VERSION ""

NS_ :

BS_:

BU_: FUSION ZONE_FR ZONE_DR DKC BodyZone_DR BodyZone_PS DataCenter ZONE_ML ZONE_MR

BO_ 778 zGW_CANFr1: 32 ZONE_FR
 SG_ EAC_Temp : 39|8@0+ (1,-40) [0|210] "Deg^C" FUSION
 SG_ EAC_DrvVoltFalt : 63|1@0+ (1,0) [0|1] "" FUSION
 SG_ EAC_MotorLackFalt : 62|1@0+ (1,0) [0|1] "" FUSION
 SG_ EAC_OvLoadFalt : 61|1@0+ (1,0) [0|1] "" FUSION
 SG_ EAC_TempSnsrFalt : 60|1@0+ (1,0) [0|1] "" FUSION
 SG_ COMP_ComLost : 58|1@0+ (1,0) [0|1] "" FUSION
 SG_ COMP_IPM_HWFLt : 57|1@0+ (1,0) [0|1] "" FUSION
 SG_ COMP_IPM_TempOverFlt : 56|1@0+ (1,0) [0|1] "" FUSION
 SG_ COMP_CurOverProtect : 71|1@0+ (1,0) [0|1] "" FUSION
 SG_ COMP_VoltOverErr : 70|1@0+ (1,0) [0|1] "" FUSION
 SG_ COMP_VoltLessErr : 69|1@0+ (1,0) [0|1] "" FUSION
 SG_ COMP_CtrlCircFlt : 68|1@0+ (1,0) [0|1] "" FUSION
 SG_ COMP_Sta : 67|2@0+ (1,0) [0|3] "" FUSION
 SG_ COMP_Init : 65|1@0+ (1,0) [0|1] "" FUSION
 SG_ COMP_SpdVaild : 64|1@0+ (1,0) [0|1] "" FUSION
 SG_ EAC_MotCrt : 79|8@0+ (0.2,0) [0|51] "A" FUSION
 SG_ COMP_CurVaild : 87|1@0+ (1,0) [0|1] "" FUSION
 SG_ COMP_VoltVaild : 86|1@0+ (1,0) [0|1] "" FUSION
 SG_ COMP_StatorSpd : 85|14@0+ (1,0) [0|8500] "RPM" FUSION
 SG_ COMP_ConCur : 103|16@0+ (0.02,0) [0|1310.7] "A" FUSION
 SG_ COMP_ConVolt : 119|16@0+ (0.02,0) [0|1310.7] "V" FUSION
 SG_ COMP_ActualPwr : 228|13@0+ (1,0) [0|6000] "W" FUSION
 SG_ PTC1_PowerConsumption : 31|8@0+ (0.1,0) [0|25.3] "KW" FUSION
 SG_ PTC1_IGBTTem : 7|8@0+ (1,-40) [-40|213] "Deg^C" FUSION
 SG_ PTC1_ClntTempOtlt : 15|8@0+ (1,-40) [-40|100] "Deg^C" FUSION
 SG_ PTC1_ClntTempInlt : 23|8@0+ (1,-40) [-40|100] "Deg^C" FUSION
 SG_ PTC1_ActuHiCrnt : 47|8@0+ (0.25,0) [0|63.25] "A" FUSION
 SG_ PTC1_WrkngSts : 55|2@0+ (1,0) [0|3] "" FUSION
 SG_ PTC1_ClntInltOverTemProtn : 53|1@0+ (1,0) [0|1] "" FUSION
 SG_ PTC1_ClntInltTemSnsrFlt : 52|1@0+ (1,0) [0|1] "" FUSION
 SG_ PTC1_ClntOtltOverTemProtn : 51|1@0+ (1,0) [0|1] "" FUSION
 SG_ PTC1_ClntOtltTemSnsrFlt : 50|1@0+ (1,0) [0|1] "" FUSION
 SG_ PTC1_CommError : 49|1@0+ (1,0) [0|1] "" FUSION
 SG_ PTC1_CoreOrIGBTOpenErr : 48|1@0+ (1,0) [0|1] "" FUSION
 SG_ PTC1_HiCrntSnsrFlt : 59|1@0+ (1,0) [0|1] "" FUSION
 SG_ PTC1_HVDisconnectProtn : 135|1@0+ (1,0) [0|1] "" FUSION
 SG_ PTC1_HVOverCrntProtn : 134|1@0+ (1,0) [0|1] "" FUSION
 SG_ PTC1_IGBTOverTemProtn : 133|1@0+ (1,0) [0|1] "" FUSION
 SG_ PTC1_IGBTShrtErr : 132|1@0+ (1,0) [0|1] "" FUSION
 SG_ PTC1_IGBTTemSnsrFlt : 131|1@0+ (1,0) [0|1] "" FUSION
 SG_ PTC1_MmryFlt : 130|1@0+ (1,0) [0|1] "" FUSION
 SG_ PTC1_PCBOverTempProtn : 129|1@0+ (1,0) [0|1] "" FUSION
 SG_ PTC1_PCBTempSnsrFlt : 128|1@0+ (1,0) [0|1] "" FUSION
 SG_ PTC1_VbatVtgProtn : 143|1@0+ (1,0) [0|1] "" FUSION
 SG_ PTC1_VbatVtgSnsrFlt : 142|1@0+ (1,0) [0|1] "" FUSION
 SG_ PTC1_VbatVtgUnstable : 141|1@0+ (1,0) [0|1] "" FUSION

BO_ 804 zGW_LINDr2: 48 ZONE_DR
 SG_ ACT5_Stop_mode_status : 71|2@0+ (1,0) [0|3] "" FUSION
 SG_ ACT5_Rotation_direction_status : 69|2@0+ (1,0) [0|3] "" FUSION
 SG_ ACT5_Emergency_run_position_status : 67|2@0+ (1,0) [0|3] "" FUSION
 SG_ ACT5_Emergency_run_release_status : 65|2@0+ (1,0) [0|3] "" FUSION
 SG_ ACT5_Actuator_address_status : 79|8@0+ (1,0) [0|255] "" FUSION
 SG_ ACT5_Special_functions : 85|2@0+ (1,0) [0|3] "" FUSION
 SG_ ACT5_Self_holding_torque : 83|2@0+ (1,0) [0|3] "" FUSION
 SG_ ACT5_Movement_direction : 81|2@0+ (1,0) [0|3] "" FUSION
 SG_ ACT5_Actual_position_of_actuator : 95|16@0+ (1,0) [0|65535] "" FUSION
 SG_ ACT5_Speed_status : 111|4@0+ (1,0) [0|15] "" FUSION
 SG_ ACT5_Position_specification_status : 107|2@0+ (1,0) [0|3] "" FUSION
 SG_ ACT5_Applied_holding_current_status : 105|2@0+ (1,0) [0|3] "" FUSION
 SG_ ACT5_Reset : 119|2@0+ (1,0) [0|3] "" FUSION
 SG_ ACT5_Stall_occurred : 117|2@0+ (1,0) [0|3] "" FUSION
 SG_ ACT5_Stall_detection_release_status : 115|2@0+ (1,0) [0|3] "" FUSION
 SG_ ACT5_Emergency_run_occurred : 113|2@0+ (1,0) [0|3] "" FUSION
 SG_ ACT5_Supply_voltage : 127|2@0+ (1,0) [0|3] "" FUSION
 SG_ ACT5_Electrical_defect : 125|2@0+ (1,0) [0|3] "" FUSION
 SG_ ACT5_Over_temperature : 123|2@0+ (1,0) [0|3] "" FUSION
 SG_ ACT5_Response_Error : 120|1@0+ (1,0) [0|1] "" FUSION
 SG_ ACT4_Stop_mode_status : 135|2@0+ (1,0) [0|3] "" FUSION
 SG_ ACT4_Rotation_direction_status : 133|2@0+ (1,0) [0|3] "" FUSION
 SG_ ACT4_Emergency_run_position_status : 131|2@0+ (1,0) [0|3] "" FUSION
 SG_ ACT4_Emergency_run_release_status : 129|2@0+ (1,0) [0|3] "" FUSION
 SG_ ACT4_Actuator_address_status : 143|8@0+ (1,0) [0|255] "" FUSION
 SG_ ACT4_Special_functions : 149|2@0+ (1,0) [0|3] "" FUSION
 SG_ ACT4_Self_holding_torque : 147|2@0+ (1,0) [0|3] "" FUSION
 SG_ ACT4_Movement_direction : 145|2@0+ (1,0) [0|3] "" FUSION
 SG_ ACT4_Actual_position_of_actuator : 159|16@0+ (1,0) [0|65535] "" FUSION
 SG_ ACT4_Speed_status : 175|4@0+ (1,0) [0|15] "" FUSION
 SG_ ACT4_Position_specification_status : 171|2@0+ (1,0) [0|3] "" FUSION
 SG_ ACT4_Applied_holding_current_status : 169|2@0+ (1,0) [0|3] "" FUSION
 SG_ ACT4_Reset : 183|2@0+ (1,0) [0|3] "" FUSION
 SG_ ACT4_Stall_occurred : 181|2@0+ (1,0) [0|3] "" FUSION
 SG_ ACT4_Stall_detection_release_status : 179|2@0+ (1,0) [0|3] "" FUSION
 SG_ ACT4_Emergency_run_occurred : 177|2@0+ (1,0) [0|3] "" FUSION
 SG_ ACT4_Supply_voltage : 191|2@0+ (1,0) [0|3] "" FUSION
 SG_ ACT4_Electrical_defect : 189|2@0+ (1,0) [0|3] "" FUSION
 SG_ ACT4_Over_temperature : 187|2@0+ (1,0) [0|3] "" FUSION
 SG_ ACT4_Response_Error : 184|1@0+ (1,0) [0|1] "" FUSION
 SG_ ACT3_Stop_mode_status : 199|2@0+ (1,0) [0|3] "" FUSION
 SG_ ACT3_Rotation_direction_status : 197|2@0+ (1,0) [0|3] "" FUSION
 SG_ ACT3_Emergency_run_position_status : 195|2@0+ (1,0) [0|3] "" FUSION
 SG_ ACT3_Emergency_run_release_status : 193|2@0+ (1,0) [0|3] "" FUSION
 SG_ ACT3_Actuator_address_status : 207|8@0+ (1,0) [0|255] "" FUSION
 SG_ ACT3_Special_functions : 213|2@0+ (1,0) [0|3] "" FUSION
 SG_ ACT3_Self_holding_torque : 211|2@0+ (1,0) [0|3] "" FUSION
 SG_ ACT3_Movement_direction : 209|2@0+ (1,0) [0|3] "" FUSION
 SG_ ACT3_Actual_position_of_actuator : 223|16@0+ (1,0) [0|65535] "" FUSION
 SG_ ACT3_Speed_status : 239|4@0+ (1,0) [0|15] "" FUSION
 SG_ ACT3_Position_specification_status : 235|2@0+ (1,0) [0|3] "" FUSION
 SG_ ACT3_Applied_holding_current_status : 233|2@0+ (1,0) [0|3] "" FUSION
 SG_ ACT3_Reset : 247|2@0+ (1,0) [0|3] "" FUSION
 SG_ ACT3_Stall_occurred : 245|2@0+ (1,0) [0|3] "" FUSION
 SG_ ACT3_Stall_detection_release_status : 243|2@0+ (1,0) [0|3] "" FUSION
 SG_ ACT3_Emergency_run_occurred : 241|2@0+ (1,0) [0|3] "" FUSION
 SG_ ACT3_Supply_voltage : 255|2@0+ (1,0) [0|3] "" FUSION
 SG_ ACT3_Electrical_defect : 253|2@0+ (1,0) [0|3] "" FUSION
 SG_ ACT3_Over_temperature : 251|2@0+ (1,0) [0|3] "" FUSION
 SG_ ACT3_Response_Error : 248|1@0+ (1,0) [0|1] "" FUSION
 SG_ ACT2_Stop_mode_status : 263|2@0+ (1,0) [0|3] "" FUSION
 SG_ ACT2_Rotation_direction_status : 261|2@0+ (1,0) [0|3] "" FUSION
 SG_ ACT2_Emergency_run_position_status : 259|2@0+ (1,0) [0|3] "" FUSION
 SG_ ACT2_Emergency_run_release_status : 257|2@0+ (1,0) [0|3] "" FUSION
 SG_ ACT2_Actuator_address_status : 271|8@0+ (1,0) [0|255] "" FUSION
 SG_ ACT2_Special_functions : 277|2@0+ (1,0) [0|3] "" FUSION
 SG_ ACT2_Self_holding_torque : 275|2@0+ (1,0) [0|3] "" FUSION
 SG_ ACT2_Movement_direction : 273|2@0+ (1,0) [0|3] "" FUSION
 SG_ ACT2_Actual_position_of_actuator : 287|16@0+ (1,0) [0|65535] "" FUSION
 SG_ ACT2_Speed_status : 303|4@0+ (1,0) [0|15] "" FUSION
 SG_ ACT2_Position_specification_status : 299|2@0+ (1,0) [0|3] "" FUSION
 SG_ ACT2_Applied_holding_current_status : 297|2@0+ (1,0) [0|3] "" FUSION
 SG_ ACT2_Reset : 311|2@0+ (1,0) [0|3] "" FUSION
 SG_ ACT2_Stall_occurred : 309|2@0+ (1,0) [0|3] "" FUSION
 SG_ ACT2_Stall_detection_release_status : 307|2@0+ (1,0) [0|3] "" FUSION
 SG_ ACT2_Emergency_run_occurred : 305|2@0+ (1,0) [0|3] "" FUSION
 SG_ ACT2_Supply_voltage : 319|2@0+ (1,0) [0|3] "" FUSION
 SG_ ACT2_Electrical_defect : 317|2@0+ (1,0) [0|3] "" FUSION
 SG_ ACT2_Over_temperature : 315|2@0+ (1,0) [0|3] "" FUSION
 SG_ ACT2_Response_Error : 312|1@0+ (1,0) [0|1] "" FUSION
 SG_ ACT1_Stop_mode_status : 327|2@0+ (1,0) [0|3] "" FUSION
 SG_ ACT1_Rotation_direction_status : 325|2@0+ (1,0) [0|3] "" FUSION
 SG_ ACT1_Emergency_run_position_status : 323|2@0+ (1,0) [0|3] "" FUSION
 SG_ ACT1_Emergency_run_release_status : 321|2@0+ (1,0) [0|3] "" FUSION
 SG_ ACT1_Actuator_address_status : 335|8@0+ (1,0) [0|255] "" FUSION
 SG_ ACT1_Special_functions : 341|2@0+ (1,0) [0|3] "" FUSION
 SG_ ACT1_Self_holding_torque : 339|2@0+ (1,0) [0|3] "" FUSION
 SG_ ACT1_Movement_direction : 337|2@0+ (1,0) [0|3] "" FUSION
 SG_ ACT1_Actual_position_of_actuator : 351|16@0+ (1,0) [0|65535] "" FUSION
 SG_ ACT1_Speed_status : 367|4@0+ (1,0) [0|15] "" FUSION
 SG_ ACT1_Position_specification_status : 363|2@0+ (1,0) [0|3] "" FUSION
 SG_ ACT1_Applied_holding_current_status : 361|2@0+ (1,0) [0|3] "" FUSION
 SG_ ACT1_Reset : 375|2@0+ (1,0) [0|3] "" FUSION
 SG_ ACT1_Stall_occurred : 373|2@0+ (1,0) [0|3] "" FUSION
 SG_ ACT1_Stall_detection_release_status : 371|2@0+ (1,0) [0|3] "" FUSION
 SG_ ACT1_Emergency_run_occurred : 369|2@0+ (1,0) [0|3] "" FUSION
 SG_ ACT1_Supply_voltage : 383|2@0+ (1,0) [0|3] "" FUSION
 SG_ ACT1_Electrical_defect : 381|2@0+ (1,0) [0|3] "" FUSION
 SG_ ACT1_Over_temperature : 379|2@0+ (1,0) [0|3] "" FUSION
 SG_ ACT1_Response_Error : 376|1@0+ (1,0) [0|1] "" FUSION

BO_ 965 ZONE_DR_Version: 48 ZONE_DR
 SG_ ZONE_DR_SW_Var1 : 135|8@0+ (1,0) [0|255] "" FUSION
 SG_ ZONE_DR_SW_Country2 : 127|8@0+ (1,0) [0|255] "" FUSION
 SG_ ZONE_DR_SW_Country1 : 119|8@0+ (1,0) [0|255] "" FUSION
 SG_ ZONE_DR_SW_Patch2 : 111|8@0+ (1,0) [0|255] "" FUSION
 SG_ ZONE_DR_SW_Patch1 : 103|8@0+ (1,0) [0|255] "" FUSION
 SG_ ZONE_DR_SW_Minor2 : 95|8@0+ (1,0) [0|255] "" FUSION
 SG_ ZONE_DR_SW_Minor1 : 87|8@0+ (1,0) [0|255] "" FUSION
 SG_ ZONE_DR_SW_Major2 : 79|8@0+ (1,0) [0|255] "" FUSION
 SG_ ZONE_DR_SW_Major1 : 71|8@0+ (1,0) [0|255] "" FUSION
 SG_ ZONE_DR_SW_Controller2 : 63|8@0+ (1,0) [0|255] "" FUSION
 SG_ ZONE_DR_SW_Controller1 : 55|8@0+ (1,0) [0|255] "" FUSION
 SG_ ZONE_DR_SW_CarModel3 : 47|8@0+ (1,0) [0|255] "" FUSION
 SG_ ZONE_DR_SW_CarModel2 : 39|8@0+ (1,0) [0|255] "" FUSION
 SG_ ZONE_DR_SW_CarModel1 : 31|8@0+ (1,0) [0|255] "" FUSION
 SG_ ZONE_DR_HW_Ver3 : 23|8@0+ (1,0) [0|255] "" FUSION
 SG_ ZONE_DR_HW_Ver2 : 15|8@0+ (1,0) [0|255] "" FUSION
 SG_ ZONE_DR_HW_Ver1 : 7|8@0+ (1,0) [0|255] "" FUSION
 SG_ ZONE_DR_SW_dash1 : 191|8@0+ (1,0) [0|255] "" FUSION
 SG_ ZONE_DR_SW_change1 : 199|8@0+ (1,0) [0|255] "" FUSION
 SG_ ZONE_DR_SW_change2 : 207|8@0+ (1,0) [0|255] "" FUSION
 SG_ ZONE_DR_SW_dash2 : 215|8@0+ (1,0) [0|255] "" FUSION
 SG_ ZONE_DR_SW_SHA1 : 223|8@0+ (1,0) [0|255] "" FUSION
 SG_ ZONE_DR_SW_SHA2 : 231|8@0+ (1,0) [0|255] "" FUSION
 SG_ ZONE_DR_SW_SHA3 : 239|8@0+ (1,0) [0|255] "" FUSION
 SG_ ZONE_DR_SW_SHA4 : 247|8@0+ (1,0) [0|255] "" FUSION
 SG_ ZONE_DR_SW_SHA5 : 255|8@0+ (1,0) [0|255] "" FUSION
 SG_ ZONE_DR_SW_SHA6 : 263|8@0+ (1,0) [0|255] "" FUSION
 SG_ ZONE_DR_SW_SHA7 : 271|8@0+ (1,0) [0|255] "" FUSION
 SG_ ZONE_DR_SW_SHA8 : 279|8@0+ (1,0) [0|255] "" FUSION
 SG_ ZONE_DR_SW_Var5 : 183|8@0+ (1,0) [0|255] "" FUSION
 SG_ ZONE_DR_SW_Var4 : 175|8@0+ (1,0) [0|255] "" FUSION
 SG_ ZONE_DR_SW_Var3 : 167|8@0+ (1,0) [0|255] "" FUSION
 SG_ ZONE_DR_SW_Var2 : 159|8@0+ (1,0) [0|255] "" FUSION
 SG_ ZONE_DR_SW_ECUGen2 : 151|8@0+ (1,0) [0|255] "" FUSION
 SG_ ZONE_DR_SW_ECUGen1 : 143|8@0+ (1,0) [0|255] "" FUSION

BO_ 969 ZONE_FR_Version: 48 ZONE_FR
 SG_ ZONE_FR_SW_Var1 : 135|8@0+ (1,0) [0|255] "" FUSION
 SG_ ZONE_FR_SW_Country2 : 127|8@0+ (1,0) [0|255] "" FUSION
 SG_ ZONE_FR_SW_Country1 : 119|8@0+ (1,0) [0|255] "" FUSION
 SG_ ZONE_FR_SW_Patch2 : 111|8@0+ (1,0) [0|255] "" FUSION
 SG_ ZONE_FR_SW_Patch1 : 103|8@0+ (1,0) [0|255] "" FUSION
 SG_ ZONE_FR_SW_Minor2 : 95|8@0+ (1,0) [0|255] "" FUSION
 SG_ ZONE_FR_SW_Minor1 : 87|8@0+ (1,0) [0|255] "" FUSION
 SG_ ZONE_FR_SW_Major2 : 79|8@0+ (1,0) [0|255] "" FUSION
 SG_ ZONE_FR_SW_Major1 : 71|8@0+ (1,0) [0|255] "" FUSION
 SG_ ZONE_FR_SW_Controller2 : 63|8@0+ (1,0) [0|255] "" FUSION
 SG_ ZONE_FR_SW_Controller1 : 55|8@0+ (1,0) [0|255] "" FUSION
 SG_ ZONE_FR_SW_CarModel3 : 47|8@0+ (1,0) [0|255] "" FUSION
 SG_ ZONE_FR_SW_CarModel2 : 39|8@0+ (1,0) [0|255] "" FUSION
 SG_ ZONE_FR_SW_CarModel1 : 31|8@0+ (1,0) [0|255] "" FUSION
 SG_ ZONE_FR_HW_Ver3 : 23|8@0+ (1,0) [0|255] "" FUSION
 SG_ ZONE_FR_HW_Ver2 : 15|8@0+ (1,0) [0|255] "" FUSION
 SG_ ZONE_FR_HW_Ver1 : 7|8@0+ (1,0) [0|255] "" FUSION
 SG_ ZONE_FR_SW_dash1 : 191|8@0+ (1,0) [0|255] "" FUSION
 SG_ ZONE_FR_SW_change1 : 199|8@0+ (1,0) [0|255] "" FUSION
 SG_ ZONE_FR_SW_change2 : 207|8@0+ (1,0) [0|255] "" FUSION
 SG_ ZONE_FR_SW_dash2 : 215|8@0+ (1,0) [0|255] "" FUSION
 SG_ ZONE_FR_SW_SHA1 : 223|8@0+ (1,0) [0|255] "" FUSION
 SG_ ZONE_FR_SW_SHA2 : 231|8@0+ (1,0) [0|255] "" FUSION
 SG_ ZONE_FR_SW_SHA3 : 239|8@0+ (1,0) [0|255] "" FUSION
 SG_ ZONE_FR_SW_SHA4 : 247|8@0+ (1,0) [0|255] "" FUSION
 SG_ ZONE_FR_SW_SHA5 : 255|8@0+ (1,0) [0|255] "" FUSION
 SG_ ZONE_FR_SW_SHA6 : 263|8@0+ (1,0) [0|255] "" FUSION
 SG_ ZONE_FR_SW_SHA7 : 271|8@0+ (1,0) [0|255] "" FUSION
 SG_ ZONE_FR_SW_SHA8 : 279|8@0+ (1,0) [0|255] "" FUSION
 SG_ ZONE_FR_SW_ECUGen2 : 151|8@0+ (1,0) [0|255] "" FUSION
 SG_ ZONE_FR_SW_ECUGen1 : 143|8@0+ (1,0) [0|255] "" FUSION
 SG_ ZONE_FR_SW_Var5 : 183|8@0+ (1,0) [0|255] "" FUSION
 SG_ ZONE_FR_SW_Var4 : 175|8@0+ (1,0) [0|255] "" FUSION
 SG_ ZONE_FR_SW_Var3 : 167|8@0+ (1,0) [0|255] "" FUSION
 SG_ ZONE_FR_SW_Var2 : 159|8@0+ (1,0) [0|255] "" FUSION

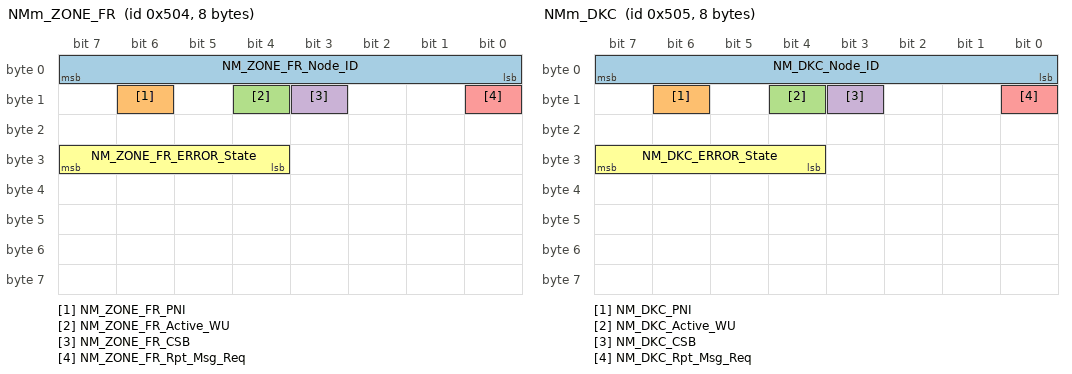
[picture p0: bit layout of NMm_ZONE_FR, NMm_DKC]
BO_ 1284 NMm_ZONE_FR: 8 ZONE_FR
 SG_ NM_ZONE_FR_Node_ID : 7|8@0+ (1,0) [0|127] "" FUSION
 SG_ NM_ZONE_FR_PNI : 14|1@0+ (1,0) [0|1] "" FUSION
 SG_ NM_ZONE_FR_Active_WU : 12|1@0+ (1,0) [0|1] "" FUSION
 SG_ NM_ZONE_FR_CSB : 11|1@0+ (1,0) [0|1] "" FUSION
 SG_ NM_ZONE_FR_Rpt_Msg_Req : 8|1@0+ (1,0) [0|1] "" FUSION
 SG_ NM_ZONE_FR_ERROR_State : 31|4@0+ (1,0) [0|8] "" FUSION

BO_ 1285 NMm_DKC: 8 DKC
 SG_ NM_DKC_Node_ID : 7|8@0+ (1,0) [0|127] "" FUSION
 SG_ NM_DKC_PNI : 14|1@0+ (1,0) [0|1] "" FUSION
 SG_ NM_DKC_Active_WU : 12|1@0+ (1,0) [0|1] "" FUSION
 SG_ NM_DKC_CSB : 11|1@0+ (1,0) [0|1] "" FUSION
 SG_ NM_DKC_Rpt_Msg_Req : 8|1@0+ (1,0) [0|1] "" FUSION
 SG_ NM_DKC_ERROR_State : 31|4@0+ (1,0) [0|8] "" FUSION

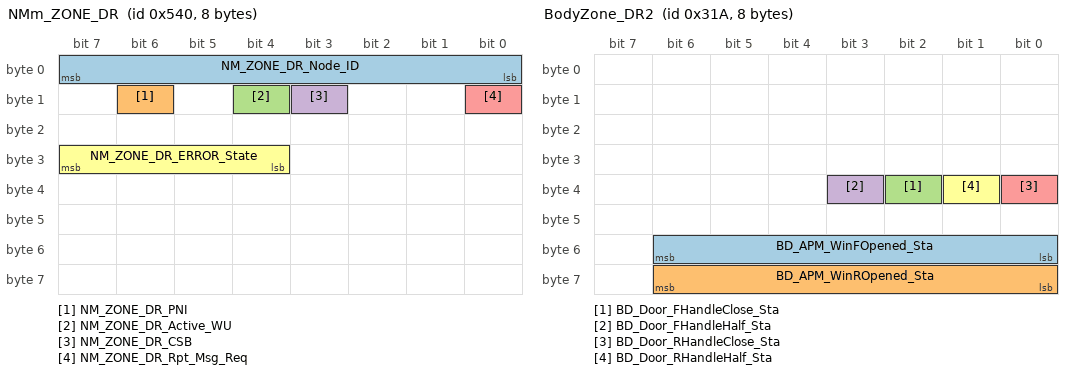
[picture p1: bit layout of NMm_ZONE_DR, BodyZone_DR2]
BO_ 1344 NMm_ZONE_DR: 8 ZONE_DR
 SG_ NM_ZONE_DR_Node_ID : 7|8@0+ (1,0) [0|127] "" FUSION
 SG_ NM_ZONE_DR_PNI : 14|1@0+ (1,0) [0|1] "" FUSION
 SG_ NM_ZONE_DR_Active_WU : 12|1@0+ (1,0) [0|1] "" FUSION
 SG_ NM_ZONE_DR_CSB : 11|1@0+ (1,0) [0|1] "" FUSION
 SG_ NM_ZONE_DR_Rpt_Msg_Req : 8|1@0+ (1,0) [0|1] "" FUSION
 SG_ NM_ZONE_DR_ERROR_State : 31|4@0+ (1,0) [0|8] "" FUSION

BO_ 1540 DiagRespFromZONE_FR: 64 ZONE_FR
 SG_ DiagRespFromZONE_FR : 455|64@0+ (1,0) [0|0] "" FUSION

BO_ 1541 DiagRespFromDKC: 32 DKC
 SG_ DiagRespFromDKC : 7|64@0+ (1,0) [0|0] "" FUSION

BO_ 1573 DiagRespFromAirPTC: 8 ZONE_DR
 SG_ DiagRespFromAirPTC : 7|64@0+ (1,0) [0|0] "" FUSION

BO_ 1589 DiagRespFromWPTC: 8 ZONE_FR
 SG_ DiagRespFromWPTC : 7|64@0+ (1,0) [0|0] "" FUSION

BO_ 1600 DiagRespFromZONE_DR: 64 ZONE_DR
 SG_ DiagRespFromZONE_DR : 455|64@0+ (1,0) [0|0] "" FUSION

BO_ 1605 DiagRespFromCompressor: 8 ZONE_FR
 SG_ DiagRespFromCompress : 7|64@0+ (1,0) [0|0] "" FUSION

BO_ 794 BodyZone_DR2: 8 BodyZone_DR
 SG_ BD_APM_WinFOpened_Sta : 54|7@0+ (1,0) [0|127] "%" FUSION
 SG_ BD_APM_WinROpened_Sta : 62|7@0+ (1,0) [0|127] "%" FUSION
 SG_ BD_Door_FHandleClose_Sta : 34|1@0+ (1,0) [0|1] "" FUSION
 SG_ BD_Door_FHandleHalf_Sta : 35|1@0+ (1,0) [0|1] "" FUSION
 SG_ BD_Door_RHandleClose_Sta : 32|1@0+ (1,0) [0|1] "" FUSION
 SG_ BD_Door_RHandleHalf_Sta : 33|1@0+ (1,0) [0|1] "" FUSION

BO_ 858 BodyZone_DR1: 12 BodyZone_DR
 SG_ BD_DSEAT_SlidPos_Sta : 74|10@0+ (1,0) [0|1023] "Pulse" FUSION
 SG_ BD_DSEAT_RecPos_Sta : 62|11@0+ (1,0) [0|2047] "Pluse" FUSION
 SG_ BD_DSEAT_FLPos_Sta : 55|9@0+ (1,0) [0|511] "Pulse" FUSION
 SG_ BD_DSEAT_RLPos_Sta : 67|9@0+ (1,0) [0|511] "Pulse" FUSION
 SG_ BD_DSEAT_Mode_Sta : 38|3@0+ (1,0) [0|7] "" FUSION
 SG_ BD_DSEAT_AntiAct_Sta : 45|1@0+ (1,0) [0|1] "" FUSION
 SG_ BD_DSEAT_Anti_Sta : 43|1@0+ (1,0) [0|1] "" FUSION
 SG_ BD_DSEAT_EntryAct_Sta : 39|1@0+ (1,0) [0|1] "" FUSION
 SG_ BD_DSEAT_EntryFun_Sta : 44|1@0+ (1,0) [0|1] "" FUSION
 SG_ BD_DSEAT_Error_Sta : 35|1@0+ (1,0) [0|1] "" FUSION
 SG_ BD_DSEAT_Vent_Sta : 34|3@0+ (1,0) [0|4] "" FUSION
 SG_ BD_DSEAT_heater_Sta : 42|3@0+ (1,0) [0|4] "" FUSION
 SG_ BD_DSEAT_MemSet_Sta : 47|2@0+ (1,0) [0|3] "" FUSION
 SG_ BD_DSEAT_StopKeepMove_Sta : 31|2@0+ (1,0) [0|3] "" FUSION

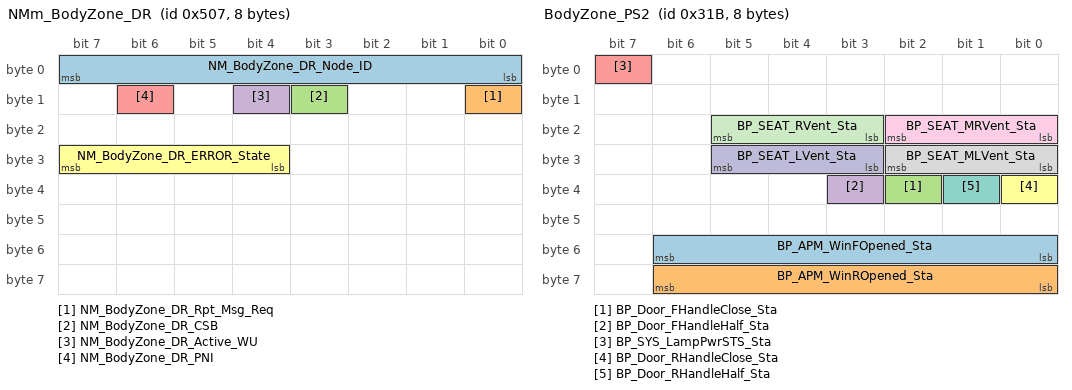
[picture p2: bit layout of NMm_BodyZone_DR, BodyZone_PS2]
BO_ 1287 NMm_BodyZone_DR: 8 BodyZone_DR
 SG_ NM_BodyZone_DR_Node_ID : 7|8@0+ (1,0) [0|127] "" FUSION
 SG_ NM_BodyZone_DR_Rpt_Msg_Req : 8|1@0+ (1,0) [0|1] "" FUSION
 SG_ NM_BodyZone_DR_CSB : 11|1@0+ (1,0) [0|1] "" FUSION
 SG_ NM_BodyZone_DR_Active_WU : 12|1@0+ (1,0) [0|1] "" FUSION
 SG_ NM_BodyZone_DR_PNI : 14|1@0+ (1,0) [0|1] "" FUSION
 SG_ NM_BodyZone_DR_ERROR_State : 31|4@0+ (1,0) [0|8] "" FUSION

BO_ 1543 DiagRespFromBodyZone_DR: 64 BodyZone_DR
 SG_ DiagRespFromBodyZone_DR : 455|64@0+ (1,0) [0|0] "" FUSION

BO_ 859 BodyZone_PS1: 32 BodyZone_PS
 SG_ BP_PTG_PowerLatch_Sta : 23|3@0+ (1,0) [0|7] "" FUSION
 SG_ BP_PTG_DebugMode_Sta : 31|1@0+ (1,0) [0|1] "" FUSION
 SG_ BP_PTG_LatchSeg_Sta : 33|2@0+ (1,0) [0|3] "" FUSION
 SG_ BP_PTG_InsideSW2_Sta : 35|2@0+ (1,0) [0|3] "" FUSION
 SG_ BP_PTG_InsideSW1_Sta : 37|2@0+ (1,0) [0|3] "" FUSION
 SG_ BP_PTG_HalfSW_Sta : 47|1@0+ (1,0) [0|1] "" FUSION
 SG_ BP_PTG_LeftDuty_Sta : 54|7@0+ (1,0) [0|127] "%" FUSION
 SG_ BP_PTG_FullSW_Sta : 55|1@0+ (1,0) [0|1] "" FUSION
 SG_ BP_PTG_RightDuty_Sta : 62|7@0+ (1,0) [0|127] "%" FUSION
 SG_ BP_PTG_NtlSW_Sta : 63|1@0+ (1,0) [0|1] "" FUSION
 SG_ BP_PTG_CinchDuty_Sta : 70|7@0+ (1,0) [0|127] "%" FUSION
 SG_ BP_PTG_StrutThermal_Sta : 71|1@0+ (1,0) [0|1] "" FUSION
 SG_ BP_PTG_LeftCur_Sta : 78|15@0+ (1,0) [0|32767] "mA" FUSION
 SG_ BP_PTG_StrutAntiPinch_Sta : 79|1@0+ (1,0) [0|1] "" FUSION
 SG_ BP_PTG_RightCur_Sta : 94|15@0+ (1,0) [0|32767] "mA" FUSION
 SG_ BP_PTG_StrutStall_Sta : 95|1@0+ (1,0) [0|1] "" FUSION
 SG_ BP_PTG_CinchCur_Sta : 110|15@0+ (1,0) [0|32767] "mA" FUSION
 SG_ BP_PTG_AbuseProtection_Sta : 111|1@0+ (1,0) [0|1] "" FUSION
 SG_ BP_PTG_ReleaseCur_Sta : 126|15@0+ (1,0) [0|32767] "mA" FUSION
 SG_ BP_PTG_LatchThermal_Sta : 127|1@0+ (1,0) [0|1] "" FUSION
 SG_ BP_PTG_LeftHallPosn_Sta : 137|10@0+ (1,0) [0|1023] "" FUSION
 SG_ BP_PTG_ErrLeftStrut_Sta : 139|2@0+ (1,0) [0|3] "" FUSION
 SG_ BP_PTG_ErrVoltage_Sta : 141|2@0+ (1,0) [0|3] "" FUSION
 SG_ BP_PTG_ErrRightStrut_Sta : 143|2@0+ (1,0) [0|3] "" FUSION
 SG_ BP_PTG_RightHallPosn_Sta : 153|10@0+ (1,0) [0|1023] "" FUSION
 SG_ BP_PTG_ErrHall_Sta : 157|2@0+ (1,0) [0|3] "" FUSION
 SG_ BP_PTG_ErrLatch_Sta : 159|2@0+ (1,0) [0|3] "" FUSION
 SG_ BP_PTG_OpenRatio_Sta : 46|7@0+ (1,0) [0|127] "%" FUSION
 SG_ BP_PTG_Active_Sta : 28|3@0+ (1,0) [0|7] "" FUSION
 SG_ BP_PTG_Sys_Sta : 30|2@0+ (1,0) [0|3] "" FUSION
 SG_ BP_PTG_RDIL_Cmd : 39|2@0+ (1,0) [0|3] "" FUSION
 SG_ BP_PTG_IsSetHeight_Sta : 24|1@0+ (1,0) [0|1] "" FUSION
 SG_ BP_PTG_Exist_Sta : 25|1@0+ (1,0) [0|1] "" FUSION
 SG_ BP_PSEAT_Vent_Sta : 182|3@0+ (1,0) [0|4] "" FUSION
 SG_ BP_PSEAT_Mode_Sta : 178|3@0+ (1,0) [0|7] "" FUSION
 SG_ BP_PSEAT_Error_Sta : 179|1@0+ (1,0) [0|1] "" FUSION
 SG_ BP_PSEAT_heater_Sta : 186|3@0+ (1,0) [0|4] "" FUSION

BO_ 1007 BodyZone_PS3: 32 BodyZone_PS
 SG_ BP_APM_WinFCurrent_Sta : 71|8@0+ (0.064,0) [0|16.32] "A" FUSION
 SG_ BP_APM_WinRCurrent_Sta : 79|8@0+ (0.064,0) [0|16.32] "A" FUSION
 SG_ BP_SYS_PowerTemp2_Sta : 7|16@0+ (0.01,-40) [-40|125] "Deg^C" FUSION
 SG_ BP_SYS_PowerTemp1_Sta : 23|16@0+ (0.01,-40) [-40|125] "Deg^C" FUSION
 SG_ BP_SYS_CtrlTemp_Sta : 39|16@0+ (0.01,-40) [-40|125] "Deg^C" FUSION
 SG_ BP_SYS_CtrlBDVolt_Sta : 51|12@0+ (0.01,0) [0|36] "V" FUSION
 SG_ BP_SEAT_HeatCurrent_Sta : 87|8@0+ (0.125,0) [0|31.875] "A" FUSION
 SG_ BP_SEAT_VentCurrent_Sta : 95|8@0+ (0.125,0) [0|31.875] "A" FUSION
 SG_ BP_Door_RCurrent_Sta : 103|8@0+ (0.125,0) [0|31.875] "A" FUSION
 SG_ BP_Door_FCurrent_Sta : 111|8@0+ (0.125,0) [0|31.875] "A" FUSION
 SG_ BP_SEAT_ReclineCurrent_Sta : 119|8@0+ (0.125,0) [0|31.875] "A" FUSION
 SG_ BP_SEAT_SlideCurrent_Sta : 127|8@0+ (0.125,0) [0|31.875] "A" FUSION
 SG_ BP_PSEAT_HeaterTemp_Sta : 135|8@0+ (0.5,-30) [-30|97.5] "Deg^C" FUSION
 SG_ BP_PTG_ACTRLatchCur_Sta : 143|8@0+ (0.125,0) [0|31.875] "A" FUSION

BO_ 971 BodyZone_PS_Version: 48 BodyZone_PS
 SG_ BP_SW_ECUGen2 : 151|8@0+ (1,0) [0|255] "" FUSION
 SG_ BP_SW_ECUGen1 : 143|8@0+ (1,0) [0|255] "" FUSION
 SG_ BP_SW_Var5 : 183|8@0+ (1,0) [0|255] "" FUSION
 SG_ BP_SW_Var4 : 175|8@0+ (1,0) [0|255] "" FUSION
 SG_ BP_SW_Var3 : 167|8@0+ (1,0) [0|255] "" FUSION
 SG_ BP_SW_Var2 : 159|8@0+ (1,0) [0|255] "" FUSION

BO_ 795 BodyZone_PS2: 8 BodyZone_PS
 SG_ BP_APM_WinFOpened_Sta : 54|7@0+ (1,0) [0|127] "%" FUSION
 SG_ BP_APM_WinROpened_Sta : 62|7@0+ (1,0) [0|127] "%" FUSION
 SG_ BP_Door_FHandleClose_Sta : 34|1@0+ (1,0) [0|1] "" FUSION
 SG_ BP_Door_FHandleHalf_Sta : 35|1@0+ (1,0) [0|1] "" FUSION
 SG_ BP_SYS_LampPwrSTS_Sta : 7|1@0+ (1,0) [0|1] "" FUSION
 SG_ BP_Door_RHandleClose_Sta : 32|1@0+ (1,0) [0|1] "" FUSION
 SG_ BP_Door_RHandleHalf_Sta : 33|1@0+ (1,0) [0|1] "" FUSION
 SG_ BP_SEAT_MLVent_Sta : 26|3@0+ (1,0) [0|7] "" FUSION
 SG_ BP_SEAT_MRVent_Sta : 18|3@0+ (1,0) [0|7] "" FUSION
 SG_ BP_SEAT_LVent_Sta : 29|3@0+ (1,0) [0|7] "" FUSION
 SG_ BP_SEAT_RVent_Sta : 21|3@0+ (1,0) [0|7] "" FUSION

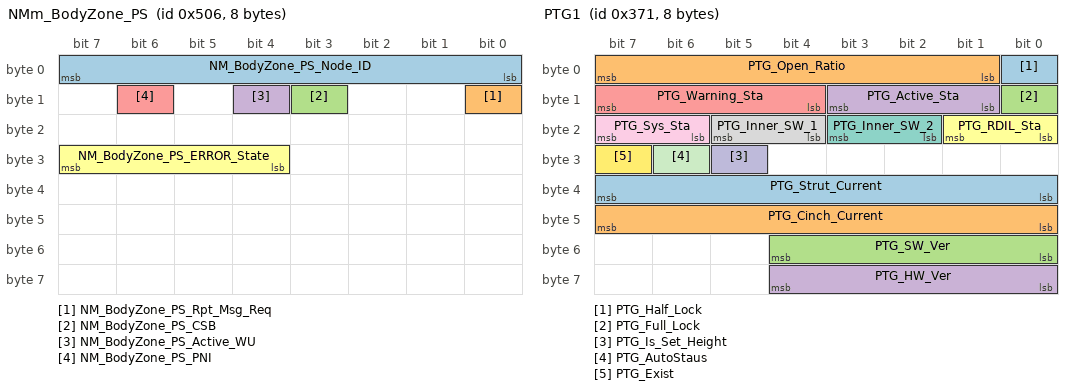
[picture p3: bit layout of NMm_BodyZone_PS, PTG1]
BO_ 1286 NMm_BodyZone_PS: 8 BodyZone_PS
 SG_ NM_BodyZone_PS_Node_ID : 7|8@0+ (1,0) [0|127] "" FUSION
 SG_ NM_BodyZone_PS_Rpt_Msg_Req : 8|1@0+ (1,0) [0|1] "" FUSION
 SG_ NM_BodyZone_PS_CSB : 11|1@0+ (1,0) [0|1] "" FUSION
 SG_ NM_BodyZone_PS_Active_WU : 12|1@0+ (1,0) [0|1] "" FUSION
 SG_ NM_BodyZone_PS_PNI : 14|1@0+ (1,0) [0|1] "" FUSION
 SG_ NM_BodyZone_PS_ERROR_State : 31|4@0+ (1,0) [0|8] "" FUSION

BO_ 1542 DiagRespFromBodyZone_PS: 64 BodyZone_PS
 SG_ DiagRespFromBodyZone_PS : 455|64@0+ (1,0) [0|0] "" FUSION

BO_ 1671 DiagPhysReqToBodyZone_DR: 64 FUSION
 SG_ DiagPhysReqToBodyZone_DR : 7|64@0+ (1,0) [0|0] "" BodyZone_DR

BO_ 1670 DiagPhysReqToBodyZone_PS: 64 FUSION
 SG_ DiagPhysReqToBodyZone_PS : 7|64@0+ (1,0) [0|0] "" BodyZone_PS

BO_ 376 FCM2: 32 FUSION
 SG_ FCM2_Checksum : 7|8@0+ (1,0) [0|255] "" ZONE_FR
 SG_ FCM2_LifeCount : 11|4@0+ (1,0) [0|14] "" ZONE_FR
 SG_ ADB_ILLAmbtSta : 17|2@0+ (1,0) [0|3] "" ZONE_FR
 SG_ ADB_VehNumVal : 21|4@0+ (1,0) [0|15] "" ZONE_FR
 SG_ ADB_FR_CMR_Sta : 23|2@0+ (1,0) [0|3] "" ZONE_FR
 SG_ ADB_VehLtAngl1Val : 31|9@0+ (0.1,-25) [-25|25] "Deg" ZONE_FR
 SG_ ADB_VehRtAngl1Val : 38|9@0+ (0.1,-25) [-25|25] "Deg" ZONE_FR
 SG_ ADB_VehLtAngl2Val : 45|9@0+ (0.1,-25) [-25|25] "Deg" ZONE_FR
 SG_ ADB_VehRtAngl2Val : 52|9@0+ (0.1,-25) [-25|25] "Deg" ZONE_FR
 SG_ ADB_VehLtAngl3Val : 59|9@0+ (0.1,-25) [-25|25] "Deg" ZONE_FR
 SG_ ADB_VehRtAngl3Val : 66|9@0+ (0.1,-25) [-25|25] "Deg" ZONE_FR
 SG_ ADB_VehLtAngl4Val : 73|9@0+ (0.1,-25) [-25|25] "Deg" ZONE_FR
 SG_ ADB_VehRtAngl4Val : 80|9@0+ (0.1,-25) [-25|25] "Deg" ZONE_FR
 SG_ ADB_VehLtAngl5Val : 103|9@0+ (0.1,-25) [-25|25] "Deg" ZONE_FR
 SG_ ADB_VehRtAngl5Val : 110|9@0+ (0.1,-25) [-25|25] "Deg" ZONE_FR
 SG_ ADB_VehLtAngl6Val : 117|9@0+ (0.1,-25) [-25|25] "Deg" ZONE_FR
 SG_ ADB_VehRtAngl6Val : 124|9@0+ (0.1,-25) [-25|25] "Deg" ZONE_FR
 SG_ ADB_VehLtAngl7Val : 131|9@0+ (0.1,-25) [-25|25] "Deg" ZONE_FR
 SG_ ADB_VehRtAngl7Val : 138|9@0+ (0.1,-25) [-25|25] "Deg" ZONE_FR
 SG_ ADB_VehLtAngl8Val : 145|9@0+ (0.1,-25) [-25|25] "Deg" ZONE_FR
 SG_ ADB_VehRtAngl8Val : 152|9@0+ (0.1,-25) [-25|25] "Deg" ZONE_FR
 SG_ ADB_VehLtAngl9Val : 175|9@0+ (0.1,-25) [-25|25] "Deg" ZONE_FR
 SG_ ADB_VehRtAngl9Val : 182|9@0+ (0.1,-25) [-25|25] "Deg" ZONE_FR
 SG_ ADB_VehLtAngl10Val : 189|9@0+ (0.1,-25) [-25|25] "Deg" ZONE_FR
 SG_ ADB_VehRtAngl10Val : 196|9@0+ (0.1,-25) [-25|25] "Deg" ZONE_FR
 SG_ ADB_VehDst1Val : 203|4@0+ (1,0) [0|15] "" ZONE_FR
 SG_ ADB_VehDst3Val : 211|4@0+ (1,0) [0|15] "" ZONE_FR
 SG_ ADB_VehDst2Val : 215|4@0+ (1,0) [0|15] "" ZONE_FR
 SG_ ADB_VehDst5Val : 219|4@0+ (1,0) [0|15] "" ZONE_FR
 SG_ ADB_VehDst4Val : 223|4@0+ (1,0) [0|15] "" ZONE_FR
 SG_ ADB_VehDst7Val : 227|4@0+ (1,0) [0|15] "" ZONE_FR
 SG_ ADB_VehDst6Val : 231|4@0+ (1,0) [0|15] "" ZONE_FR
 SG_ ADB_VehDst9Val : 235|4@0+ (1,0) [0|15] "" ZONE_FR
 SG_ ADB_VehDst8Val : 239|4@0+ (1,0) [0|15] "" ZONE_FR
 SG_ ADB_VehDst10Val : 247|4@0+ (1,0) [0|15] "" ZONE_FR

BO_ 970 BodyZone_DR_Version: 48 BodyZone_DR
 SG_ BD_SW_ECUGen2 : 151|8@0+ (1,0) [0|255] "" FUSION
 SG_ BD_SW_ECUGen1 : 143|8@0+ (1,0) [0|255] "" FUSION
 SG_ BD_SW_Var4 : 175|8@0+ (1,0) [0|255] "" FUSION
 SG_ BD_SW_Var3 : 167|8@0+ (1,0) [0|255] "" FUSION
 SG_ BD_SW_Var2 : 159|8@0+ (1,0) [0|255] "" FUSION
 SG_ BD_SW_Var5 : 183|8@0+ (1,0) [0|255] "" FUSION

BO_ 1734 DiagPhysReqToLDM_RL: 64 FUSION
 SG_ DiagPhysReqToLDM_RL : 7|64@0+ (1,0) [0|0] "" ZONE_DR

BO_ 1718 DiagPhysReqToLDM_RR: 64 FUSION
 SG_ DiagPhysReqToLDM_RR : 7|64@0+ (1,0) [0|0] "" ZONE_DR

BO_ 1702 DiagPhysReqToLDM_FL: 64 FUSION
 SG_ DiagPhysReqToLDM_FL : 7|64@0+ (1,0) [0|0] "" ZONE_FR

BO_ 1686 DiagPhysReqToLDM_FR: 64 FUSION
 SG_ DiagPhysReqToLDM_FR : 7|64@0+ (1,0) [0|0] "" ZONE_FR

BO_ 1574 DiagRespFromLDM_FL: 64 ZONE_FR
 SG_ DiagRespFromLDM_FL : 7|64@0+ (1,0) [0|0] "" FUSION

BO_ 1558 DiagRespFromLDM_FR: 64 ZONE_FR
 SG_ DiagRespFromLDM_FR : 7|64@0+ (1,0) [0|0] "" FUSION

BO_ 1606 DiagRespFromLDM_RL: 64 ZONE_DR
 SG_ DiagRespFromLDM_RL : 7|64@0+ (1,0) [0|0] "" FUSION

BO_ 1590 DiagRespFromLDM_RR: 64 ZONE_DR
 SG_ DiagRespFromLDM_RR : 7|64@0+ (1,0) [0|0] "" FUSION

BO_ 881 PTG1: 8 ZONE_DR
 SG_ PTG_Half_Lock : 0|1@0+ (1,0) [0|1] "" FUSION
 SG_ PTG_Open_Ratio : 7|7@0+ (1,0) [0|127] "%" FUSION
 SG_ PTG_Full_Lock : 8|1@0+ (1,0) [0|1] "" FUSION
 SG_ PTG_Active_Sta : 11|3@0+ (1,0) [0|7] "" FUSION
 SG_ PTG_Warning_Sta : 15|4@0+ (1,0) [0|15] "" FUSION
 SG_ PTG_RDIL_Sta : 17|2@0+ (1,0) [0|3] "" FUSION
 SG_ PTG_Inner_SW_2 : 19|2@0+ (1,0) [0|3] "" FUSION
 SG_ PTG_Inner_SW_1 : 21|2@0+ (1,0) [0|3] "" FUSION
 SG_ PTG_Sys_Sta : 23|2@0+ (1,0) [0|3] "" FUSION
 SG_ PTG_Is_Set_Height : 29|1@0+ (1,0) [0|1] "" FUSION
 SG_ PTG_AutoStaus : 30|1@0+ (1,0) [0|1] "" FUSION
 SG_ PTG_Exist : 31|1@0+ (1,0) [0|1] "" FUSION
 SG_ PTG_Strut_Current : 39|8@0+ (0.1,0) [0|25.5] "A" FUSION
 SG_ PTG_Cinch_Current : 47|8@0+ (0.1,0) [0|25.5] "A" FUSION
 SG_ PTG_SW_Ver : 52|5@0+ (1,0) [0|31] "" FUSION
 SG_ PTG_HW_Ver : 60|5@0+ (1,0) [0|31] "" FUSION

BO_ 1684 DiagPhysReqToDSEAT: 8 FUSION
 SG_ DiagPhysReqToDSEAT : 7|64@0+ (1,0) [0|0] "" ZONE_DR

BO_ 1700 DiagPhysReqToPSEAT: 8 FUSION
 SG_ DiagPhysReqToPSEAT : 7|64@0+ (1,0) [0|0] "" ZONE_DR

BO_ 1716 DiagPhysReqToPTG: 8 FUSION
 SG_ DiagPhysReqToPTG : 7|64@0+ (1,0) [0|0] "" ZONE_DR

BO_ 1556 DiagRespFromDSEAT: 8 ZONE_DR
 SG_ DiagRespFromDSEAT : 7|64@0+ (1,0) [0|0] "" FUSION

BO_ 1572 DiagRespFromPSEAT: 8 ZONE_DR
 SG_ DiagRespFromPSEAT : 7|64@0+ (1,0) [0|0] "" FUSION

BO_ 1588 DiagRespFromPTG: 8 ZONE_DR
 SG_ DiagRespFromPTG : 7|64@0+ (1,0) [0|0] "" FUSION

BO_ 854 zGW_SEAT1: 16 ZONE_DR
 SG_ PSEAT_SW_Ver : 119|16@0+ (1,0) [0|65535] "" FUSION
 SG_ PSEAT_HW_Ver : 103|16@0+ (1,0) [0|65535] "" FUSION
 SG_ DSEAT_SW_Ver : 87|16@0+ (1,0) [0|65535] "" FUSION
 SG_ DSEAT_HW_Ver : 71|16@0+ (1,0) [0|65535] "" FUSION
 SG_ DSEAT_Slid_Pos : 15|8@0+ (1,0) [0|240] "mm" FUSION
 SG_ DSEAT_RL_Pos : 23|8@0+ (1,0) [0|60] "mm" FUSION
 SG_ DSEAT_Rec_Pos : 31|8@0+ (1,0) [0|80] "Deg" FUSION
 SG_ DSEAT_FL_Pos : 7|8@0+ (1,0) [0|25] "mm" FUSION
 SG_ DSEAT_heater_sta : 44|3@0+ (1,0) [0|4] "" FUSION
 SG_ DSEAT_Mode : 39|3@0+ (1,0) [0|7] "" FUSION
 SG_ DSEAT_Vent_Sta : 36|3@0+ (1,0) [0|4] "" FUSION
 SG_ PSEAT_heater_sta : 47|3@0+ (1,0) [0|4] "" FUSION
 SG_ PSEAT_Mode : 55|3@0+ (1,0) [0|7] "" FUSION
 SG_ PSEAT_Vent_Sta : 52|3@0+ (1,0) [0|4] "" FUSION
 SG_ DSEAT_AntiAct_Sta : 33|1@0+ (1,0) [0|1] "" FUSION
 SG_ DSEAT_Anti_Sta : 32|1@0+ (1,0) [0|1] "" FUSION
 SG_ DSEAT_EntryAct_Sta : 41|1@0+ (1,0) [0|1] "" FUSION
 SG_ DSEAT_EntryFun_Sta : 40|1@0+ (1,0) [0|1] "" FUSION
 SG_ DSEAT_Error_Sta : 48|1@0+ (1,0) [0|1] "" FUSION
 SG_ PSEAT_Error_Sta : 49|1@0+ (1,0) [0|1] "" FUSION

BO_ 630 BMS5: 12 FUSION
 SG_ DCPortNeg_Temp : 7|8@0+ (1,-50) [-50|150] "Deg^C" Vector__XXX
 SG_ DCPortPos_Temp : 15|8@0+ (1,-50) [-50|150] "Deg^C" Vector__XXX
 SG_ OBCACCSLimit : 23|8@0+ (1,0) [0|80] "A" Vector__XXX
 SG_ HVInVolt : 28|13@0+ (0.1,0) [0|819] "V" ZONE_DR
 SG_ OBCDCVoltLm : 44|13@0+ (0.1,0) [0|819] "V" ZONE_DR
 SG_ OBCDCCurLm : 57|10@0+ (0.1,-25.5) [-25.5|76.7] "A" ZONE_DR
 SG_ ReChargerStaFromEvcc : 59|2@0+ (1,0) [0|3] "" ZONE_DR
 SG_ OBCEna : 60|1@0+ (1,0) [0|1] "" Vector__XXX
 SG_ LVBattDet12V : 79|8@0+ (0.1,0) [0|25.4] "V" ZONE_DR,DKC

BO_ 1006 BodyZone_DR3: 32 BodyZone_DR
 SG_ BD_APM_WinRCurrent_Sta : 79|8@0+ (0.064,0) [0|16.32] "A" FUSION
 SG_ BD_APM_WinFCurrent_Sta : 71|8@0+ (0.064,0) [0|16.32] "A" FUSION
 SG_ BD_SYS_PowerTemp2_Sta : 7|16@0+ (0.01,-40) [-40|125] "Deg^C" FUSION
 SG_ BD_SYS_PowerTemp1_Sta : 23|16@0+ (0.01,-40) [-40|125] "Deg^C" FUSION
 SG_ BD_SYS_CtrlTemp_Sta : 39|16@0+ (0.01,-40) [-40|125] "Deg^C" FUSION
 SG_ BD_SYS_CtrlBDVolt_Sta : 51|12@0+ (0.01,0) [0|36] "V" FUSION
 SG_ BD_SEAT_VentCurrent_Sta : 87|8@0+ (0.125,0) [0|31.875] "A" FUSION
 SG_ BD_SEAT_HeatCurrent_Sta : 95|8@0+ (0.125,0) [0|31.875] "A" FUSION
 SG_ BD_SEAT_FrontLiftCurrent_Sta : 103|8@0+ (0.125,0) [0|31.875] "A" FUSION
 SG_ BD_SEAT_RearLiftCurrent_Sta : 119|8@0+ (0.125,0) [0|31.875] "A" FUSION
 SG_ BD_SEAT_ReclineCurrent_Sta : 127|8@0+ (0.125,0) [0|31.875] "A" FUSION
 SG_ BD_SEAT_SlideCurrent_Sta : 135|8@0+ (0.125,0) [0|31.875] "A" FUSION
 SG_ BD_Door_RCurrent_Sta : 143|8@0+ (0.125,0) [0|31.875] "A" FUSION
 SG_ BD_Door_FCurrent_Sta : 151|8@0+ (0.125,0) [0|31.875] "A" FUSION
 SG_ BD_DSEAT_HeaterTemp_Sta : 159|8@0+ (0.5,-30) [-30|97.5] "Deg^C" FUSION

BO_ 928 FD4_CE100_2: 32 FUSION
 SG_ FDC_VCU_ReqHWReset_Cmd : 20|5@0+ (1,0) [0|31] "" ZONE_FR,ZONE_DR
 SG_ FD4_CE100_2_CS : 7|8@0+ (1,0) [0|255] "" ZONE_FR,ZONE_DR
 SG_ FD4_CE100_2_RC : 11|4@0+ (1,0) [0|14] "" ZONE_FR,ZONE_DR

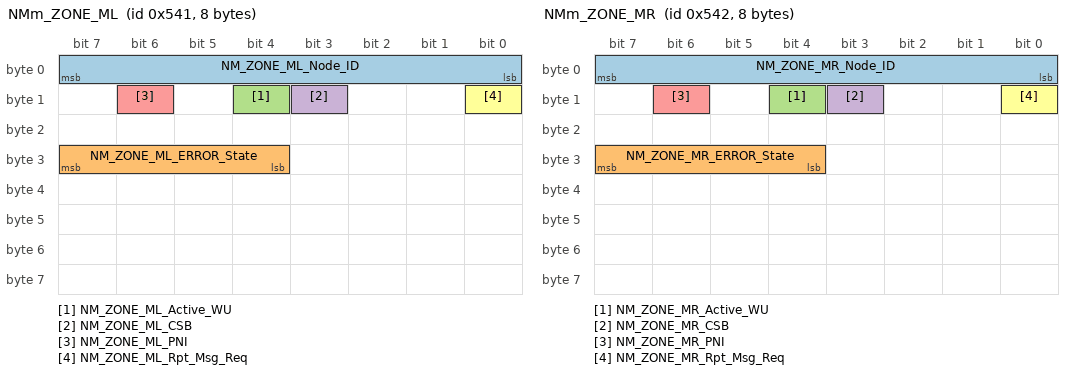
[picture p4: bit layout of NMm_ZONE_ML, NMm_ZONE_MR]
BO_ 1345 NMm_ZONE_ML: 8 ZONE_ML
 SG_ NM_ZONE_ML_Node_ID : 7|8@0+ (1,0) [0|127] "" FUSION
 SG_ NM_ZONE_ML_ERROR_State : 31|4@0+ (1,0) [0|8] "" FUSION
 SG_ NM_ZONE_ML_Active_WU : 12|1@0+ (1,0) [0|1] "" FUSION
 SG_ NM_ZONE_ML_CSB : 11|1@0+ (1,0) [0|1] "" FUSION
 SG_ NM_ZONE_ML_PNI : 14|1@0+ (1,0) [0|1] "" FUSION
 SG_ NM_ZONE_ML_Rpt_Msg_Req : 8|1@0+ (1,0) [0|1] "" FUSION

BO_ 1346 NMm_ZONE_MR: 8 ZONE_MR
 SG_ NM_ZONE_MR_Node_ID : 7|8@0+ (1,0) [0|127] "" FUSION
 SG_ NM_ZONE_MR_ERROR_State : 31|4@0+ (1,0) [0|8] "" FUSION
 SG_ NM_ZONE_MR_Active_WU : 12|1@0+ (1,0) [0|1] "" FUSION
 SG_ NM_ZONE_MR_CSB : 11|1@0+ (1,0) [0|1] "" FUSION
 SG_ NM_ZONE_MR_PNI : 14|1@0+ (1,0) [0|1] "" FUSION
 SG_ NM_ZONE_MR_Rpt_Msg_Req : 8|1@0+ (1,0) [0|1] "" FUSION

BO_ 1729 DiagPhysReqToZONE_ML: 64 FUSION
 SG_ DiagPhysReqToZONE_ML : 7|64@0+ (1,0) [0|0] "" ZONE_ML

BO_ 1730 DiagPhysReqToZONE_MR: 64 FUSION
 SG_ DiagPhysReqToZONE_MR : 7|64@0+ (1,0) [0|0] "" ZONE_MR

BO_ 1601 DiagRespFromZONE_ML: 64 ZONE_ML
 SG_ DiagRespFromZONE_ML : 7|64@0+ (1,0) [0|0] "" FUSION

BO_ 1602 DiagRespFromZONE_MR: 64 ZONE_MR
 SG_ DiagRespFromZONE_MR : 7|64@0+ (1,0) [0|0] "" FUSION

BO_ 597 GW4_CE200_0: 32 FUSION
 SG_ IVI_MLSEATvent_Cmd : 10|3@0+ (1,0) [0|7] "" BodyZone_PS
 SG_ IVI_MRSEATvent_Cmd : 26|3@0+ (1,0) [0|7] "" BodyZone_PS
 SG_ IVI_MLFootLift_Cmd : 1|2@0+ (1,0) [0|3] "" ZONE_ML
 SG_ IVI_MLRecliner_Cmd : 7|2@0+ (1,0) [0|3] "" ZONE_ML
 SG_ IVI_MLSeatLift_Cmd : 5|2@0+ (1,0) [0|3] "" ZONE_ML
 SG_ IVI_MLSlider_Cmd : 3|2@0+ (1,0) [0|3] "" ZONE_ML
 SG_ IVI_MRFootLift_Cmd : 17|2@0+ (1,0) [0|3] "" ZONE_MR
 SG_ IVI_MRRecliner_Cmd : 23|2@0+ (1,0) [0|3] "" ZONE_MR
 SG_ IVI_MRSeatLift_Cmd : 21|2@0+ (1,0) [0|3] "" ZONE_MR
 SG_ IVI_MRSlider_Cmd : 19|2@0+ (1,0) [0|3] "" ZONE_MR
 SG_ IVI_MLFMost_Cmd : 13|1@0+ (1,0) [0|1] "" ZONE_ML
 SG_ IVI_MLNapMode_Cmd : 11|1@0+ (1,0) [0|1] "" ZONE_ML
 SG_ IVI_MLRestore_Cmd : 12|1@0+ (1,0) [0|1] "" ZONE_ML
 SG_ IVI_MLSldRestore_Cmd : 14|1@0+ (1,0) [0|1] "" ZONE_ML
 SG_ IVI_MLZeroGravity_Cmd : 15|1@0+ (1,0) [0|1] "" ZONE_ML
 SG_ IVI_MRFMost_Cmd : 29|1@0+ (1,0) [0|1] "" ZONE_MR
 SG_ IVI_MRNapMode_Cmd : 27|1@0+ (1,0) [0|1] "" ZONE_MR
 SG_ IVI_MRRestore_Cmd : 28|1@0+ (1,0) [0|1] "" ZONE_MR
 SG_ IVI_MRSldRestore_Cmd : 30|1@0+ (1,0) [0|1] "" ZONE_MR
 SG_ IVI_MRZeroGravity_Cmd : 31|1@0+ (1,0) [0|1] "" ZONE_MR
 SG_ IVI_LSEATvent_Cmd : 37|3@0+ (1,0) [0|7] "" BodyZone_PS
 SG_ IVI_RSEATvent_Cmd : 34|3@0+ (1,0) [0|7] "" BodyZone_PS

BO_ 953 ZONE_FR2: 64 ZONE_FR
 SG_ ZFR_SYS_V2LRelayCurr_Sta : 7|8@0+ (10,0) [0|2550] "mA" FUSION
 SG_ ZFR_SYS_TrailerBPlusCurr_Sta : 15|8@0+ (10,0) [0|2550] "mA" FUSION
 SG_ ZFR_SYS_Trailer4Curr_Sta : 23|8@0+ (0.125,0) [0|31.875] "A" FUSION
 SG_ ZFR_SYS_Trailer3Curr_Sta : 31|8@0+ (0.125,0) [0|31.875] "A" FUSION
 SG_ ZFR_SYS_Trailer2Curr_Sta : 39|8@0+ (0.125,0) [0|31.875] "A" FUSION
 SG_ ZFR_SYS_Trailer1Curr_Sta : 47|8@0+ (0.125,0) [0|31.875] "A" FUSION
 SG_ ZFR_SYS_SOTXVCurr_Sta : 55|8@0+ (0.125,0) [0|31.875] "A" FUSION
 SG_ ZFR_SYS_SideMarkerCurr_Sta : 63|8@0+ (0.125,0) [0|31.875] "A" FUSION
 SG_ ZFR_SYS_Ref5VCurr_Sta : 71|8@0+ (10,0) [0|2550] "mA" FUSION
 SG_ ZFR_SYS_RearWasherCurr_Sta : 79|8@0+ (0.125,0) [0|31.875] "A" FUSION
 SG_ ZFR_SYS_RearDefogCurr_Sta : 87|8@0+ (10,0) [0|2550] "mA" FUSION
 SG_ ZFR_SYS_RadFanCurr_Sta : 95|8@0+ (10,0) [0|2550] "mA" FUSION
 SG_ ZFR_SYS_LowBeamCurr_Sta : 103|8@0+ (0.125,0) [0|31.875] "A" FUSION
 SG_ ZFR_SYS_HornCurr_Sta : 111|8@0+ (0.125,0) [0|31.875] "A" FUSION
 SG_ ZFR_SYS_HighBeamCurr_Sta : 119|8@0+ (0.125,0) [0|31.875] "A" FUSION
 SG_ ZFR_SYS_FWiperLCurr_Sta : 127|8@0+ (10,0) [0|2550] "mA" FUSION
 SG_ ZFR_SYS_FWiperHCurr_Sta : 135|8@0+ (10,0) [0|2550] "mA" FUSION
 SG_ ZFR_SYS_FrontWasherCurr_Sta : 143|8@0+ (0.125,0) [0|31.875] "A" FUSION
 SG_ ZFR_SYS_FrontPosLampCurr_Sta : 151|8@0+ (0.125,0) [0|31.875] "A" FUSION
 SG_ ZFR_SYS_FrontFogLampCurr_Sta : 159|8@0+ (0.125,0) [0|31.875] "A" FUSION
 SG_ ZFR_SYS_EPBRelayCurr_Sta : 167|8@0+ (10,0) [0|2550] "mA" FUSION
 SG_ ZFR_SYS_DRLRCurr_Sta : 175|8@0+ (0.125,0) [0|31.875] "A" FUSION
 SG_ ZFR_SYS_DRLLCurr_Sta : 183|8@0+ (0.125,0) [0|31.875] "A" FUSION
 SG_ ZFR_SYS_EDUInverterVolt_Sta : 263|8@0+ (0.2,0) [0|40] "V" FUSION
 SG_ ZFR_SYS_BMSCCUVolt_Sta : 271|8@0+ (0.2,0) [0|40] "V" FUSION
 SG_ FrPowerTemp2 : 503|16@0+ (0.01,-40) [-40|125] "Deg^C" FUSION
 SG_ FrPowerTemp1 : 487|16@0+ (0.01,-40) [-40|125] "Deg^C" FUSION
 SG_ FrCtrlTemp : 471|16@0+ (0.01,-40) [-40|125] "Deg^C" FUSION
 SG_ ZFR_SYS_ChgInletLockCurr_Sta : 255|8@0+ (0.125,0) [0|31.875] "A" FUSION
 SG_ ZFR_SYS_ChgDoorLockCurr_Sta : 247|8@0+ (0.125,0) [0|31.875] "A" FUSION
 SG_ FrPwrStdbyA2PlusCurr : 199|8@0+ (0.125,0) [0|31.875] "A" FUSION
 SG_ FrPwrStdbyA2Curr : 207|8@0+ (0.125,0) [0|31.875] "A" FUSION
 SG_ FrPwrStdbyA1PlusCurr : 191|8@0+ (0.125,0) [0|31.875] "A" FUSION
 SG_ FrPwrONA3Curr : 223|8@0+ (0.125,0) [0|31.875] "A" FUSION
 SG_ FrPwrONA2Curr : 215|8@0+ (0.125,0) [0|31.875] "A" FUSION
 SG_ FrEDU_INVERTERCurr : 239|8@0+ (0.125,0) [0|31.875] "A" FUSION
 SG_ FrBMS_CCU_CIRCurr : 231|8@0+ (0.125,0) [0|31.875] "A" FUSION
 SG_ FrCtrlBDVolt : 447|12@0+ (0.01,0) [0|36] "V" FUSION
 SG_ ZFR_SYS_BoardBatVolt_Sta : 451|12@0+ (0.01,0) [0|40.95] "V" FUSION
 SG_ FrIRC_1Curr : 279|10@0+ (1,0) [0|1023] "mA" FUSION
 SG_ FrIRC_2Curr : 285|10@0+ (1,0) [0|1023] "mA" FUSION
 SG_ ZFR_SYS_U155Temp_Sta : 311|12@0+ (0.1,-40) [-40|369.5] "Deg^C" FUSION
 SG_ ZFR_SYS_U156Temp_Sta : 315|12@0+ (0.1,-40) [-40|369.5] "Deg^C" FUSION
 SG_ ZFR_SYS_U5Temp_Sta : 291|12@0+ (0.1,-40) [-40|369.5] "Deg^C" FUSION

BO_ 949 ZONE_DR2: 64 ZONE_DR
 SG_ ZDR_SYS_VentPwrCurr_Sta : 15|8@0+ (0.125,0) [0|31.875] "A" FUSION
 SG_ ZDR_SYS_TrunkReleaseCurr_Sta : 23|8@0+ (0.125,0) [0|31.875] "A" FUSION
 SG_ ZDR_SYS_RoomLampPwrCurr_Sta : 31|8@0+ (0.125,0) [0|31.875] "A" FUSION
 SG_ ZDR_SYS_ReverseLampCurr_Sta : 39|8@0+ (0.125,0) [0|31.875] "A" FUSION
 SG_ ZDR_SYS_Ref5VCurr_Sta : 47|8@0+ (10,0) [0|2550] "mA" FUSION
 SG_ ZDR_SYS_RearWiperCurr_Sta : 55|8@0+ (0.125,0) [0|31.875] "A" FUSION
 SG_ ZDR_SYS_RearPosLampCurr_Sta : 63|8@0+ (0.125,0) [0|31.875] "A" FUSION
 SG_ ZDR_SYS_RearFogLampCurr_Sta : 71|8@0+ (0.125,0) [0|31.875] "A" FUSION
 SG_ ZDR_SYS_OTDoorUnlockCurr_Sta : 79|8@0+ (0.125,0) [0|31.875] "A" FUSION
 SG_ ZDR_SYS_OMirrorDefogCurr_Sta : 87|8@0+ (0.125,0) [0|31.875] "A" FUSION
 SG_ ZDR_SYS_ModeDriveCurr_Sta : 95|8@0+ (0.125,0) [0|31.875] "A" FUSION
 SG_ ZDR_SYS_MirrorFoldCurr_Sta : 103|8@0+ (0.125,0) [0|31.875] "A" FUSION
 SG_ ZDR_SYS_LINStepPwrCurr_Sta : 111|8@0+ (0.125,0) [0|31.875] "A" FUSION
 SG_ ZDR_SYS_IntakeDriveCurr_Sta : 119|8@0+ (0.125,0) [0|31.875] "A" FUSION
 SG_ ZDR_SYS_HSWTempPwrCurr_Sta : 127|8@0+ (10,0) [0|2550] "mA" FUSION
 SG_ ZDR_SYS_HSWHeaterPwrCurr_Sta : 135|8@0+ (0.125,0) [0|31.875] "A" FUSION
 SG_ ZDR_SYS_HSWHeaterIndCurr_Sta : 143|8@0+ (10,0) [0|2550] "mA" FUSION
 SG_ ZDR_SYS_HazardLEDCurr_Sta : 151|8@0+ (0.125,0) [0|31.875] "A" FUSION
 SG_ ZDR_SYS_FragrancePwrCurr_Sta : 159|8@0+ (0.125,0) [0|31.875] "A" FUSION
 SG_ ZDR_SYS_DRDoorUnlockCurr_Sta : 167|8@0+ (0.125,0) [0|31.875] "A" FUSION
 SG_ ZDR_SYS_DMSPwrCurr_Sta : 175|8@0+ (0.125,0) [0|31.875] "A" FUSION
 SG_ ZDR_SYS_ColumnSWCurr_Sta : 183|8@0+ (0.125,0) [0|31.875] "A" FUSION
 SG_ ZDR_SYS_CHMSLCurr_Sta : 191|8@0+ (0.125,0) [0|31.875] "A" FUSION
 SG_ ZDR_SYS_BrakeLampLRCurr_Sta : 199|8@0+ (0.125,0) [0|31.875] "A" FUSION
 SG_ ZDR_SYS_AtmosLampCurr_Sta : 207|8@0+ (0.125,0) [0|31.875] "A" FUSION
 SG_ ZDR_SYS_AntiGlareCurr_Sta : 215|8@0+ (0.125,0) [0|31.875] "A" FUSION
 SG_ ZDR_SYS_AllDoorLockCurr_Sta : 223|8@0+ (0.125,0) [0|31.875] "A" FUSION
 SG_ ZDR_SYS_CTDINDCurr_Sta : 327|10@0+ (1,0) [0|1023] "mA" FUSION
 SG_ ZDR_SYS_BSDLCurr_Sta : 7|4@0+ (10,0) [0|150] "mA" FUSION
 SG_ ZDR_SYS_BSDRCurr_Sta : 3|4@0+ (10,0) [0|150] "mA" FUSION
 SG_ DrPowerTemp2 : 503|16@0+ (0.01,-40) [-40|125] "Deg^C" FUSION
 SG_ DrPowerTemp1 : 487|16@0+ (0.01,-40) [-40|125] "Deg^C" FUSION
 SG_ DrCtrlTemp : 471|16@0+ (0.01,-40) [-40|125] "Deg^C" FUSION
 SG_ ZDR_SYS_DrPwrStdbyA2Curr_Sta : 295|8@0+ (0.125,0) [0|31.875] "A" FUSION
 SG_ ZDR_SYS_AuBoxPwrN4Curr_Sta : 255|8@0+ (0.125,0) [0|31.875] "A" FUSION
 SG_ ZDR_SYS_AuBoxPwrN3Curr_Sta : 247|8@0+ (0.125,0) [0|31.875] "A" FUSION
 SG_ DrPwrStdbyACurr : 263|8@0+ (0.125,0) [0|31.875] "A" FUSION
 SG_ DrPwrONA2Curr : 287|8@0+ (0.125,0) [0|31.875] "A" FUSION
 SG_ DrPwrONA1Curr : 279|8@0+ (0.125,0) [0|31.875] "A" FUSION
 SG_ DrAuBoxPwrN2Curr : 239|8@0+ (0.125,0) [0|31.875] "A" FUSION
 SG_ DrAuBoxPwrN1Curr : 231|8@0+ (0.125,0) [0|31.875] "A" FUSION
 SG_ DrADASCurr : 271|8@0+ (0.125,0) [0|31.875] "A" FUSION
 SG_ DrCtrlBDVolt : 307|12@0+ (0.01,0) [0|36] "V" FUSION
 SG_ ZDR_SYS_BoardBatVolt_Sta : 303|12@0+ (0.01,0) [0|40.95] "V" FUSION
 SG_ ZDR_SYS_U155Temp_Sta : 447|12@0+ (0.1,-40) [-40|369.5] "Deg^C" FUSION
 SG_ ZDR_SYS_U156Temp_Sta : 451|12@0+ (0.1,-40) [-40|369.5] "Deg^C" FUSION
 SG_ ZDR_SYS_U5Temp_Sta : 427|12@0+ (0.1,-40) [-40|369.5] "Deg^C" FUSION

BO_ 2015 DiagFuncReqOBD: 8 FUSION
 SG_ DiagFuncReqOBD : 7|64@0+ (1,0) [0|0] "" ZONE_FR,ZONE_DR

BO_ 1703 DiagPhysReqToPSD_L: 64 FUSION
 SG_ DiagPhysReqToPSD_L : 7|64@0+ (1,0) [0|0] "" ZONE_DR

BO_ 1704 DiagPhysReqToPSD_R: 64 FUSION
 SG_ DiagPhysReqToPSD_R : 7|64@0+ (1,0) [0|0] "" ZONE_DR

BO_ 1575 DiagRespFromPSD_L: 64 ZONE_DR
 SG_ DiagRespFromPSD_L : 7|64@0+ (1,0) [0|0] "" FUSION

BO_ 1576 DiagRespFromPSD_R: 64 ZONE_DR
 SG_ DiagRespFromPSD_R : 7|64@0+ (1,0) [0|0] "" FUSION

CM_ BO_ 804 "Routing from LIN_DR4";
CM_ SG_ 778 EAC_Temp "Compressor Controller Temperature";
CM_ SG_ 778 EAC_DrvVoltFalt "15V Drive Voltage Failure";
CM_ SG_ 778 EAC_MotorLackFalt "Compressor Phase Loss Fault";
CM_ SG_ 778 EAC_OvLoadFalt "Compressor Overload Fault";
CM_ SG_ 778 EAC_TempSnsrFalt "Controller Temperature Sensor Failure";
CM_ SG_ 778 COMP_ComLost "Lost Communication on Compressor";
CM_ SG_ 778 COMP_IPM_HWFLt "Fault Detection on Compressor of IPM Hardware";
CM_ SG_ 778 COMP_IPM_TempOverFlt "Fault Detection on Compressor of IPM Temperature Too High";
CM_ SG_ 778 COMP_CurOverProtect "Fault Detection on Compressor OverCurrent Protection";
CM_ SG_ 778 COMP_VoltOverErr "OverVoltage Fault Detection on  High-Voltage DC bus";
CM_ SG_ 778 COMP_VoltLessErr "LessVoltage Fault Detection on  High-Voltage DC bus";
CM_ SG_ 778 COMP_CtrlCircFlt "Compressor Controller Fault Detection status";
CM_ SG_ 778 COMP_Sta "Current State of Compressor";
CM_ SG_ 778 COMP_Init "Compressor Initialization Status";
CM_ SG_ 778 COMP_SpdVaild "Validity of Reported Speed of Compressor";
CM_ SG_ 778 EAC_MotCrt "Phase Current Value";
CM_ SG_ 778 COMP_CurVaild "Validity of Compressor Reporting HVDC Bus Current";
CM_ SG_ 778 COMP_VoltVaild "Validity of Compressor Reporting HVDC Bus Voltage";
CM_ SG_ 778 COMP_StatorSpd "Compressor Report Speed";
CM_ SG_ 778 COMP_ConCur "Compressor Reports HVDC Bus Current";
CM_ SG_ 778 COMP_ConVolt "Compressor Reports HVDC Bus Voltage";
CM_ SG_ 778 COMP_ActualPwr "COMP actual power";
CM_ SG_ 778 PTC1_PowerConsumption "WPTC_PowerConsumption";
CM_ SG_ 778 PTC1_IGBTTem "WPTC_IGBT temperature";
CM_ SG_ 778 PTC1_ClntTempOtlt "WPTC_coolant out temperature";
CM_ SG_ 778 PTC1_ClntTempInlt "WPTC_coolant in temperature";
CM_ SG_ 778 PTC1_ActuHiCrnt "WPTC_actual HV current";
CM_ SG_ 778 PTC1_WrkngSts "WPTC_working status";
CM_ SG_ 778 PTC1_ClntInltOverTemProtn "WPTC_coolant in over temperature protect";
CM_ SG_ 778 PTC1_ClntInltTemSnsrFlt "WPTC_coolant in temperature sensor fault";
CM_ SG_ 778 PTC1_ClntOtltOverTemProtn "WPTC_coolant out over temperature protect";
CM_ SG_ 778 PTC1_ClntOtltTemSnsrFlt "WPTC_coolant out temperature sensor fault";
CM_ SG_ 778 PTC1_CommError "WPTC_communication error";
CM_ SG_ 778 PTC1_CoreOrIGBTOpenErr "WPTC_core or IGBTopen error";
CM_ SG_ 778 PTC1_HiCrntSnsrFlt "WPTC_current sensor fault";
CM_ SG_ 778 PTC1_HVDisconnectProtn "WPTC_HV voltage disconnect protect";
CM_ SG_ 778 PTC1_HVOverCrntProtn "WPTC_HV over current protect";
CM_ SG_ 778 PTC1_IGBTOverTemProtn "WPTC_IGBTover temperature protect";
CM_ SG_ 778 PTC1_IGBTShrtErr "WPTC_IGBT short error";
CM_ SG_ 778 PTC1_IGBTTemSnsrFlt "WPTC_IGBT temperature sensor fault";
CM_ SG_ 778 PTC1_MmryFlt "WPTC_memory fault";
CM_ SG_ 778 PTC1_PCBOverTempProtn "WPTC_PCB over temperature protect";
CM_ SG_ 778 PTC1_PCBTempSnsrFlt "WPTC_PCB temperature sensor fault";
CM_ SG_ 778 PTC1_VbatVtgProtn "WPTC_HV voltage incorrect protect";
CM_ SG_ 778 PTC1_VbatVtgSnsrFlt "WPTC_HV voltage sensor fault";
CM_ SG_ 778 PTC1_VbatVtgUnstable "WPTC_HV voltage unstable";
CM_ SG_ 965 ZONE_DR_SW_Var1 "software version car model variation 1";
CM_ SG_ 965 ZONE_DR_SW_Country2 "software version country of target market character 2";
CM_ SG_ 965 ZONE_DR_SW_Country1 "software version country of target market character 1";
CM_ SG_ 965 ZONE_DR_SW_Patch2 "software version patch character 2";
CM_ SG_ 965 ZONE_DR_SW_Patch1 "software version patch character 1";
CM_ SG_ 965 ZONE_DR_SW_Minor2 "software version minor character 2";
CM_ SG_ 965 ZONE_DR_SW_Minor1 "software version minor character 1";
CM_ SG_ 965 ZONE_DR_SW_Major2 "software version major character 2";
CM_ SG_ 965 ZONE_DR_SW_Major1 "software version major character 1";
CM_ SG_ 965 ZONE_DR_SW_Controller2 "software version controller character 2";
CM_ SG_ 965 ZONE_DR_SW_Controller1 "software version controller character 1";
CM_ SG_ 965 ZONE_DR_SW_CarModel3 "software version car model character 3";
CM_ SG_ 965 ZONE_DR_SW_CarModel2 "software version car model character 2";
CM_ SG_ 965 ZONE_DR_SW_CarModel1 "software version car model character 1";
CM_ SG_ 965 ZONE_DR_HW_Ver3 "ZONE_DR hardware version character 3";
CM_ SG_ 965 ZONE_DR_HW_Ver2 "ZONE_DR hardware version character 2";
CM_ SG_ 965 ZONE_DR_HW_Ver1 "ZONE_DR hardware version character 1";
CM_ SG_ 965 ZONE_DR_SW_dash1 "software version dash character 1";
CM_ SG_ 965 ZONE_DR_SW_change1 "software version number of change 1";
CM_ SG_ 965 ZONE_DR_SW_change2 "software version number of change 2";
CM_ SG_ 965 ZONE_DR_SW_dash2 "software version dash character 2";
CM_ SG_ 965 ZONE_DR_SW_SHA1 "software version SHA character 1";
CM_ SG_ 965 ZONE_DR_SW_SHA2 "software version SHA character 2";
CM_ SG_ 965 ZONE_DR_SW_SHA3 "software version SHA character 3";
CM_ SG_ 965 ZONE_DR_SW_SHA4 "software version SHA character 4";
CM_ SG_ 965 ZONE_DR_SW_SHA5 "software version SHA character 5";
CM_ SG_ 965 ZONE_DR_SW_SHA6 "software version SHA character 6";
CM_ SG_ 965 ZONE_DR_SW_SHA7 "software version SHA character 7";
CM_ SG_ 965 ZONE_DR_SW_SHA8 "software version SHA character 8";
CM_ SG_ 965 ZONE_DR_SW_Var5 "software version car model variation 5";
CM_ SG_ 965 ZONE_DR_SW_Var4 "software version car model variation 4";
CM_ SG_ 965 ZONE_DR_SW_Var3 "software version car model variation 3";
CM_ SG_ 965 ZONE_DR_SW_Var2 "software version car model variation 2";
CM_ SG_ 965 ZONE_DR_SW_ECUGen2 "ECU generation 2";
CM_ SG_ 965 ZONE_DR_SW_ECUGen1 "ECU generation 1";
CM_ SG_ 969 ZONE_FR_SW_Var1 "software version car model variation 1";
CM_ SG_ 969 ZONE_FR_SW_Country2 "software version country of target market character 2";
CM_ SG_ 969 ZONE_FR_SW_Country1 "software version country of target market character 1";
CM_ SG_ 969 ZONE_FR_SW_Patch2 "software version patch character 2";
CM_ SG_ 969 ZONE_FR_SW_Patch1 "software version patch character 1";
CM_ SG_ 969 ZONE_FR_SW_Minor2 "software version minor character 2";
CM_ SG_ 969 ZONE_FR_SW_Minor1 "software version minor character 1";
CM_ SG_ 969 ZONE_FR_SW_Major2 "software version major character 2";
CM_ SG_ 969 ZONE_FR_SW_Major1 "software version major character 1";
CM_ SG_ 969 ZONE_FR_SW_Controller2 "software version controller character 2";
CM_ SG_ 969 ZONE_FR_SW_Controller1 "software version controller character 1";
CM_ SG_ 969 ZONE_FR_SW_CarModel3 "software version car model character 3";
CM_ SG_ 969 ZONE_FR_SW_CarModel2 "software version car model character 2";
CM_ SG_ 969 ZONE_FR_SW_CarModel1 "software version car model character 1";
CM_ SG_ 969 ZONE_FR_HW_Ver3 "ZONE_FR hardware version character 3";
CM_ SG_ 969 ZONE_FR_HW_Ver2 "ZONE_FR hardware version character 2";
CM_ SG_ 969 ZONE_FR_HW_Ver1 "ZONE_FR hardware version character 1";
CM_ SG_ 969 ZONE_FR_SW_dash1 "software version dash character 1";
CM_ SG_ 969 ZONE_FR_SW_change1 "software version number of change 1";
CM_ SG_ 969 ZONE_FR_SW_change2 "software version number of change 2";
CM_ SG_ 969 ZONE_FR_SW_dash2 "software version dash character 2";
CM_ SG_ 969 ZONE_FR_SW_SHA1 "software version SHA character 1";
CM_ SG_ 969 ZONE_FR_SW_SHA2 "software version SHA character 2";
CM_ SG_ 969 ZONE_FR_SW_SHA3 "software version SHA character 3";
CM_ SG_ 969 ZONE_FR_SW_SHA4 "software version SHA character 4";
CM_ SG_ 969 ZONE_FR_SW_SHA5 "software version SHA character 5";
CM_ SG_ 969 ZONE_FR_SW_SHA6 "software version SHA character 6";
CM_ SG_ 969 ZONE_FR_SW_SHA7 "software version SHA character 7";
CM_ SG_ 969 ZONE_FR_SW_SHA8 "software version SHA character 8";
CM_ SG_ 969 ZONE_FR_SW_ECUGen2 "ECU generation 2";
CM_ SG_ 969 ZONE_FR_SW_ECUGen1 "ECU generation 1";
CM_ SG_ 969 ZONE_FR_SW_Var5 "software version car model variation 5";
CM_ SG_ 969 ZONE_FR_SW_Var4 "software version car model variation 4";
CM_ SG_ 969 ZONE_FR_SW_Var3 "software version car model variation 3";
CM_ SG_ 969 ZONE_FR_SW_Var2 "software version car model variation 2";
CM_ SG_ 1284 NM_ZONE_FR_Node_ID "Source Node Identifier";
CM_ SG_ 1284 NM_ZONE_FR_PNI "Partial Network Information Bit (PNI)";
CM_ SG_ 1284 NM_ZONE_FR_Active_WU "Active Wakeup Bit";
CM_ SG_ 1284 NM_ZONE_FR_CSB "NM Coordinator Sleep Bit";
CM_ SG_ 1284 NM_ZONE_FR_Rpt_Msg_Req "Repeat Message Request";
CM_ SG_ 1284 NM_ZONE_FR_ERROR_State "Defined Error states of the CAN Controller";
CM_ SG_ 1285 NM_DKC_Node_ID "Source Node Identifier";
CM_ SG_ 1285 NM_DKC_PNI "Partial Network Information Bit (PNI)";
CM_ SG_ 1285 NM_DKC_Active_WU "Active Wakeup Bit";
CM_ SG_ 1285 NM_DKC_CSB "NM Coordinator Sleep Bit";
CM_ SG_ 1285 NM_DKC_Rpt_Msg_Req "Repeat Message Request";
CM_ SG_ 1285 NM_DKC_ERROR_State "Defined Error states of the CAN Controller";
CM_ SG_ 1344 NM_ZONE_DR_Node_ID "Source Node Identifier";
CM_ SG_ 1344 NM_ZONE_DR_PNI "Partial Network Information Bit (PNI)";
CM_ SG_ 1344 NM_ZONE_DR_Active_WU "Active Wakeup Bit";
CM_ SG_ 1344 NM_ZONE_DR_CSB "NM Coordinator Sleep Bit";
CM_ SG_ 1344 NM_ZONE_DR_Rpt_Msg_Req "Repeat Message Request";
CM_ SG_ 1344 NM_ZONE_DR_ERROR_State "Defined Error states of the CAN Controller";
CM_ SG_ 1540 DiagRespFromZONE_FR "Diagnostic Response from ZONE_FR";
CM_ SG_ 1541 DiagRespFromDKC "Diagnostic Response from DKC";
CM_ SG_ 1573 DiagRespFromAirPTC "Diagnostic Response from AirPTC";
CM_ SG_ 1589 DiagRespFromWPTC "Diagnostic Response from WPTC
";
CM_ SG_ 1600 DiagRespFromZONE_DR "Diagnostic Response from ZONE_DR";
CM_ SG_ 1605 DiagRespFromCompress "Diagnostic Response from Compress";
CM_ SG_ 794 BD_APM_WinFOpened_Sta "BodyZone_DR APM Driver window opening";
CM_ SG_ 794 BD_APM_WinROpened_Sta "BodyZone_DR APM rear window opening";
CM_ SG_ 794 BD_Door_FHandleClose_Sta "Bodyzone_DR Driver side Front Door Handle Close Status";
CM_ SG_ 794 BD_Door_FHandleHalf_Sta "Bodyzone_DR Driver side Front Door Handle Half Open Status";
CM_ SG_ 794 BD_Door_RHandleClose_Sta "Bodyzone_DR Driver side Rear Door Handle Close Status";
CM_ SG_ 794 BD_Door_RHandleHalf_Sta "Bodyzone_DR Driver side Rear Door Handle Half Open Status";
CM_ SG_ 858 BD_DSEAT_SlidPos_Sta "BodyZone_DR SEAT Driver Seat Slider Position
Min=0, Max=523, Unit=pulse, Offset=0, Resolution=1 pulse per bit, Invaild=1023, Undefined=524-1022";
CM_ SG_ 858 BD_DSEAT_RecPos_Sta "BodyZone_DR SEAT Driver Seat Recliner Position
Min=0, Max=1118, Unit=pulse, Offset=0, Resolution=1 pulse per bit, Invaild=2047, Undefined=1119 -2046";
CM_ SG_ 858 BD_DSEAT_FLPos_Sta "BodyZone_DR SEAT Driver Seat Front Lifter Position
Min=0, Max=295, Unit=pulse, Offset=0, Resolution=1 pulse per bit, Invaild=511, Undefined=296-510";
CM_ SG_ 858 BD_DSEAT_RLPos_Sta "BodyZone_DR SEAT Driver Seat Rear Lifter Position
Min=0,Max=391, Unit=pulse, Offset=0, Resolution=1 pulse per bit, Invaild=511, Undefined=392-510
";
CM_ SG_ 858 BD_DSEAT_Mode_Sta "BodyZone_DR SEAT Driver Seat Mode";
CM_ SG_ 858 BD_DSEAT_AntiAct_Sta "BodyZone_DR SEAT Driver Seat Antitheft Activate Status";
CM_ SG_ 858 BD_DSEAT_Anti_Sta "BodyZone_DR SEAT Driver Seat Antitheft Status";
CM_ SG_ 858 BD_DSEAT_EntryAct_Sta "BodyZone_DR SEAT Driver Seat Entry Function Activate Status";
CM_ SG_ 858 BD_DSEAT_EntryFun_Sta "BodyZone_DR SEAT Driver Seat Entry Function Status";
CM_ SG_ 858 BD_DSEAT_Error_Sta "BodyZone_DR SEAT Driver Seat Error Status";
CM_ SG_ 858 BD_DSEAT_Vent_Sta "BodyZone_DR SEAT Driver Seat Ventilate Staus";
CM_ SG_ 858 BD_DSEAT_heater_Sta "BodyZone_DR SEAT Driver seat heater status";
CM_ SG_ 858 BD_DSEAT_MemSet_Sta "BodyZone_DR Driver Seat Memory seat Status";
CM_ SG_ 858 BD_DSEAT_StopKeepMove_Sta "BD_DSEAT_StopKeepMove_Sta";
CM_ SG_ 1287 NM_BodyZone_DR_Node_ID "Source Node Identifier";
CM_ SG_ 1287 NM_BodyZone_DR_Rpt_Msg_Req "Repeat Message Request";
CM_ SG_ 1287 NM_BodyZone_DR_CSB "NM Coordinator Sleep Bit";
CM_ SG_ 1287 NM_BodyZone_DR_Active_WU "Active Wakeup Bit";
CM_ SG_ 1287 NM_BodyZone_DR_PNI "Partial Network Information Bit (PNI)";
CM_ SG_ 1287 NM_BodyZone_DR_ERROR_State "Defined Error states of the CAN Controller";
CM_ SG_ 1543 DiagRespFromBodyZone_DR "Diagnostic Response from BodyZone_DR";
CM_ SG_ 859 BP_PTG_PowerLatch_Sta "BodyZone_PS PTG Power Latch Status";
CM_ SG_ 859 BP_PTG_DebugMode_Sta "BodyZone_PS PTG Activating debug mode by shortening signal cycle time";
CM_ SG_ 859 BP_PTG_LatchSeg_Sta "BodyZone_PS PTG Latch Segment";
CM_ SG_ 859 BP_PTG_InsideSW2_Sta "BodyZone_PS PTG Inside SW#2 State";
CM_ SG_ 859 BP_PTG_InsideSW1_Sta "BodyZone_PS PTG Inside SW#1 State";
CM_ SG_ 859 BP_PTG_HalfSW_Sta "BodyZone_PS PTG Half Latch Switch Status";
CM_ SG_ 859 BP_PTG_LeftDuty_Sta "BodyZone_PS PTG Left Strut Motor Duty";
CM_ SG_ 859 BP_PTG_FullSW_Sta "BodyZone_PS PTG Full Latch Switch Status";
CM_ SG_ 859 BP_PTG_RightDuty_Sta "BodyZone_PS PTG Right Strut Motor Duty";
CM_ SG_ 859 BP_PTG_NtlSW_Sta "BodyZone_PS PTG Neutral Switch Status";
CM_ SG_ 859 BP_PTG_CinchDuty_Sta "BodyZone_PS PTG Latch Motor Cinch Duty";
CM_ SG_ 859 BP_PTG_StrutThermal_Sta "BodyZone_PS PTG Strut Motor Thermal Protection";
CM_ SG_ 859 BP_PTG_LeftCur_Sta "BodyZone_PS PTG Left Strut Current";
CM_ SG_ 859 BP_PTG_StrutAntiPinch_Sta "BodyZone_PS PTG Strut Motor Anti-Pinch";
CM_ SG_ 859 BP_PTG_RightCur_Sta "BodyZone_PS PTG Right Strut Current";
CM_ SG_ 859 BP_PTG_StrutStall_Sta "BodyZone_PS PTG Strut Motor Stall";
CM_ SG_ 859 BP_PTG_CinchCur_Sta "BodyZone_PS PTG Latch Cinch Current";
CM_ SG_ 859 BP_PTG_AbuseProtection_Sta "BodyZone_PS PTG System Abuse Protection";
CM_ SG_ 859 BP_PTG_ReleaseCur_Sta "BodyZone_PS PTG Latch Release Current";
CM_ SG_ 859 BP_PTG_LatchThermal_Sta "BodyZone_PS PTG Power Latch Motor Thermal Protection";
CM_ SG_ 859 BP_PTG_LeftHallPosn_Sta "BodyZone_PS PTG Left Strut Hall Position";
CM_ SG_ 859 BP_PTG_ErrLeftStrut_Sta "BodyZone_PS PTG Left Strut Motor Error";
CM_ SG_ 859 BP_PTG_ErrVoltage_Sta "BodyZone_PS PTG B+ Voltage Error";
CM_ SG_ 859 BP_PTG_ErrRightStrut_Sta "BodyZone_PS PTG Right Strut Motor Error";
CM_ SG_ 859 BP_PTG_RightHallPosn_Sta "BodyZone_PS PTG Right Strut Hall Position";
CM_ SG_ 859 BP_PTG_ErrHall_Sta "BodyZone_PS PTG Strut Hall Sensor Error";
CM_ SG_ 859 BP_PTG_ErrLatch_Sta "BodyZone_PS PTG Power Latch Motor Error";
CM_ SG_ 859 BP_PTG_OpenRatio_Sta "BodyZone_PS PTG Open Ratio";
CM_ SG_ 859 BP_PTG_Active_Sta "BodyZone_PS PTG Function Activation State";
CM_ SG_ 859 BP_PTG_Sys_Sta "BodyZone_PS PTG System Status";
CM_ SG_ 859 BP_PTG_RDIL_Cmd "BodyZone_PS PTG Rear Direction Indicator Lamp State";
CM_ SG_ 859 BP_PTG_IsSetHeight_Sta "BodyZone_PS PTG 'Set Open Height' Action Listener";
CM_ SG_ 859 BP_PTG_Exist_Sta "BodyZone_PS PTG Existence";
CM_ SG_ 859 BP_PSEAT_Vent_Sta "BodyZone_PS SEAT Passenger Seat Ventilate Staus";
CM_ SG_ 859 BP_PSEAT_Mode_Sta "BodyZone_PS SEAT Passenger Seat Mode";
CM_ SG_ 859 BP_PSEAT_Error_Sta "BodyZone_PS SEAT Passenger Seat Error Status";
CM_ SG_ 859 BP_PSEAT_heater_Sta "BodyZone_PS SEAT Passenger seat heater status";
CM_ SG_ 1007 BP_APM_WinFCurrent_Sta "BodyZone_PS APM front window operating current";
CM_ SG_ 1007 BP_APM_WinRCurrent_Sta "BodyZone_PS APM rear window operating current";
CM_ SG_ 1007 BP_SYS_PowerTemp2_Sta "BodyZone_PS Detect temperature on power board";
CM_ SG_ 1007 BP_SYS_PowerTemp1_Sta "BodyZone_PS Detect temperature on power board";
CM_ SG_ 1007 BP_SYS_CtrlTemp_Sta "BodyZone_PS Detect temperature on Ctrl board";
CM_ SG_ 1007 BP_SYS_CtrlBDVolt_Sta "BodyZone_PS Detect voltage on Ctrl board";
CM_ SG_ 1007 BP_SEAT_HeatCurrent_Sta "BodyZone_PS Right Seat Heat operating current";
CM_ SG_ 1007 BP_SEAT_VentCurrent_Sta "BodyZone_PS Right Seat Vent operating current";
CM_ SG_ 1007 BP_Door_RCurrent_Sta "Bodyzone_PS Passenger side Rear Door Handle operating current";
CM_ SG_ 1007 BP_Door_FCurrent_Sta "Bodyzone_PS Passenger side Front Door Handle operating current";
CM_ SG_ 1007 BP_SEAT_ReclineCurrent_Sta "BodyZone_PS Right Seat Recline operating current";
CM_ SG_ 1007 BP_SEAT_SlideCurrent_Sta "BodyZone_PS Right Seat Slide operating current";
CM_ SG_ 1007 BP_PSEAT_HeaterTemp_Sta "The signal is set to feedback on the heater¡¦s temperature on the D31H passenger seat to Bodyzone_Ps. Therefore, once the temperature exceeds the designed value, then it can be detected.";
CM_ SG_ 1007 BP_PTG_ACTRLatchCur_Sta "BodyZone_PS PTG ACTR Latch Operating Current";
CM_ SG_ 971 BP_SW_ECUGen2 "BodyZone_PS ECU generation 2";
CM_ SG_ 971 BP_SW_ECUGen1 "BodyZone_PS ECU generation 1";
CM_ SG_ 971 BP_SW_Var5 "BodyZone_PS software version car model variation 5";
CM_ SG_ 971 BP_SW_Var4 "BodyZone_PS software version car model variation 4";
CM_ SG_ 971 BP_SW_Var3 "BodyZone_PS software version car model variation 3";
CM_ SG_ 971 BP_SW_Var2 "BodyZone_PS software version car model variation 2";
CM_ SG_ 795 BP_APM_WinFOpened_Sta "BodyZone_PS APM front window opening";
CM_ SG_ 795 BP_APM_WinROpened_Sta "BodyZone_PS APM rear window opening";
CM_ SG_ 795 BP_Door_FHandleClose_Sta "Bodyzone_PS Passenger side Front Door Handle Close Status";
CM_ SG_ 795 BP_Door_FHandleHalf_Sta "Bodyzone_PS Passenger side Front Door Handle Half Open Status";
CM_ SG_ 795 BP_SYS_LampPwrSTS_Sta "BodyZone_PS Lamp Power";
CM_ SG_ 795 BP_Door_RHandleClose_Sta "Bodyzone_PS Passenger side Rear Door Handle Close Status";
CM_ SG_ 795 BP_Door_RHandleHalf_Sta "Bodyzone_PS Passenger side Rear Door Handle Half Open Status";
CM_ SG_ 795 BP_SEAT_MLVent_Sta "BodyZone_PS SEAT ML Fan Status to IVI";
CM_ SG_ 795 BP_SEAT_MRVent_Sta "BodyZone_PS SEAT MR Fan Status to IVI";
CM_ SG_ 795 BP_SEAT_LVent_Sta "BodyZone_PS SEAT L Fan Status to IVI";
CM_ SG_ 795 BP_SEAT_RVent_Sta "BodyZone_PS SEAT R Fan Status to IVI";
CM_ SG_ 1286 NM_BodyZone_PS_Node_ID "Source Node Identifier";
CM_ SG_ 1286 NM_BodyZone_PS_Rpt_Msg_Req "Repeat Message Request";
CM_ SG_ 1286 NM_BodyZone_PS_CSB "NM Coordinator Sleep Bit";
CM_ SG_ 1286 NM_BodyZone_PS_Active_WU "Active Wakeup Bit";
CM_ SG_ 1286 NM_BodyZone_PS_PNI "Partial Network Information Bit (PNI)";
CM_ SG_ 1286 NM_BodyZone_PS_ERROR_State "Defined Error states of the CAN Controller";
CM_ SG_ 1542 DiagRespFromBodyZone_PS "Diagnostic Response from BodyZone_PS";
CM_ SG_ 1671 DiagPhysReqToBodyZone_DR "Diagnostic Physical Request to BodyZone_DR";
CM_ SG_ 1670 DiagPhysReqToBodyZone_PS "Diagnostic Physical Request to BodyZone_PS";
CM_ SG_ 376 FCM2_Checksum "Checksum of FCM2(AUTOSAR E2E profile 1)

Polynomial 0x1D (x^8+x^4+x^3+x^2+1) Both start value and XOR value are 0x00.";
CM_ SG_ 376 FCM2_LifeCount "FCM2 4-bit rolling counter
It starts counting from 0, ends at 14 and returns to zero (0~14).";
CM_ SG_ 376 ADB_ILLAmbtSta "ADB_IlluminationAmbientStatus";
CM_ SG_ 376 ADB_VehNumVal "ADB_VehicleNumberValue";
CM_ SG_ 376 ADB_FR_CMR_Sta "ADB_FR_CMR_Status";
CM_ SG_ 376 ADB_VehLtAngl1Val "ADB_VehicleLeftAngle1Value
0x0~0x1F4¡G-25.0~+25.0";
CM_ SG_ 376 ADB_VehRtAngl1Val "ADB_VehicleRightAngle1Value
0x0~0x1F4¡G-25.0~+25.0";
CM_ SG_ 376 ADB_VehLtAngl2Val "ADB_VehicleLeftAngle2Value
0x0~0x1F4¡G-25.0~+25.0";
CM_ SG_ 376 ADB_VehRtAngl2Val "ADB_VehicleRightAngle2Value
0x0~0x1F4¡G-25.0~+25.0";
CM_ SG_ 376 ADB_VehLtAngl3Val "ADB_VehicleLeftAngle3Value
0x0~0x1F4¡G-25.0~+25.0";
CM_ SG_ 376 ADB_VehRtAngl3Val "ADB_VehicleRightAngle3Value
0x0~0x1F4¡G-25.0~+25.0";
CM_ SG_ 376 ADB_VehLtAngl4Val "ADB_VehicleLeftAngle4Value
0x0~0x1F4¡G-25.0~+25.0";
CM_ SG_ 376 ADB_VehRtAngl4Val "ADB_VehicleRightAngle4Value
0x0~0x1F4¡G-25.0~+25.0";
CM_ SG_ 376 ADB_VehLtAngl5Val "ADB_VehicleLeftAngle5Value
0x0~0x1F4¡G-25.0~+25.0";
CM_ SG_ 376 ADB_VehRtAngl5Val "ADB_VehicleRightAngle5Value
0x0~0x1F4¡G-25.0~+25.0";
CM_ SG_ 376 ADB_VehLtAngl6Val "ADB_VehicleLeftAngle6Value
0x0~0x1F4¡G-25.0~+25.0";
CM_ SG_ 376 ADB_VehRtAngl6Val "ADB_VehicleRightAngle6Value
0x0~0x1F4¡G-25.0~+25.0";
CM_ SG_ 376 ADB_VehLtAngl7Val "ADB_VehicleLeftAngle7Value
0x0~0x1F4¡G-25.0~+25.0";
CM_ SG_ 376 ADB_VehRtAngl7Val "ADB_VehicleRightAngle7Value
0x0~0x1F4¡G-25.0~+25.0";
CM_ SG_ 376 ADB_VehLtAngl8Val "ADB_VehicleLeftAngle8Value
0x0~0x1F4¡G-25.0~+25.0";
CM_ SG_ 376 ADB_VehRtAngl8Val "ADB_VehicleRightAngle8Value
0x0~0x1F4¡G-25.0~+25.0";
CM_ SG_ 376 ADB_VehLtAngl9Val "ADB_VehicleLeftAngle9Value
0x0~0x1F4¡G-25.0~+25.0";
CM_ SG_ 376 ADB_VehRtAngl9Val "ADB_VehicleRightAngle9Value
0x0~0x1F4¡G-25.0~+25.0";
CM_ SG_ 376 ADB_VehLtAngl10Val "ADB_VehicleLeftAngle10Value
0x0~0x1F4¡G-25.0~+25.0";
CM_ SG_ 376 ADB_VehRtAngl10Val "ADB_VehicleRightAngle10Value
0x0~0x1F4¡G-25.0~+25.0";
CM_ SG_ 376 ADB_VehDst1Val "ADB_VehicleDistance1Value";
CM_ SG_ 376 ADB_VehDst3Val "ADB_VehicleDistance3Value";
CM_ SG_ 376 ADB_VehDst2Val "ADB_VehicleDistance2Value";
CM_ SG_ 376 ADB_VehDst5Val "ADB_VehicleDistance5Value";
CM_ SG_ 376 ADB_VehDst4Val "ADB_VehicleDistance4Value";
CM_ SG_ 376 ADB_VehDst7Val "ADB_VehicleDistance7Value";
CM_ SG_ 376 ADB_VehDst6Val "ADB_VehicleDistance6Value";
CM_ SG_ 376 ADB_VehDst9Val "ADB_VehicleDistance9Value";
CM_ SG_ 376 ADB_VehDst8Val "ADB_VehicleDistance8Value";
CM_ SG_ 376 ADB_VehDst10Val "ADB_VehicleDistance10Value";
CM_ SG_ 970 BD_SW_ECUGen2 "BodyZone_DR ECU generation 2";
CM_ SG_ 970 BD_SW_ECUGen1 "BodyZone_DR ECU generation 1";
CM_ SG_ 970 BD_SW_Var4 "BodyZone_DR software version car model variation 4";
CM_ SG_ 970 BD_SW_Var3 "BodyZone_DR software version car model variation 3";
CM_ SG_ 970 BD_SW_Var2 "BodyZone_DR software version car model variation 2";
CM_ SG_ 970 BD_SW_Var5 "BodyZone_DR software version car model variation 5";
CM_ SG_ 1734 DiagPhysReqToLDM_RL "Diagnostic Physical Request to LDM_RL";
CM_ SG_ 1718 DiagPhysReqToLDM_RR "Diagnostic Physical Request to LDM_RR";
CM_ SG_ 1702 DiagPhysReqToLDM_FL "Diagnostic Physical Request to LDM_FL";
CM_ SG_ 1686 DiagPhysReqToLDM_FR "Diagnostic Physical Request to LDM_FR";
CM_ SG_ 1574 DiagRespFromLDM_FL "Diagnostic Response from LDM_FL";
CM_ SG_ 1558 DiagRespFromLDM_FR "Diagnostic Response from LDM_FR";
CM_ SG_ 1606 DiagRespFromLDM_RL "Diagnostic Response from LDM_RL";
CM_ SG_ 1590 DiagRespFromLDM_RR "Diagnostic Response from LDM_RR";
CM_ SG_ 881 PTG_Half_Lock "Power Tail Gate Latch Half Lock";
CM_ SG_ 881 PTG_Open_Ratio "Power Tail Gate Open Ratio";
CM_ SG_ 881 PTG_Full_Lock "Power Tail Gate Latch Full Lock";
CM_ SG_ 881 PTG_Active_Sta "PTG Function Activation State";
CM_ SG_ 881 PTG_Warning_Sta "Power Tail Gate Warning";
CM_ SG_ 881 PTG_RDIL_Sta "Power Tail Gate Rear Direction Indicator Lamp State";
CM_ SG_ 881 PTG_Inner_SW_2 "Power Tail Gate Inner SW#2 State";
CM_ SG_ 881 PTG_Inner_SW_1 "Power Tail Gate Inner SW#1 State";
CM_ SG_ 881 PTG_Sys_Sta "PTG System Status";
CM_ SG_ 881 PTG_Is_Set_Height "PTG 'Set Open Height' Action Listener";
CM_ SG_ 881 PTG_AutoStaus "Power Tail Gate Auto Status";
CM_ SG_ 881 PTG_Exist "PTG Existence";
CM_ SG_ 881 PTG_Strut_Current "Power Tail Gate Lift Strut Motor Current";
CM_ SG_ 881 PTG_Cinch_Current "Power Tail Gate Cinch Motor Current";
CM_ SG_ 881 PTG_SW_Ver "Power Tail Gate ECU Software Version";
CM_ SG_ 881 PTG_HW_Ver "Power Tail Gate ECU Hardware Version";
CM_ SG_ 1684 DiagPhysReqToDSEAT "Diagnostic Physical Request to DSEAT";
CM_ SG_ 1700 DiagPhysReqToPSEAT "Diagnostic Physical Request to PSEAT";
CM_ SG_ 1716 DiagPhysReqToPTG "Diagnostic Physical Request to PTG";
CM_ SG_ 1556 DiagRespFromDSEAT "Diagnostic Response from DSEAT";
CM_ SG_ 1572 DiagRespFromPSEAT "Diagnostic Response from PSEAT";
CM_ SG_ 1588 DiagRespFromPTG "Diagnostic Response from PTG";
CM_ SG_ 854 PSEAT_SW_Ver "Passenger Seat Software Version Number";
CM_ SG_ 854 PSEAT_HW_Ver "Passenger Seat Hardware Version Number";
CM_ SG_ 854 DSEAT_SW_Ver "Driver Seat Software Version Number";
CM_ SG_ 854 DSEAT_HW_Ver "Driver Seat Hardware Version Number";
CM_ SG_ 854 DSEAT_Slid_Pos "Driver Seat Slider Position
Min=0, Max=240, Engineering Unit=mm, Offset=0 mm, Resolution=1 mm per bit, Invaild=255, Undefined=241 - 254";
CM_ SG_ 854 DSEAT_RL_Pos "Driver Seat Rear Lifter Position
Min=0, 
Max=60, Engineering Unit=mm, Offset=0 mm, Resolution=1 mm per bit, Invaild=255, Undefined=61 - 254";
CM_ SG_ 854 DSEAT_Rec_Pos "Driver Seat Recliner Position
Min=0, 
Max=80, Engineering Unit=deg, Offset=0 deg, Resolution=1 deg per bit, Invaild=255, Undefined=81 - 254";
CM_ SG_ 854 DSEAT_FL_Pos "Driver Seat Front Lifter Position
Min=0, Max=25, Engineering Unit=mm,  Offset=0 mm, Resolution=1 mm per bit, Invaild=255, Undefined=26 - 254";
CM_ SG_ 854 DSEAT_heater_sta "Driver seat heater status";
CM_ SG_ 854 DSEAT_Mode "Driver Seat Mode
0=manual, 1=power, 2=power & heater, 
3=power & ventilate, 
4=power & heater & ventilate, 
5=manual & heater, 
6=manual & ventilate, 
7=manual & heater & ventilate";
CM_ SG_ 854 DSEAT_Vent_Sta "Driver Seat Ventilate Staus";
CM_ SG_ 854 PSEAT_heater_sta "Passenger seat heater status";
CM_ SG_ 854 PSEAT_Mode "Passenger Seat Mode";
CM_ SG_ 854 PSEAT_Vent_Sta "Passenger Seat Ventilate Staus";
CM_ SG_ 854 DSEAT_AntiAct_Sta "Driver Seat Antitheft Activate Status";
CM_ SG_ 854 DSEAT_Anti_Sta "Driver Seat Antitheft Status";
CM_ SG_ 854 DSEAT_EntryAct_Sta "Driver Seat Entry Function Activate Status";
CM_ SG_ 854 DSEAT_EntryFun_Sta "Driver Seat Entry Function Status";
CM_ SG_ 854 DSEAT_Error_Sta "Driver Seat Error Status";
CM_ SG_ 854 PSEAT_Error_Sta "Passenger Seat Error Status";
CM_ SG_ 630 DCPortNeg_Temp "DC Port Negtive Pin Temperature";
CM_ SG_ 630 DCPortPos_Temp "DC Port Positive Pin Temperature";
CM_ SG_ 630 OBCACCSLimit "OBC AC Charger station Limit";
CM_ SG_ 630 HVInVolt "HV Input voltage";
CM_ SG_ 630 OBCDCVoltLm "OBC DC Voltage Limit";
CM_ SG_ 630 OBCDCCurLm "OBC DC Current Limit";
CM_ SG_ 630 ReChargerStaFromEvcc "ResarvationChargerStatusFromEVCC";
CM_ SG_ 630 OBCEna "OBC Enable Charging";
CM_ SG_ 630 LVBattDet12V "12V Battery Detect";
CM_ SG_ 1006 BD_APM_WinRCurrent_Sta "BodyZone_DR APM rear window operating current";
CM_ SG_ 1006 BD_APM_WinFCurrent_Sta "BodyZone_DR APM Driving window operating current";
CM_ SG_ 1006 BD_SYS_PowerTemp2_Sta "BodyZone_DR Detect temperature on power board";
CM_ SG_ 1006 BD_SYS_PowerTemp1_Sta "BodyZone_DR Detect temperature on power board";
CM_ SG_ 1006 BD_SYS_CtrlTemp_Sta "BodyZone_DR Detect temperature on Ctrl board";
CM_ SG_ 1006 BD_SYS_CtrlBDVolt_Sta "BodyZone_DR Detect voltage on Ctrl board";
CM_ SG_ 1006 BD_SEAT_VentCurrent_Sta "BodyZone_DR Left Seat Vent operating current";
CM_ SG_ 1006 BD_SEAT_HeatCurrent_Sta "BodyZone_DR Left Seat Heat operating current";
CM_ SG_ 1006 BD_SEAT_FrontLiftCurrent_Sta "BodyZone_DR Front Lift operating current";
CM_ SG_ 1006 BD_SEAT_RearLiftCurrent_Sta "BodyZone_DR Rear Lift Seat Recline operating current";
CM_ SG_ 1006 BD_SEAT_ReclineCurrent_Sta "BodyZone_DR Left Seat Recline operating current";
CM_ SG_ 1006 BD_SEAT_SlideCurrent_Sta "BodyZone_DR Left Seat Slide operating current";
CM_ SG_ 1006 BD_Door_RCurrent_Sta "Bodyzone_DR Driver side Front Door Handle operating current";
CM_ SG_ 1006 BD_Door_FCurrent_Sta "Bodyzone_DR Driver side Front Door Handle operating current";
CM_ SG_ 1006 BD_DSEAT_HeaterTemp_Sta "The signal is set to feedback on the heater¡¦s temperature on the D31H driver seat to Bodyzone_Dr. Therefore, once the temperature exceeds the designed value, then it can be detected.
";
CM_ SG_ 928 FDC_VCU_ReqHWReset_Cmd "OTA request hardware reset";
CM_ SG_ 928 FD4_CE100_2_CS "Checksum of FD4_CE100_2 (AUTOSAR E2E profile 1)

Polynomial 0x1D (x^8+x^4+x^3+x^2+1) Both start value and XOR value are 0x00.";
CM_ SG_ 928 FD4_CE100_2_RC "4-bit rolling counter for FD4_CE100_2
It starts counting from 0, ends at 14 and returns to zero (0~14).";
CM_ SG_ 1345 NM_ZONE_ML_Node_ID "Source Node Identifier";
CM_ SG_ 1345 NM_ZONE_ML_ERROR_State "Defined Error states of the CAN Controller";
CM_ SG_ 1345 NM_ZONE_ML_Active_WU "Active Wakeup Bit";
CM_ SG_ 1345 NM_ZONE_ML_CSB "NM Coordinator Sleep Bit";
CM_ SG_ 1345 NM_ZONE_ML_PNI "Partial Network Information Bit (PNI)";
CM_ SG_ 1345 NM_ZONE_ML_Rpt_Msg_Req "Repeat Message Request";
CM_ SG_ 1346 NM_ZONE_MR_Node_ID "Source Node Identifier";
CM_ SG_ 1346 NM_ZONE_MR_ERROR_State "Defined Error states of the CAN Controller";
CM_ SG_ 1346 NM_ZONE_MR_Active_WU "Active Wakeup Bit";
CM_ SG_ 1346 NM_ZONE_MR_CSB "NM Coordinator Sleep Bit";
CM_ SG_ 1346 NM_ZONE_MR_PNI "Partial Network Information Bit (PNI)";
CM_ SG_ 1346 NM_ZONE_MR_Rpt_Msg_Req "Repeat Message Request";
CM_ SG_ 1729 DiagPhysReqToZONE_ML "Diagnostic Physical Request to ZONE_ML";
CM_ SG_ 1730 DiagPhysReqToZONE_MR "Diagnostic Physical Request to ZONE_MR";
CM_ SG_ 1601 DiagRespFromZONE_ML "Diagnostic Response from ZONE_ML";
CM_ SG_ 1602 DiagRespFromZONE_MR "Diagnostic Response from ZONE_MR";
CM_ SG_ 597 IVI_MLSEATvent_Cmd "IVI ML SEAT Vent command";
CM_ SG_ 597 IVI_MRSEATvent_Cmd "IVI MR SEAT Vent command";
CM_ SG_ 597 IVI_MLFootLift_Cmd "IVI ML Foot Lift command";
CM_ SG_ 597 IVI_MLRecliner_Cmd "IVI ML SEAT Recliner command";
CM_ SG_ 597 IVI_MLSeatLift_Cmd "IVI ML SEAT Lift command";
CM_ SG_ 597 IVI_MLSlider_Cmd "IVI ML SEAT Slider command";
CM_ SG_ 597 IVI_MRFootLift_Cmd "IVI MR Foot Lift command";
CM_ SG_ 597 IVI_MRRecliner_Cmd "IVI MR SEAT Recliner command";
CM_ SG_ 597 IVI_MRSeatLift_Cmd "IVI MR SEAT Lift command";
CM_ SG_ 597 IVI_MRSlider_Cmd "IVI MR SEAT Slider command";
CM_ SG_ 597 IVI_MLFMost_Cmd "IVI ML SEAT Forward to Most command";
CM_ SG_ 597 IVI_MLNapMode_Cmd "IVI ML SEAT Nap Mode command";
CM_ SG_ 597 IVI_MLRestore_Cmd "IVI ML SEAT Restore command";
CM_ SG_ 597 IVI_MLSldRestore_Cmd "IVI ML SEAT Slider Restore command";
CM_ SG_ 597 IVI_MLZeroGravity_Cmd "IVI ML Zero Gravity command";
CM_ SG_ 597 IVI_MRFMost_Cmd "IVI MR SEAT Forward to Most command";
CM_ SG_ 597 IVI_MRNapMode_Cmd "IVI MR SEAT Nap Mode command";
CM_ SG_ 597 IVI_MRRestore_Cmd "IVI MR SEAT Restore command";
CM_ SG_ 597 IVI_MRSldRestore_Cmd "IVI MR SEAT Slider Restore command";
CM_ SG_ 597 IVI_MRZeroGravity_Cmd "IVI MR Zero Gravity command";
CM_ SG_ 597 IVI_LSEATvent_Cmd "IVI FL SEAT Vent command";
CM_ SG_ 597 IVI_RSEATvent_Cmd "IVI FR SEAT Vent command";
CM_ SG_ 953 ZFR_SYS_V2LRelayCurr_Sta "Zone output current of V2LRelay.";
CM_ SG_ 953 ZFR_SYS_TrailerBPlusCurr_Sta "Zone output current of TrailerBPlus.";
CM_ SG_ 953 ZFR_SYS_Trailer4Curr_Sta "Zone output current of Trailer4.";
CM_ SG_ 953 ZFR_SYS_Trailer3Curr_Sta "Zone output current of Trailer3.";
CM_ SG_ 953 ZFR_SYS_Trailer2Curr_Sta "Zone output current of Trailer2.";
CM_ SG_ 953 ZFR_SYS_Trailer1Curr_Sta "Zone output current of Trailer1.";
CM_ SG_ 953 ZFR_SYS_SOTXVCurr_Sta "Zone output current of SOTXV.";
CM_ SG_ 953 ZFR_SYS_SideMarkerCurr_Sta "Zone output current of SideMarker.";
CM_ SG_ 953 ZFR_SYS_Ref5VCurr_Sta "Zone output current of reference 5V pin.";
CM_ SG_ 953 ZFR_SYS_RearWasherCurr_Sta "Zone output current of RearWasher.";
CM_ SG_ 953 ZFR_SYS_RearDefogCurr_Sta "Zone output current of RearDefog.";
CM_ SG_ 953 ZFR_SYS_RadFanCurr_Sta "Zone output current of radiation fan control pin (low side PWM).";
CM_ SG_ 953 ZFR_SYS_LowBeamCurr_Sta "Zone output current of LowBeam.";
CM_ SG_ 953 ZFR_SYS_HornCurr_Sta "Zone output current of Horn.";
CM_ SG_ 953 ZFR_SYS_HighBeamCurr_Sta "Zone output current of HighBeam.";
CM_ SG_ 953 ZFR_SYS_FWiperLCurr_Sta "Zone output current of FWiperL.";
CM_ SG_ 953 ZFR_SYS_FWiperHCurr_Sta "Zone output current of FWiperH.";
CM_ SG_ 953 ZFR_SYS_FrontWasherCurr_Sta "Zone output current of FrontWasher";
CM_ SG_ 953 ZFR_SYS_FrontPosLampCurr_Sta "Zone output current of FrontPosLamp.";
CM_ SG_ 953 ZFR_SYS_FrontFogLampCurr_Sta "Zone output current of front fog lamp.";
CM_ SG_ 953 ZFR_SYS_EPBRelayCurr_Sta "Zone output current of EPBRelay.";
CM_ SG_ 953 ZFR_SYS_DRLRCurr_Sta "Zone output current of DRLR.";
CM_ SG_ 953 ZFR_SYS_DRLLCurr_Sta "Zone output current of DRLL.";
CM_ SG_ 953 ZFR_SYS_EDUInverterVolt_Sta "Monitor zone gen3 board EDU_Inverter (A-A1) voltage. Check the voltage to determine A-A1 power ON/OFF.";
CM_ SG_ 953 ZFR_SYS_BMSCCUVolt_Sta "Monitor zone gen3 board BMSCCU (A-B1) voltage. Check the voltage to determine A-B1 power ON/OFF.";
CM_ SG_ 953 FrPowerTemp2 "Detect temperature on ZONE power board";
CM_ SG_ 953 FrPowerTemp1 "Detect temperature on ZONE power board";
CM_ SG_ 953 FrCtrlTemp "Detect temperature on ZONE Ctrl board";
CM_ SG_ 953 ZFR_SYS_ChgInletLockCurr_Sta "Zone output current of ChgInletLock.";
CM_ SG_ 953 ZFR_SYS_ChgDoorLockCurr_Sta "Zone output current of ChgDoorLock.";
CM_ SG_ 953 FrPwrStdbyA2PlusCurr "Zone Fr 'Power_Standby_A2+' pin electric current";
CM_ SG_ 953 FrPwrStdbyA2Curr "Zone Fr 'Power_Standby_A2' pin electric current";
CM_ SG_ 953 FrPwrStdbyA1PlusCurr "Zone Fr 'Power_Standby_A1+' pin electric current";
CM_ SG_ 953 FrPwrONA3Curr "Zone Fr 'Power_ON_A3' pin electric current";
CM_ SG_ 953 FrPwrONA2Curr "Zone Fr 'Power_ON_A2' pin electric current";
CM_ SG_ 953 FrEDU_INVERTERCurr "Zone Fr 'INVERTER' pin electric current";
CM_ SG_ 953 FrBMS_CCU_CIRCurr "Zone Fr 'BMS_CCU_CIR' pin electric current";
CM_ SG_ 953 FrCtrlBDVolt "Detect voltage on ZONE Ctrl board";
CM_ SG_ 953 ZFR_SYS_BoardBatVolt_Sta "board battery voltage";
CM_ SG_ 953 FrIRC_1Curr "Zone Fr 'IRC_1' pin electric current";
CM_ SG_ 953 FrIRC_2Curr "Zone Fr 'IRC_2' pin electric current";
CM_ SG_ 953 ZFR_SYS_U155Temp_Sta "U155 board temperature";
CM_ SG_ 953 ZFR_SYS_U156Temp_Sta "U156 board temperature";
CM_ SG_ 953 ZFR_SYS_U5Temp_Sta "U5 board temperature";
CM_ SG_ 949 ZDR_SYS_VentPwrCurr_Sta "Zone output current of vent power pin.";
CM_ SG_ 949 ZDR_SYS_TrunkReleaseCurr_Sta "Zone output current of trunk release pin.";
CM_ SG_ 949 ZDR_SYS_RoomLampPwrCurr_Sta "Zone output current of room lamp power pin.";
CM_ SG_ 949 ZDR_SYS_ReverseLampCurr_Sta "Zone output current of reverse lamp pin.";
CM_ SG_ 949 ZDR_SYS_Ref5VCurr_Sta "Zone output current of reference 5V pin.";
CM_ SG_ 949 ZDR_SYS_RearWiperCurr_Sta "Zone output current of rear wiper pin.";
CM_ SG_ 949 ZDR_SYS_RearPosLampCurr_Sta "Zone output current of rear position lamp pin.";
CM_ SG_ 949 ZDR_SYS_RearFogLampCurr_Sta "Zone output current of rear fog lamp pin.";
CM_ SG_ 949 ZDR_SYS_OTDoorUnlockCurr_Sta "Zone output current of OT door unlock pin.";
CM_ SG_ 949 ZDR_SYS_OMirrorDefogCurr_Sta "Zone output current of outside mirror defog pin.";
CM_ SG_ 949 ZDR_SYS_ModeDriveCurr_Sta "Zone output current when mode drive motor is moving.";
CM_ SG_ 949 ZDR_SYS_MirrorFoldCurr_Sta "Zone output current when mirror fold/retract.";
CM_ SG_ 949 ZDR_SYS_LINStepPwrCurr_Sta "Zone output current of LINStepPwr.";
CM_ SG_ 949 ZDR_SYS_IntakeDriveCurr_Sta "Zone output current when intake drive motor is moving.";
CM_ SG_ 949 ZDR_SYS_HSWTempPwrCurr_Sta "Zone output current of HSWTempPwr.";
CM_ SG_ 949 ZDR_SYS_HSWHeaterPwrCurr_Sta "Zone output current of HSW heater power pin.";
CM_ SG_ 949 ZDR_SYS_HSWHeaterIndCurr_Sta "Zone output current of HSWHeaterInd.";
CM_ SG_ 949 ZDR_SYS_HazardLEDCurr_Sta "Zone output current of hazard LED light.";
CM_ SG_ 949 ZDR_SYS_FragrancePwrCurr_Sta "Zone output current of fragrance system power pin.";
CM_ SG_ 949 ZDR_SYS_DRDoorUnlockCurr_Sta "Zone output current of DR door unlock pin.";
CM_ SG_ 949 ZDR_SYS_DMSPwrCurr_Sta "Zone output current of DMSPwr.";
CM_ SG_ 949 ZDR_SYS_ColumnSWCurr_Sta "Zone output current of ColumnSW.";
CM_ SG_ 949 ZDR_SYS_CHMSLCurr_Sta "Zone output current of CHMSL power pin.";
CM_ SG_ 949 ZDR_SYS_BrakeLampLRCurr_Sta "Zone output current of brake lamp pin.";
CM_ SG_ 949 ZDR_SYS_AtmosLampCurr_Sta "Zone output current of atmosphere lamp pin.";
CM_ SG_ 949 ZDR_SYS_AntiGlareCurr_Sta "Zone output current of AntiGlare.";
CM_ SG_ 949 ZDR_SYS_AllDoorLockCurr_Sta "Zone output current of all door lock pin.";
CM_ SG_ 949 ZDR_SYS_CTDINDCurr_Sta "Zone output current of CTDIND.";
CM_ SG_ 949 ZDR_SYS_BSDLCurr_Sta "Zone output current of BSDL.";
CM_ SG_ 949 ZDR_SYS_BSDRCurr_Sta "Zone output current of BSDR.";
CM_ SG_ 949 DrPowerTemp2 "Detect temperature on ZONE power board";
CM_ SG_ 949 DrPowerTemp1 "Detect temperature on ZONE power board";
CM_ SG_ 949 DrCtrlTemp "Detect temperature on ZONE Ctrl board";
CM_ SG_ 949 ZDR_SYS_DrPwrStdbyA2Curr_Sta "Zone output current of DrPwrStdbyA2.";
CM_ SG_ 949 ZDR_SYS_AuBoxPwrN4Curr_Sta "Zone output current of audio box node 4 power pin.";
CM_ SG_ 949 ZDR_SYS_AuBoxPwrN3Curr_Sta "Zone output current of audio box node 3 power pin.";
CM_ SG_ 949 DrPwrStdbyACurr "Zone Dr 'Power_Standby_A' pin electric current";
CM_ SG_ 949 DrPwrONA2Curr "Zone Dr 'Power_ON_A2' pin electric current";
CM_ SG_ 949 DrPwrONA1Curr "Zone Dr 'Power_ON_A1' pin electric current";
CM_ SG_ 949 DrAuBoxPwrN2Curr "Zone Dr 'AUDIO BOX POWER NODE2' pin electric current";
CM_ SG_ 949 DrAuBoxPwrN1Curr "Zone Dr 'AUDIO BOX POWER NODE1' pin electric current";
CM_ SG_ 949 DrADASCurr "Zone Dr 'ADAS' pin electric current";
CM_ SG_ 949 DrCtrlBDVolt "Detect voltage on ZONE Ctrl board";
CM_ SG_ 949 ZDR_SYS_BoardBatVolt_Sta "board battery voltage";
CM_ SG_ 949 ZDR_SYS_U155Temp_Sta "U155 board temperature";
CM_ SG_ 949 ZDR_SYS_U156Temp_Sta "U156 board temperature";
CM_ SG_ 949 ZDR_SYS_U5Temp_Sta "U5 board temperature";
CM_ SG_ 2015 DiagFuncReqOBD "Diagnostic Functional Request from OBD Tester";
CM_ SG_ 1703 DiagPhysReqToPSD_L "Diagnostic Physical Request to PSD_L";
CM_ SG_ 1704 DiagPhysReqToPSD_R "Diagnostic Physical Request to PSD_R";
CM_ SG_ 1575 DiagRespFromPSD_L "Diagnostic Response from PSD_L";
CM_ SG_ 1576 DiagRespFromPSD_R "Diagnostic Response from PSD_R";
BA_DEF_ BO_ "GenMsgSendType" ENUM "Cycle","NoMsgSendType","IfActive","Event","CA","CE";
BA_DEF_ BO_ "GenMsgNrOfRepetition" INT 0 0;
BA_DEF_ BO_ "GenMsgILSupport" ENUM "No","Yes";
BA_DEF_ BO_ "GenMsgCycleTime" INT 0 0;
BA_DEF_ BO_ "DiagResponse" ENUM "No","Yes";
BA_DEF_ BO_ "DiagRequest" ENUM "No","Yes";
BA_DEF_ BO_ "NmMessage" ENUM "No","Yes";
BA_DEF_ BO_ "VFrameFormat" ENUM "StandardCAN","ExtendedCAN","reserved","reserved","reserved","reserved","reserved","reserved","reserved","reserved","reserved","reserved","reserved","reserved","StandardCAN_FD","ExtendedCAN_FD";
BA_DEF_ BO_ "DataID" STRING ;
BA_DEF_ BO_ "DoIPLogicalAddress" STRING ;
BA_DEF_ BO_ "CANFD_BRS" ENUM "0","1";
BA_DEF_ BO_ "GenMsgRequestable" INT 0 1;
BA_DEF_ SG_ "GenSigInvalidValue" HEX 0 0;
BA_DEF_ SG_ "GenSigStartValue" HEX 0 0;
BA_DEF_ SG_ "GenSigInactiveValue" HEX 0 0;
BA_DEF_ SG_ "GenSigRoutingTimeoutValue_String" STRING ;
BA_DEF_ SG_ "DataCenterDataType" STRING ;
BA_DEF_ SG_ "GenSigRoutingTimeoutValue" HEX 0 0;
BA_DEF_ SG_ "GenSigSendType" ENUM "Cycle","OnWrite","OnWriteWithRepetition","OnChange","OnChangeWithRepetition","IfActive","IfActiveWithRepetition","NoSigSendType","vector_leerstring";
BA_DEF_ SG_ "SigType" ENUM "Default","Range","RangeSigned","ASCII","Discrete","Control","ReferencePGN","DTC","StringDelimiter","StringLength","StringLengthControl","MessageCounter","MessageChecksum";
BA_DEF_ SG_ "GenSigILSupport" ENUM "No","Yes";
BA_DEF_DEF_ "GenMsgSendType" "Cycle";
BA_DEF_DEF_ "GenMsgNrOfRepetition" 0;
BA_DEF_DEF_ "GenMsgILSupport" "Yes";
BA_DEF_DEF_ "GenMsgCycleTime" 100;
BA_DEF_DEF_ "DiagResponse" "No";
BA_DEF_DEF_ "DiagRequest" "No";
BA_DEF_DEF_ "NmMessage" "No";
BA_DEF_DEF_ "VFrameFormat" "StandardCAN";
BA_DEF_DEF_ "DataID" "";
BA_DEF_DEF_ "DoIPLogicalAddress" "";
BA_DEF_DEF_ "CANFD_BRS" "1";
BA_DEF_DEF_ "GenMsgRequestable" 1;
BA_DEF_DEF_ "GenSigInvalidValue" 0;
BA_DEF_DEF_ "GenSigStartValue" 0;
BA_DEF_DEF_ "GenSigInactiveValue" 0;
BA_DEF_DEF_ "GenSigRoutingTimeoutValue_String" "";
BA_DEF_DEF_ "DataCenterDataType" "";
BA_DEF_DEF_ "GenSigRoutingTimeoutValue" 0;
BA_DEF_DEF_ "GenSigSendType" "Cycle";
BA_DEF_DEF_ "SigType" "Default";
BA_DEF_DEF_ "GenSigILSupport" "Yes";
BA_ "VFrameFormat" BO_ 778 14;
BA_ "VFrameFormat" BO_ 804 14;
BA_ "GenMsgCycleTime" BO_ 965 5000;
BA_ "VFrameFormat" BO_ 965 14;
BA_ "GenMsgCycleTime" BO_ 969 5000;
BA_ "VFrameFormat" BO_ 969 14;
BA_ "GenMsgCycleTime" BO_ 1284 0;
BA_ "NmMessage" BO_ 1284 1;
BA_ "GenMsgSendType" BO_ 1284 3;
BA_ "GenMsgCycleTime" BO_ 1285 0;
BA_ "GenMsgSendType" BO_ 1285 3;
BA_ "GenMsgCycleTime" BO_ 1344 0;
BA_ "NmMessage" BO_ 1344 1;
BA_ "GenMsgSendType" BO_ 1344 3;
BA_ "GenMsgCycleTime" BO_ 1540 0;
BA_ "DiagResponse" BO_ 1540 1;
BA_ "GenMsgSendType" BO_ 1540 3;
BA_ "VFrameFormat" BO_ 1540 14;
BA_ "DoIPLogicalAddress" BO_ 1540 "0x0684";
BA_ "GenMsgCycleTime" BO_ 1541 0;
BA_ "DiagResponse" BO_ 1541 1;
BA_ "GenMsgSendType" BO_ 1541 3;
BA_ "VFrameFormat" BO_ 1541 14;
BA_ "DoIPLogicalAddress" BO_ 1541 "0x0685";
BA_ "GenMsgCycleTime" BO_ 1573 0;
BA_ "DiagResponse" BO_ 1573 1;
BA_ "GenMsgSendType" BO_ 1573 3;
BA_ "VFrameFormat" BO_ 1573 14;
BA_ "DoIPLogicalAddress" BO_ 1573 "0x06A5";
BA_ "GenMsgCycleTime" BO_ 1589 0;
BA_ "DiagResponse" BO_ 1589 1;
BA_ "GenMsgSendType" BO_ 1589 3;
BA_ "VFrameFormat" BO_ 1589 14;
BA_ "DoIPLogicalAddress" BO_ 1589 "0x06B5";
BA_ "GenMsgCycleTime" BO_ 1600 0;
BA_ "DiagResponse" BO_ 1600 1;
BA_ "GenMsgSendType" BO_ 1600 3;
BA_ "VFrameFormat" BO_ 1600 14;
BA_ "DoIPLogicalAddress" BO_ 1600 "0x06C0";
BA_ "GenMsgCycleTime" BO_ 1605 0;
BA_ "DiagResponse" BO_ 1605 1;
BA_ "GenMsgSendType" BO_ 1605 3;
BA_ "VFrameFormat" BO_ 1605 14;
BA_ "DoIPLogicalAddress" BO_ 1605 "0x06C5";
BA_ "GenMsgNrOfRepetition" BO_ 794 1;
BA_ "GenMsgSendType" BO_ 794 5;
BA_ "VFrameFormat" BO_ 794 14;
BA_ "GenMsgNrOfRepetition" BO_ 858 1;
BA_ "GenMsgCycleTime" BO_ 858 200;
BA_ "GenMsgSendType" BO_ 858 5;
BA_ "VFrameFormat" BO_ 858 14;
BA_ "GenMsgCycleTime" BO_ 1287 0;
BA_ "NmMessage" BO_ 1287 1;
BA_ "GenMsgSendType" BO_ 1287 3;
BA_ "GenMsgCycleTime" BO_ 1543 0;
BA_ "DiagResponse" BO_ 1543 1;
BA_ "GenMsgSendType" BO_ 1543 3;
BA_ "VFrameFormat" BO_ 1543 14;
BA_ "DoIPLogicalAddress" BO_ 1543 "0x0687";
BA_ "GenMsgNrOfRepetition" BO_ 859 1;
BA_ "GenMsgSendType" BO_ 859 5;
BA_ "VFrameFormat" BO_ 859 14;
BA_ "GenMsgCycleTime" BO_ 1007 20;
BA_ "VFrameFormat" BO_ 1007 14;
BA_ "GenMsgCycleTime" BO_ 971 5000;
BA_ "VFrameFormat" BO_ 971 14;
BA_ "GenMsgNrOfRepetition" BO_ 795 1;
BA_ "GenMsgSendType" BO_ 795 5;
BA_ "VFrameFormat" BO_ 795 14;
BA_ "GenMsgCycleTime" BO_ 1286 0;
BA_ "NmMessage" BO_ 1286 1;
BA_ "GenMsgSendType" BO_ 1286 3;
BA_ "GenMsgCycleTime" BO_ 1542 0;
BA_ "DiagResponse" BO_ 1542 1;
BA_ "GenMsgSendType" BO_ 1542 3;
BA_ "VFrameFormat" BO_ 1542 14;
BA_ "DoIPLogicalAddress" BO_ 1542 "0x0686";
BA_ "GenMsgCycleTime" BO_ 1671 0;
BA_ "DiagRequest" BO_ 1671 1;
BA_ "GenMsgSendType" BO_ 1671 3;
BA_ "VFrameFormat" BO_ 1671 14;
BA_ "DoIPLogicalAddress" BO_ 1671 "0x0687";
BA_ "GenMsgCycleTime" BO_ 1670 0;
BA_ "DiagRequest" BO_ 1670 1;
BA_ "GenMsgSendType" BO_ 1670 3;
BA_ "VFrameFormat" BO_ 1670 14;
BA_ "DoIPLogicalAddress" BO_ 1670 "0x0686";
BA_ "GenMsgCycleTime" BO_ 376 50;
BA_ "DataID" BO_ 376 "0xEB55";
BA_ "VFrameFormat" BO_ 376 14;
BA_ "GenMsgCycleTime" BO_ 970 5000;
BA_ "VFrameFormat" BO_ 970 14;
BA_ "GenMsgCycleTime" BO_ 1734 0;
BA_ "DiagRequest" BO_ 1734 1;
BA_ "GenMsgSendType" BO_ 1734 3;
BA_ "VFrameFormat" BO_ 1734 14;
BA_ "DoIPLogicalAddress" BO_ 1734 "0x06C6";
BA_ "GenMsgCycleTime" BO_ 1718 0;
BA_ "DiagRequest" BO_ 1718 1;
BA_ "GenMsgSendType" BO_ 1718 3;
BA_ "VFrameFormat" BO_ 1718 14;
BA_ "DoIPLogicalAddress" BO_ 1718 "0x06B6";
BA_ "GenMsgCycleTime" BO_ 1702 0;
BA_ "DiagRequest" BO_ 1702 1;
BA_ "GenMsgSendType" BO_ 1702 3;
BA_ "VFrameFormat" BO_ 1702 14;
BA_ "DoIPLogicalAddress" BO_ 1702 "0x06A6";
BA_ "GenMsgCycleTime" BO_ 1686 0;
BA_ "DiagRequest" BO_ 1686 1;
BA_ "GenMsgSendType" BO_ 1686 3;
BA_ "VFrameFormat" BO_ 1686 14;
BA_ "DoIPLogicalAddress" BO_ 1686 "0x0696";
BA_ "GenMsgCycleTime" BO_ 1574 0;
BA_ "DiagResponse" BO_ 1574 1;
BA_ "GenMsgSendType" BO_ 1574 3;
BA_ "VFrameFormat" BO_ 1574 14;
BA_ "DoIPLogicalAddress" BO_ 1574 "0x06A6";
BA_ "GenMsgCycleTime" BO_ 1558 0;
BA_ "DiagResponse" BO_ 1558 1;
BA_ "GenMsgSendType" BO_ 1558 3;
BA_ "VFrameFormat" BO_ 1558 14;
BA_ "DoIPLogicalAddress" BO_ 1558 "0x0696";
BA_ "GenMsgCycleTime" BO_ 1606 0;
BA_ "DiagResponse" BO_ 1606 1;
BA_ "GenMsgSendType" BO_ 1606 3;
BA_ "VFrameFormat" BO_ 1606 14;
BA_ "DoIPLogicalAddress" BO_ 1606 "0x06C6";
BA_ "GenMsgCycleTime" BO_ 1590 0;
BA_ "DiagResponse" BO_ 1590 1;
BA_ "GenMsgSendType" BO_ 1590 3;
BA_ "VFrameFormat" BO_ 1590 14;
BA_ "DoIPLogicalAddress" BO_ 1590 "0x06B6";
BA_ "GenMsgCycleTime" BO_ 1684 0;
BA_ "DiagRequest" BO_ 1684 1;
BA_ "GenMsgSendType" BO_ 1684 3;
BA_ "VFrameFormat" BO_ 1684 14;
BA_ "DoIPLogicalAddress" BO_ 1684 "0x0694";
BA_ "GenMsgCycleTime" BO_ 1700 0;
BA_ "DiagRequest" BO_ 1700 1;
BA_ "GenMsgSendType" BO_ 1700 3;
BA_ "VFrameFormat" BO_ 1700 14;
BA_ "DoIPLogicalAddress" BO_ 1700 "0x06A4";
BA_ "GenMsgCycleTime" BO_ 1716 0;
BA_ "DiagRequest" BO_ 1716 1;
BA_ "GenMsgSendType" BO_ 1716 3;
BA_ "VFrameFormat" BO_ 1716 14;
BA_ "DoIPLogicalAddress" BO_ 1716 "0x06B4";
BA_ "GenMsgCycleTime" BO_ 1556 0;
BA_ "DiagResponse" BO_ 1556 1;
BA_ "GenMsgSendType" BO_ 1556 3;
BA_ "VFrameFormat" BO_ 1556 14;
BA_ "DoIPLogicalAddress" BO_ 1556 "0x0694";
BA_ "GenMsgCycleTime" BO_ 1572 0;
BA_ "DiagResponse" BO_ 1572 1;
BA_ "GenMsgSendType" BO_ 1572 3;
BA_ "VFrameFormat" BO_ 1572 14;
BA_ "DoIPLogicalAddress" BO_ 1572 "0x06A4";
BA_ "GenMsgCycleTime" BO_ 1588 0;
BA_ "DiagResponse" BO_ 1588 1;
BA_ "GenMsgSendType" BO_ 1588 3;
BA_ "VFrameFormat" BO_ 1588 14;
BA_ "DoIPLogicalAddress" BO_ 1588 "0x06B4";
BA_ "GenMsgNrOfRepetition" BO_ 854 1;
BA_ "GenMsgCycleTime" BO_ 854 200;
BA_ "GenMsgSendType" BO_ 854 5;
BA_ "VFrameFormat" BO_ 854 14;
BA_ "GenMsgNrOfRepetition" BO_ 630 1;
BA_ "GenMsgSendType" BO_ 630 5;
BA_ "VFrameFormat" BO_ 630 14;
BA_ "GenMsgCycleTime" BO_ 1006 20;
BA_ "VFrameFormat" BO_ 1006 14;
BA_ "GenMsgNrOfRepetition" BO_ 928 1;
BA_ "DataID" BO_ 928 "0x3A01";
BA_ "GenMsgSendType" BO_ 928 5;
BA_ "VFrameFormat" BO_ 928 14;
BA_ "GenMsgCycleTime" BO_ 1345 0;
BA_ "NmMessage" BO_ 1345 1;
BA_ "GenMsgSendType" BO_ 1345 3;
BA_ "GenMsgCycleTime" BO_ 1346 0;
BA_ "NmMessage" BO_ 1346 1;
BA_ "GenMsgSendType" BO_ 1346 3;
BA_ "GenMsgCycleTime" BO_ 1729 0;
BA_ "DiagRequest" BO_ 1729 1;
BA_ "GenMsgSendType" BO_ 1729 3;
BA_ "VFrameFormat" BO_ 1729 14;
BA_ "DoIPLogicalAddress" BO_ 1729 "0x06C1";
BA_ "GenMsgCycleTime" BO_ 1730 0;
BA_ "DiagRequest" BO_ 1730 1;
BA_ "GenMsgSendType" BO_ 1730 3;
BA_ "VFrameFormat" BO_ 1730 14;
BA_ "DoIPLogicalAddress" BO_ 1730 "0x06C2";
BA_ "GenMsgCycleTime" BO_ 1601 0;
BA_ "DiagResponse" BO_ 1601 1;
BA_ "GenMsgSendType" BO_ 1601 3;
BA_ "VFrameFormat" BO_ 1601 14;
BA_ "DoIPLogicalAddress" BO_ 1601 "0x06C1";
BA_ "GenMsgCycleTime" BO_ 1602 0;
BA_ "DiagResponse" BO_ 1602 1;
BA_ "GenMsgSendType" BO_ 1602 3;
BA_ "VFrameFormat" BO_ 1602 14;
BA_ "DoIPLogicalAddress" BO_ 1602 "0x06C2";
BA_ "GenMsgNrOfRepetition" BO_ 597 1;
BA_ "GenMsgCycleTime" BO_ 597 200;
BA_ "GenMsgSendType" BO_ 597 5;
BA_ "VFrameFormat" BO_ 597 14;
BA_ "GenMsgCycleTime" BO_ 953 20;
BA_ "VFrameFormat" BO_ 953 14;
BA_ "GenMsgCycleTime" BO_ 949 20;
BA_ "VFrameFormat" BO_ 949 14;
BA_ "GenMsgCycleTime" BO_ 2015 0;
BA_ "DiagRequest" BO_ 2015 1;
BA_ "GenMsgSendType" BO_ 2015 3;
BA_ "VFrameFormat" BO_ 2015 14;
BA_ "DoIPLogicalAddress" BO_ 2015 "0xE000 ";
BA_ "GenMsgCycleTime" BO_ 1703 0;
BA_ "DiagRequest" BO_ 1703 1;
BA_ "GenMsgSendType" BO_ 1703 3;
BA_ "VFrameFormat" BO_ 1703 14;
BA_ "DoIPLogicalAddress" BO_ 1703 "0x06A7";
BA_ "GenMsgCycleTime" BO_ 1704 0;
BA_ "DiagRequest" BO_ 1704 1;
BA_ "GenMsgSendType" BO_ 1704 3;
BA_ "VFrameFormat" BO_ 1704 14;
BA_ "DoIPLogicalAddress" BO_ 1704 "0x06A8";
BA_ "GenMsgCycleTime" BO_ 1575 0;
BA_ "DiagResponse" BO_ 1575 1;
BA_ "GenMsgSendType" BO_ 1575 3;
BA_ "VFrameFormat" BO_ 1575 14;
BA_ "DoIPLogicalAddress" BO_ 1575 "0x06A7";
BA_ "GenMsgCycleTime" BO_ 1576 0;
BA_ "DiagResponse" BO_ 1576 1;
BA_ "GenMsgSendType" BO_ 1576 3;
BA_ "VFrameFormat" BO_ 1576 14;
BA_ "DoIPLogicalAddress" BO_ 1576 "0x06A8";
BA_ "GenSigInvalidValue" SG_ 778 EAC_Temp 255;
BA_ "GenSigStartValue" SG_ 778 EAC_Temp 101;
BA_ "GenSigRoutingTimeoutValue_String" SG_ 778 EAC_Temp "0xFF";
BA_ "GenSigInactiveValue" SG_ 778 EAC_Temp 255;
BA_ "GenSigRoutingTimeoutValue" SG_ 778 EAC_Temp 255;
BA_ "DataCenterDataType" SG_ 778 EAC_Temp "Decimal";
BA_ "DataCenterDataType" SG_ 778 EAC_DrvVoltFalt "Varchar(10)";
BA_ "DataCenterDataType" SG_ 778 EAC_MotorLackFalt "Varchar(10)";
BA_ "DataCenterDataType" SG_ 778 EAC_OvLoadFalt "Varchar(10)";
BA_ "DataCenterDataType" SG_ 778 EAC_TempSnsrFalt "Varchar(10)";
BA_ "DataCenterDataType" SG_ 778 COMP_ComLost "Varchar(10)";
BA_ "DataCenterDataType" SG_ 778 COMP_IPM_HWFLt "Varchar(10)";
BA_ "DataCenterDataType" SG_ 778 COMP_IPM_TempOverFlt "Varchar(10)";
BA_ "DataCenterDataType" SG_ 778 COMP_CurOverProtect "Varchar(10)";
BA_ "DataCenterDataType" SG_ 778 COMP_VoltOverErr "Varchar(10)";
BA_ "DataCenterDataType" SG_ 778 COMP_VoltLessErr "Varchar(10)";
BA_ "DataCenterDataType" SG_ 778 COMP_CtrlCircFlt "Varchar(10)";
BA_ "DataCenterDataType" SG_ 778 COMP_Sta "Varchar(15)";
BA_ "GenSigInvalidValue" SG_ 778 COMP_StatorSpd 16383;
BA_ "GenSigStartValue" SG_ 778 COMP_StatorSpd 16383;
BA_ "GenSigRoutingTimeoutValue_String" SG_ 778 COMP_StatorSpd "0x3FFF";
BA_ "GenSigInactiveValue" SG_ 778 COMP_StatorSpd 16383;
BA_ "GenSigRoutingTimeoutValue" SG_ 778 COMP_StatorSpd 16383;
BA_ "DataCenterDataType" SG_ 778 COMP_ConCur "Varchar(10)";
BA_ "DataCenterDataType" SG_ 778 COMP_ConVolt "Varchar(10)";
BA_ "GenSigInvalidValue" SG_ 778 COMP_ActualPwr 8191;
BA_ "GenSigStartValue" SG_ 778 COMP_ActualPwr 8191;
BA_ "GenSigRoutingTimeoutValue_String" SG_ 778 COMP_ActualPwr "0x1FFF";
BA_ "GenSigInactiveValue" SG_ 778 COMP_ActualPwr 8191;
BA_ "GenSigRoutingTimeoutValue" SG_ 778 COMP_ActualPwr 8191;
BA_ "DataCenterDataType" SG_ 778 COMP_ActualPwr "Varchar(10)";
BA_ "GenSigInvalidValue" SG_ 778 PTC1_PowerConsumption 255;
BA_ "GenSigRoutingTimeoutValue_String" SG_ 778 PTC1_PowerConsumption "0xFF";
BA_ "GenSigRoutingTimeoutValue" SG_ 778 PTC1_PowerConsumption 255;
BA_ "DataCenterDataType" SG_ 778 PTC1_PowerConsumption "Varchar(10)";
BA_ "GenSigInvalidValue" SG_ 778 PTC1_IGBTTem 255;
BA_ "GenSigRoutingTimeoutValue_String" SG_ 778 PTC1_IGBTTem "0xFF";
BA_ "GenSigRoutingTimeoutValue" SG_ 778 PTC1_IGBTTem 255;
BA_ "GenSigInvalidValue" SG_ 778 PTC1_ClntTempOtlt 255;
BA_ "GenSigRoutingTimeoutValue_String" SG_ 778 PTC1_ClntTempOtlt "0xFF";
BA_ "GenSigRoutingTimeoutValue" SG_ 778 PTC1_ClntTempOtlt 255;
BA_ "GenSigInvalidValue" SG_ 778 PTC1_ClntTempInlt 255;
BA_ "GenSigRoutingTimeoutValue_String" SG_ 778 PTC1_ClntTempInlt "0xFF";
BA_ "GenSigRoutingTimeoutValue" SG_ 778 PTC1_ClntTempInlt 255;
BA_ "GenSigInvalidValue" SG_ 778 PTC1_ActuHiCrnt 255;
BA_ "GenSigRoutingTimeoutValue_String" SG_ 778 PTC1_ActuHiCrnt "0xFF";
BA_ "GenSigRoutingTimeoutValue" SG_ 778 PTC1_ActuHiCrnt 255;
BA_ "GenSigRoutingTimeoutValue_String" SG_ 778 PTC1_WrkngSts "0x0";
BA_ "GenSigRoutingTimeoutValue_String" SG_ 778 PTC1_ClntInltOverTemProtn "0x0";
BA_ "GenSigRoutingTimeoutValue_String" SG_ 778 PTC1_ClntInltTemSnsrFlt "0x0";
BA_ "GenSigRoutingTimeoutValue_String" SG_ 778 PTC1_ClntOtltOverTemProtn "0x0";
BA_ "GenSigRoutingTimeoutValue_String" SG_ 778 PTC1_ClntOtltTemSnsrFlt "0x0";
BA_ "GenSigRoutingTimeoutValue_String" SG_ 778 PTC1_CommError "0x0";
BA_ "GenSigRoutingTimeoutValue_String" SG_ 778 PTC1_CoreOrIGBTOpenErr "0x0";
BA_ "GenSigRoutingTimeoutValue_String" SG_ 778 PTC1_HiCrntSnsrFlt "0x0";
BA_ "GenSigRoutingTimeoutValue_String" SG_ 778 PTC1_HVDisconnectProtn "0x0";
BA_ "GenSigRoutingTimeoutValue_String" SG_ 778 PTC1_HVOverCrntProtn "0x0";
BA_ "GenSigRoutingTimeoutValue_String" SG_ 778 PTC1_IGBTOverTemProtn "0x0";
BA_ "GenSigRoutingTimeoutValue_String" SG_ 778 PTC1_IGBTShrtErr "0x0";
BA_ "GenSigRoutingTimeoutValue_String" SG_ 778 PTC1_IGBTTemSnsrFlt "0x0";
BA_ "GenSigRoutingTimeoutValue_String" SG_ 778 PTC1_MmryFlt "0x0";
BA_ "GenSigRoutingTimeoutValue_String" SG_ 778 PTC1_PCBOverTempProtn "0x0";
BA_ "GenSigRoutingTimeoutValue_String" SG_ 778 PTC1_PCBTempSnsrFlt "0x0";
BA_ "GenSigRoutingTimeoutValue_String" SG_ 778 PTC1_VbatVtgProtn "0x0";
BA_ "GenSigRoutingTimeoutValue_String" SG_ 778 PTC1_VbatVtgSnsrFlt "0x0";
BA_ "GenSigRoutingTimeoutValue_String" SG_ 778 PTC1_VbatVtgUnstable "0x0";
BA_ "GenSigSendType" SG_ 1284 NM_ZONE_FR_Node_ID 7;
BA_ "GenSigSendType" SG_ 1284 NM_ZONE_FR_PNI 7;
BA_ "GenSigSendType" SG_ 1284 NM_ZONE_FR_Active_WU 7;
BA_ "GenSigSendType" SG_ 1284 NM_ZONE_FR_CSB 7;
BA_ "GenSigSendType" SG_ 1284 NM_ZONE_FR_Rpt_Msg_Req 7;
BA_ "GenSigSendType" SG_ 1284 NM_ZONE_FR_ERROR_State 7;
BA_ "GenSigSendType" SG_ 1285 NM_DKC_Node_ID 7;
BA_ "GenSigSendType" SG_ 1285 NM_DKC_PNI 7;
BA_ "GenSigSendType" SG_ 1285 NM_DKC_Active_WU 7;
BA_ "GenSigSendType" SG_ 1285 NM_DKC_CSB 7;
BA_ "GenSigSendType" SG_ 1285 NM_DKC_Rpt_Msg_Req 7;
BA_ "GenSigSendType" SG_ 1285 NM_DKC_ERROR_State 7;
BA_ "GenSigSendType" SG_ 1344 NM_ZONE_DR_Node_ID 7;
BA_ "GenSigSendType" SG_ 1344 NM_ZONE_DR_PNI 7;
BA_ "GenSigSendType" SG_ 1344 NM_ZONE_DR_Active_WU 7;
BA_ "GenSigSendType" SG_ 1344 NM_ZONE_DR_CSB 7;
BA_ "GenSigSendType" SG_ 1344 NM_ZONE_DR_Rpt_Msg_Req 7;
BA_ "GenSigSendType" SG_ 1344 NM_ZONE_DR_ERROR_State 7;
BA_ "GenSigSendType" SG_ 1540 DiagRespFromZONE_FR 3;
BA_ "GenSigSendType" SG_ 1541 DiagRespFromDKC 3;
BA_ "GenSigSendType" SG_ 1573 DiagRespFromAirPTC 3;
BA_ "GenSigSendType" SG_ 1589 DiagRespFromWPTC 3;
BA_ "GenSigSendType" SG_ 1600 DiagRespFromZONE_DR 3;
BA_ "GenSigSendType" SG_ 1605 DiagRespFromCompress 3;
BA_ "GenSigInvalidValue" SG_ 794 BD_APM_WinFOpened_Sta 127;
BA_ "GenSigStartValue" SG_ 794 BD_APM_WinFOpened_Sta 127;
BA_ "GenSigRoutingTimeoutValue_String" SG_ 794 BD_APM_WinFOpened_Sta "0x7F";
BA_ "GenSigInactiveValue" SG_ 794 BD_APM_WinFOpened_Sta 127;
BA_ "GenSigRoutingTimeoutValue" SG_ 794 BD_APM_WinFOpened_Sta 127;
BA_ "GenSigInvalidValue" SG_ 794 BD_APM_WinROpened_Sta 127;
BA_ "GenSigStartValue" SG_ 794 BD_APM_WinROpened_Sta 127;
BA_ "GenSigRoutingTimeoutValue_String" SG_ 794 BD_APM_WinROpened_Sta "0x7F";
BA_ "GenSigInactiveValue" SG_ 794 BD_APM_WinROpened_Sta 127;
BA_ "GenSigRoutingTimeoutValue" SG_ 794 BD_APM_WinROpened_Sta 127;
BA_ "GenSigRoutingTimeoutValue_String" SG_ 794 BD_Door_FHandleClose_Sta "0x0";
BA_ "GenSigSendType" SG_ 794 BD_Door_FHandleClose_Sta 3;
BA_ "GenSigSendType" SG_ 794 BD_Door_FHandleHalf_Sta 3;
BA_ "GenSigRoutingTimeoutValue_String" SG_ 794 BD_Door_RHandleClose_Sta "0x0";
BA_ "GenSigSendType" SG_ 794 BD_Door_RHandleClose_Sta 3;
BA_ "GenSigSendType" SG_ 794 BD_Door_RHandleHalf_Sta 3;
BA_ "GenSigInvalidValue" SG_ 858 BD_DSEAT_SlidPos_Sta 1023;
BA_ "GenSigStartValue" SG_ 858 BD_DSEAT_SlidPos_Sta 1023;
BA_ "GenSigRoutingTimeoutValue_String" SG_ 858 BD_DSEAT_SlidPos_Sta "0x3FF";
BA_ "GenSigInactiveValue" SG_ 858 BD_DSEAT_SlidPos_Sta 1023;
BA_ "GenSigRoutingTimeoutValue" SG_ 858 BD_DSEAT_SlidPos_Sta 1023;
BA_ "GenSigInvalidValue" SG_ 858 BD_DSEAT_RecPos_Sta 2047;
BA_ "GenSigStartValue" SG_ 858 BD_DSEAT_RecPos_Sta 2047;
BA_ "GenSigRoutingTimeoutValue_String" SG_ 858 BD_DSEAT_RecPos_Sta "0x7FF";
BA_ "GenSigInactiveValue" SG_ 858 BD_DSEAT_RecPos_Sta 2047;
BA_ "GenSigRoutingTimeoutValue" SG_ 858 BD_DSEAT_RecPos_Sta 2047;
BA_ "GenSigInvalidValue" SG_ 858 BD_DSEAT_FLPos_Sta 511;
BA_ "GenSigStartValue" SG_ 858 BD_DSEAT_FLPos_Sta 511;
BA_ "GenSigRoutingTimeoutValue_String" SG_ 858 BD_DSEAT_FLPos_Sta "0x1FF";
BA_ "GenSigInactiveValue" SG_ 858 BD_DSEAT_FLPos_Sta 511;
BA_ "GenSigRoutingTimeoutValue" SG_ 858 BD_DSEAT_FLPos_Sta 511;
BA_ "GenSigInvalidValue" SG_ 858 BD_DSEAT_RLPos_Sta 511;
BA_ "GenSigStartValue" SG_ 858 BD_DSEAT_RLPos_Sta 511;
BA_ "GenSigRoutingTimeoutValue_String" SG_ 858 BD_DSEAT_RLPos_Sta "0x1FF";
BA_ "GenSigInactiveValue" SG_ 858 BD_DSEAT_RLPos_Sta 511;
BA_ "GenSigRoutingTimeoutValue" SG_ 858 BD_DSEAT_RLPos_Sta 511;
BA_ "GenSigSendType" SG_ 858 BD_DSEAT_Mode_Sta 3;
BA_ "GenSigSendType" SG_ 858 BD_DSEAT_AntiAct_Sta 3;
BA_ "GenSigSendType" SG_ 858 BD_DSEAT_Anti_Sta 3;
BA_ "GenSigSendType" SG_ 858 BD_DSEAT_EntryAct_Sta 3;
BA_ "GenSigSendType" SG_ 858 BD_DSEAT_EntryFun_Sta 3;
BA_ "GenSigSendType" SG_ 858 BD_DSEAT_Error_Sta 3;
BA_ "GenSigSendType" SG_ 858 BD_DSEAT_Vent_Sta 3;
BA_ "GenSigSendType" SG_ 858 BD_DSEAT_heater_Sta 3;
BA_ "GenSigRoutingTimeoutValue_String" SG_ 858 BD_DSEAT_MemSet_Sta "0x0";
BA_ "GenSigSendType" SG_ 858 BD_DSEAT_MemSet_Sta 3;
BA_ "GenSigRoutingTimeoutValue_String" SG_ 858 BD_DSEAT_StopKeepMove_Sta "0x3";
BA_ "GenSigRoutingTimeoutValue" SG_ 858 BD_DSEAT_StopKeepMove_Sta 3;
BA_ "GenSigSendType" SG_ 858 BD_DSEAT_StopKeepMove_Sta 3;
BA_ "GenSigSendType" SG_ 1287 NM_BodyZone_DR_Node_ID 7;
BA_ "GenSigSendType" SG_ 1287 NM_BodyZone_DR_Rpt_Msg_Req 7;
BA_ "GenSigSendType" SG_ 1287 NM_BodyZone_DR_CSB 7;
BA_ "GenSigSendType" SG_ 1287 NM_BodyZone_DR_Active_WU 7;
BA_ "GenSigSendType" SG_ 1287 NM_BodyZone_DR_PNI 7;
BA_ "GenSigSendType" SG_ 1287 NM_BodyZone_DR_ERROR_State 7;
BA_ "GenSigSendType" SG_ 1543 DiagRespFromBodyZone_DR 3;
BA_ "GenSigInvalidValue" SG_ 859 BP_PTG_PowerLatch_Sta 7;
BA_ "GenSigStartValue" SG_ 859 BP_PTG_PowerLatch_Sta 7;
BA_ "GenSigRoutingTimeoutValue_String" SG_ 859 BP_PTG_PowerLatch_Sta "0x7";
BA_ "GenSigInactiveValue" SG_ 859 BP_PTG_PowerLatch_Sta 7;
BA_ "GenSigRoutingTimeoutValue" SG_ 859 BP_PTG_PowerLatch_Sta 7;
BA_ "GenSigSendType" SG_ 859 BP_PTG_PowerLatch_Sta 3;
BA_ "GenSigSendType" SG_ 859 BP_PTG_DebugMode_Sta 3;
BA_ "GenSigInvalidValue" SG_ 859 BP_PTG_LatchSeg_Sta 3;
BA_ "GenSigStartValue" SG_ 859 BP_PTG_LatchSeg_Sta 3;
BA_ "GenSigRoutingTimeoutValue_String" SG_ 859 BP_PTG_LatchSeg_Sta "0x3";
BA_ "GenSigInactiveValue" SG_ 859 BP_PTG_LatchSeg_Sta 3;
BA_ "GenSigRoutingTimeoutValue" SG_ 859 BP_PTG_LatchSeg_Sta 3;
BA_ "GenSigSendType" SG_ 859 BP_PTG_LatchSeg_Sta 3;
BA_ "GenSigSendType" SG_ 859 BP_PTG_InsideSW2_Sta 3;
BA_ "GenSigSendType" SG_ 859 BP_PTG_InsideSW1_Sta 3;
BA_ "GenSigSendType" SG_ 859 BP_PTG_HalfSW_Sta 3;
BA_ "GenSigInvalidValue" SG_ 859 BP_PTG_LeftDuty_Sta 127;
BA_ "GenSigStartValue" SG_ 859 BP_PTG_LeftDuty_Sta 127;
BA_ "GenSigRoutingTimeoutValue_String" SG_ 859 BP_PTG_LeftDuty_Sta "0x7F";
BA_ "GenSigInactiveValue" SG_ 859 BP_PTG_LeftDuty_Sta 127;
BA_ "GenSigRoutingTimeoutValue" SG_ 859 BP_PTG_LeftDuty_Sta 127;
BA_ "GenSigSendType" SG_ 859 BP_PTG_FullSW_Sta 3;
BA_ "GenSigInvalidValue" SG_ 859 BP_PTG_RightDuty_Sta 127;
BA_ "GenSigStartValue" SG_ 859 BP_PTG_RightDuty_Sta 127;
BA_ "GenSigRoutingTimeoutValue_String" SG_ 859 BP_PTG_RightDuty_Sta "0x7F";
BA_ "GenSigInactiveValue" SG_ 859 BP_PTG_RightDuty_Sta 127;
BA_ "GenSigRoutingTimeoutValue" SG_ 859 BP_PTG_RightDuty_Sta 127;
BA_ "GenSigSendType" SG_ 859 BP_PTG_NtlSW_Sta 3;
BA_ "GenSigInvalidValue" SG_ 859 BP_PTG_CinchDuty_Sta 127;
BA_ "GenSigStartValue" SG_ 859 BP_PTG_CinchDuty_Sta 127;
BA_ "GenSigRoutingTimeoutValue_String" SG_ 859 BP_PTG_CinchDuty_Sta "0x7F";
BA_ "GenSigInactiveValue" SG_ 859 BP_PTG_CinchDuty_Sta 127;
BA_ "GenSigRoutingTimeoutValue" SG_ 859 BP_PTG_CinchDuty_Sta 127;
BA_ "GenSigSendType" SG_ 859 BP_PTG_StrutThermal_Sta 3;
BA_ "GenSigInvalidValue" SG_ 859 BP_PTG_LeftCur_Sta 32767;
BA_ "GenSigStartValue" SG_ 859 BP_PTG_LeftCur_Sta 32767;
BA_ "GenSigRoutingTimeoutValue_String" SG_ 859 BP_PTG_LeftCur_Sta "0x7FFF";
BA_ "GenSigInactiveValue" SG_ 859 BP_PTG_LeftCur_Sta 32767;
BA_ "GenSigRoutingTimeoutValue" SG_ 859 BP_PTG_LeftCur_Sta 32767;
BA_ "GenSigSendType" SG_ 859 BP_PTG_StrutAntiPinch_Sta 3;
BA_ "GenSigInvalidValue" SG_ 859 BP_PTG_RightCur_Sta 32767;
BA_ "GenSigStartValue" SG_ 859 BP_PTG_RightCur_Sta 32767;
BA_ "GenSigRoutingTimeoutValue_String" SG_ 859 BP_PTG_RightCur_Sta "0x7FFF";
BA_ "GenSigInactiveValue" SG_ 859 BP_PTG_RightCur_Sta 32767;
BA_ "GenSigRoutingTimeoutValue" SG_ 859 BP_PTG_RightCur_Sta 32767;
BA_ "GenSigSendType" SG_ 859 BP_PTG_StrutStall_Sta 3;
BA_ "GenSigInvalidValue" SG_ 859 BP_PTG_CinchCur_Sta 32767;
BA_ "GenSigStartValue" SG_ 859 BP_PTG_CinchCur_Sta 32767;
BA_ "GenSigRoutingTimeoutValue_String" SG_ 859 BP_PTG_CinchCur_Sta "0x7FFF";
BA_ "GenSigInactiveValue" SG_ 859 BP_PTG_CinchCur_Sta 32767;
BA_ "GenSigRoutingTimeoutValue" SG_ 859 BP_PTG_CinchCur_Sta 32767;
BA_ "GenSigSendType" SG_ 859 BP_PTG_AbuseProtection_Sta 3;
BA_ "GenSigInvalidValue" SG_ 859 BP_PTG_ReleaseCur_Sta 32767;
BA_ "GenSigStartValue" SG_ 859 BP_PTG_ReleaseCur_Sta 32767;
BA_ "GenSigRoutingTimeoutValue_String" SG_ 859 BP_PTG_ReleaseCur_Sta "0x7FFF";
BA_ "GenSigInactiveValue" SG_ 859 BP_PTG_ReleaseCur_Sta 32767;
BA_ "GenSigRoutingTimeoutValue" SG_ 859 BP_PTG_ReleaseCur_Sta 32767;
BA_ "GenSigSendType" SG_ 859 BP_PTG_LatchThermal_Sta 3;
BA_ "GenSigInvalidValue" SG_ 859 BP_PTG_LeftHallPosn_Sta 1023;
BA_ "GenSigStartValue" SG_ 859 BP_PTG_LeftHallPosn_Sta 1023;
BA_ "GenSigRoutingTimeoutValue_String" SG_ 859 BP_PTG_LeftHallPosn_Sta "0x3FF";
BA_ "GenSigInactiveValue" SG_ 859 BP_PTG_LeftHallPosn_Sta 1023;
BA_ "GenSigRoutingTimeoutValue" SG_ 859 BP_PTG_LeftHallPosn_Sta 1023;
BA_ "GenSigSendType" SG_ 859 BP_PTG_ErrLeftStrut_Sta 3;
BA_ "GenSigSendType" SG_ 859 BP_PTG_ErrVoltage_Sta 3;
BA_ "GenSigSendType" SG_ 859 BP_PTG_ErrRightStrut_Sta 3;
BA_ "GenSigInvalidValue" SG_ 859 BP_PTG_RightHallPosn_Sta 1023;
BA_ "GenSigStartValue" SG_ 859 BP_PTG_RightHallPosn_Sta 1023;
BA_ "GenSigRoutingTimeoutValue_String" SG_ 859 BP_PTG_RightHallPosn_Sta "0x3FF";
BA_ "GenSigInactiveValue" SG_ 859 BP_PTG_RightHallPosn_Sta 1023;
BA_ "GenSigRoutingTimeoutValue" SG_ 859 BP_PTG_RightHallPosn_Sta 1023;
BA_ "GenSigSendType" SG_ 859 BP_PTG_ErrHall_Sta 3;
BA_ "GenSigSendType" SG_ 859 BP_PTG_ErrLatch_Sta 3;
BA_ "GenSigInvalidValue" SG_ 859 BP_PTG_OpenRatio_Sta 127;
BA_ "GenSigStartValue" SG_ 859 BP_PTG_OpenRatio_Sta 127;
BA_ "GenSigRoutingTimeoutValue_String" SG_ 859 BP_PTG_OpenRatio_Sta "0x7F";
BA_ "GenSigInactiveValue" SG_ 859 BP_PTG_OpenRatio_Sta 127;
BA_ "GenSigRoutingTimeoutValue" SG_ 859 BP_PTG_OpenRatio_Sta 127;
BA_ "GenSigSendType" SG_ 859 BP_PTG_Active_Sta 3;
BA_ "GenSigInvalidValue" SG_ 859 BP_PTG_Sys_Sta 3;
BA_ "GenSigStartValue" SG_ 859 BP_PTG_Sys_Sta 3;
BA_ "GenSigRoutingTimeoutValue_String" SG_ 859 BP_PTG_Sys_Sta "0x3";
BA_ "GenSigRoutingTimeoutValue" SG_ 859 BP_PTG_Sys_Sta 3;
BA_ "GenSigSendType" SG_ 859 BP_PTG_Sys_Sta 3;
BA_ "GenSigRoutingTimeoutValue_String" SG_ 859 BP_PTG_RDIL_Cmd "0x0";
BA_ "GenSigSendType" SG_ 859 BP_PTG_RDIL_Cmd 3;
BA_ "GenSigSendType" SG_ 859 BP_PTG_IsSetHeight_Sta 3;
BA_ "GenSigSendType" SG_ 859 BP_PTG_Exist_Sta 3;
BA_ "GenSigSendType" SG_ 859 BP_PSEAT_Vent_Sta 3;
BA_ "GenSigSendType" SG_ 859 BP_PSEAT_Mode_Sta 3;
BA_ "GenSigSendType" SG_ 859 BP_PSEAT_Error_Sta 3;
BA_ "GenSigSendType" SG_ 859 BP_PSEAT_heater_Sta 3;
BA_ "GenSigInvalidValue" SG_ 1007 BP_SEAT_HeatCurrent_Sta 255;
BA_ "GenSigRoutingTimeoutValue_String" SG_ 1007 BP_SEAT_HeatCurrent_Sta "0xFF";
BA_ "GenSigInactiveValue" SG_ 1007 BP_SEAT_HeatCurrent_Sta 255;
BA_ "GenSigRoutingTimeoutValue" SG_ 1007 BP_SEAT_HeatCurrent_Sta 255;
BA_ "GenSigInvalidValue" SG_ 1007 BP_SEAT_VentCurrent_Sta 255;
BA_ "GenSigRoutingTimeoutValue_String" SG_ 1007 BP_SEAT_VentCurrent_Sta "0xFF";
BA_ "GenSigInactiveValue" SG_ 1007 BP_SEAT_VentCurrent_Sta 255;
BA_ "GenSigRoutingTimeoutValue" SG_ 1007 BP_SEAT_VentCurrent_Sta 255;
BA_ "GenSigInvalidValue" SG_ 1007 BP_Door_RCurrent_Sta 255;
BA_ "GenSigRoutingTimeoutValue_String" SG_ 1007 BP_Door_RCurrent_Sta "0xFF";
BA_ "GenSigInactiveValue" SG_ 1007 BP_Door_RCurrent_Sta 255;
BA_ "GenSigRoutingTimeoutValue" SG_ 1007 BP_Door_RCurrent_Sta 255;
BA_ "GenSigInvalidValue" SG_ 1007 BP_Door_FCurrent_Sta 255;
BA_ "GenSigRoutingTimeoutValue_String" SG_ 1007 BP_Door_FCurrent_Sta "0xFF";
BA_ "GenSigInactiveValue" SG_ 1007 BP_Door_FCurrent_Sta 255;
BA_ "GenSigRoutingTimeoutValue" SG_ 1007 BP_Door_FCurrent_Sta 255;
BA_ "GenSigInvalidValue" SG_ 1007 BP_SEAT_ReclineCurrent_Sta 255;
BA_ "GenSigRoutingTimeoutValue_String" SG_ 1007 BP_SEAT_ReclineCurrent_Sta "0xFF";
BA_ "GenSigInactiveValue" SG_ 1007 BP_SEAT_ReclineCurrent_Sta 255;
BA_ "GenSigRoutingTimeoutValue" SG_ 1007 BP_SEAT_ReclineCurrent_Sta 255;
BA_ "GenSigInvalidValue" SG_ 1007 BP_SEAT_SlideCurrent_Sta 255;
BA_ "GenSigRoutingTimeoutValue_String" SG_ 1007 BP_SEAT_SlideCurrent_Sta "0xFF";
BA_ "GenSigInactiveValue" SG_ 1007 BP_SEAT_SlideCurrent_Sta 255;
BA_ "GenSigRoutingTimeoutValue" SG_ 1007 BP_SEAT_SlideCurrent_Sta 255;
BA_ "GenSigInvalidValue" SG_ 1007 BP_PSEAT_HeaterTemp_Sta 255;
BA_ "GenSigStartValue" SG_ 1007 BP_PSEAT_HeaterTemp_Sta 60;
BA_ "GenSigRoutingTimeoutValue_String" SG_ 1007 BP_PSEAT_HeaterTemp_Sta "0xFF";
BA_ "GenSigInactiveValue" SG_ 1007 BP_PSEAT_HeaterTemp_Sta 255;
BA_ "GenSigRoutingTimeoutValue" SG_ 1007 BP_PSEAT_HeaterTemp_Sta 255;
BA_ "GenSigInvalidValue" SG_ 1007 BP_PTG_ACTRLatchCur_Sta 255;
BA_ "GenSigRoutingTimeoutValue_String" SG_ 1007 BP_PTG_ACTRLatchCur_Sta "0xFF";
BA_ "GenSigInactiveValue" SG_ 1007 BP_PTG_ACTRLatchCur_Sta 255;
BA_ "GenSigRoutingTimeoutValue" SG_ 1007 BP_PTG_ACTRLatchCur_Sta 255;
BA_ "GenSigInvalidValue" SG_ 795 BP_APM_WinFOpened_Sta 127;
BA_ "GenSigStartValue" SG_ 795 BP_APM_WinFOpened_Sta 127;
BA_ "GenSigRoutingTimeoutValue_String" SG_ 795 BP_APM_WinFOpened_Sta "0x7F";
BA_ "GenSigInactiveValue" SG_ 795 BP_APM_WinFOpened_Sta 127;
BA_ "GenSigRoutingTimeoutValue" SG_ 795 BP_APM_WinFOpened_Sta 127;
BA_ "GenSigInvalidValue" SG_ 795 BP_APM_WinROpened_Sta 127;
BA_ "GenSigStartValue" SG_ 795 BP_APM_WinROpened_Sta 127;
BA_ "GenSigRoutingTimeoutValue_String" SG_ 795 BP_APM_WinROpened_Sta "0x7F";
BA_ "GenSigInactiveValue" SG_ 795 BP_APM_WinROpened_Sta 127;
BA_ "GenSigRoutingTimeoutValue" SG_ 795 BP_APM_WinROpened_Sta 127;
BA_ "GenSigRoutingTimeoutValue_String" SG_ 795 BP_Door_FHandleClose_Sta "0x0";
BA_ "GenSigSendType" SG_ 795 BP_Door_FHandleClose_Sta 3;
BA_ "GenSigSendType" SG_ 795 BP_Door_FHandleHalf_Sta 3;
BA_ "GenSigSendType" SG_ 795 BP_SYS_LampPwrSTS_Sta 3;
BA_ "GenSigRoutingTimeoutValue_String" SG_ 795 BP_Door_RHandleClose_Sta "0x0";
BA_ "GenSigSendType" SG_ 795 BP_Door_RHandleClose_Sta 3;
BA_ "GenSigSendType" SG_ 795 BP_Door_RHandleHalf_Sta 3;
BA_ "GenSigSendType" SG_ 795 BP_SEAT_MLVent_Sta 3;
BA_ "GenSigSendType" SG_ 795 BP_SEAT_MRVent_Sta 3;
BA_ "GenSigSendType" SG_ 795 BP_SEAT_LVent_Sta 3;
BA_ "GenSigSendType" SG_ 795 BP_SEAT_RVent_Sta 3;
BA_ "GenSigSendType" SG_ 1286 NM_BodyZone_PS_Node_ID 7;
BA_ "GenSigSendType" SG_ 1286 NM_BodyZone_PS_Rpt_Msg_Req 7;
BA_ "GenSigSendType" SG_ 1286 NM_BodyZone_PS_CSB 7;
BA_ "GenSigSendType" SG_ 1286 NM_BodyZone_PS_Active_WU 7;
BA_ "GenSigSendType" SG_ 1286 NM_BodyZone_PS_PNI 7;
BA_ "GenSigSendType" SG_ 1286 NM_BodyZone_PS_ERROR_State 7;
BA_ "GenSigSendType" SG_ 1542 DiagRespFromBodyZone_PS 3;
BA_ "GenSigSendType" SG_ 1671 DiagPhysReqToBodyZone_DR 3;
BA_ "GenSigSendType" SG_ 1670 DiagPhysReqToBodyZone_PS 3;
BA_ "GenSigStartValue" SG_ 376 ADB_VehLtAngl1Val 510;
BA_ "GenSigStartValue" SG_ 376 ADB_VehRtAngl1Val 510;
BA_ "GenSigStartValue" SG_ 376 ADB_VehLtAngl2Val 510;
BA_ "GenSigStartValue" SG_ 376 ADB_VehRtAngl2Val 510;
BA_ "GenSigStartValue" SG_ 376 ADB_VehLtAngl3Val 510;
BA_ "GenSigStartValue" SG_ 376 ADB_VehRtAngl3Val 510;
BA_ "GenSigStartValue" SG_ 376 ADB_VehLtAngl4Val 510;
BA_ "GenSigStartValue" SG_ 376 ADB_VehRtAngl4Val 510;
BA_ "GenSigStartValue" SG_ 376 ADB_VehLtAngl5Val 510;
BA_ "GenSigStartValue" SG_ 376 ADB_VehRtAngl5Val 510;
BA_ "GenSigStartValue" SG_ 376 ADB_VehLtAngl6Val 510;
BA_ "GenSigStartValue" SG_ 376 ADB_VehRtAngl6Val 510;
BA_ "GenSigStartValue" SG_ 376 ADB_VehLtAngl7Val 510;
BA_ "GenSigStartValue" SG_ 376 ADB_VehRtAngl7Val 510;
BA_ "GenSigStartValue" SG_ 376 ADB_VehLtAngl8Val 510;
BA_ "GenSigStartValue" SG_ 376 ADB_VehRtAngl8Val 510;
BA_ "GenSigStartValue" SG_ 376 ADB_VehLtAngl9Val 510;
BA_ "GenSigStartValue" SG_ 376 ADB_VehRtAngl9Val 510;
BA_ "GenSigStartValue" SG_ 376 ADB_VehLtAngl10Val 510;
BA_ "GenSigStartValue" SG_ 376 ADB_VehRtAngl10Val 510;
BA_ "GenSigSendType" SG_ 1734 DiagPhysReqToLDM_RL 3;
BA_ "GenSigSendType" SG_ 1718 DiagPhysReqToLDM_RR 3;
BA_ "GenSigSendType" SG_ 1702 DiagPhysReqToLDM_FL 3;
BA_ "GenSigSendType" SG_ 1686 DiagPhysReqToLDM_FR 3;
BA_ "GenSigSendType" SG_ 1574 DiagRespFromLDM_FL 3;
BA_ "GenSigSendType" SG_ 1558 DiagRespFromLDM_FR 3;
BA_ "GenSigSendType" SG_ 1606 DiagRespFromLDM_RL 3;
BA_ "GenSigSendType" SG_ 1590 DiagRespFromLDM_RR 3;
BA_ "GenSigInvalidValue" SG_ 881 PTG_Open_Ratio 127;
BA_ "GenSigStartValue" SG_ 881 PTG_Open_Ratio 127;
BA_ "GenSigRoutingTimeoutValue_String" SG_ 881 PTG_Open_Ratio "0x7F";
BA_ "GenSigInactiveValue" SG_ 881 PTG_Open_Ratio 127;
BA_ "GenSigRoutingTimeoutValue" SG_ 881 PTG_Open_Ratio 127;
BA_ "DataCenterDataType" SG_ 881 PTG_Active_Sta "Varchar(20)";
BA_ "GenSigInvalidValue" SG_ 881 PTG_Warning_Sta 7;
BA_ "GenSigStartValue" SG_ 881 PTG_Warning_Sta 7;
BA_ "GenSigRoutingTimeoutValue_String" SG_ 881 PTG_Warning_Sta "0x7";
BA_ "GenSigInactiveValue" SG_ 881 PTG_Warning_Sta 7;
BA_ "GenSigRoutingTimeoutValue" SG_ 881 PTG_Warning_Sta 7;
BA_ "GenSigInvalidValue" SG_ 881 PTG_RDIL_Sta 3;
BA_ "GenSigStartValue" SG_ 881 PTG_RDIL_Sta 3;
BA_ "GenSigRoutingTimeoutValue_String" SG_ 881 PTG_RDIL_Sta "0x3";
BA_ "GenSigInactiveValue" SG_ 881 PTG_RDIL_Sta 3;
BA_ "GenSigRoutingTimeoutValue" SG_ 881 PTG_RDIL_Sta 3;
BA_ "GenSigInvalidValue" SG_ 881 PTG_Sys_Sta 3;
BA_ "GenSigStartValue" SG_ 881 PTG_Sys_Sta 3;
BA_ "GenSigRoutingTimeoutValue_String" SG_ 881 PTG_Sys_Sta "0x3";
BA_ "GenSigInactiveValue" SG_ 881 PTG_Sys_Sta 3;
BA_ "GenSigRoutingTimeoutValue" SG_ 881 PTG_Sys_Sta 3;
BA_ "DataCenterDataType" SG_ 881 PTG_Sys_Sta "Varchar(20)";
BA_ "DataCenterDataType" SG_ 881 PTG_Exist "Varchar(10)";
BA_ "GenSigSendType" SG_ 1684 DiagPhysReqToDSEAT 3;
BA_ "GenSigSendType" SG_ 1700 DiagPhysReqToPSEAT 3;
BA_ "GenSigSendType" SG_ 1716 DiagPhysReqToPTG 3;
BA_ "GenSigSendType" SG_ 1556 DiagRespFromDSEAT 3;
BA_ "GenSigSendType" SG_ 1572 DiagRespFromPSEAT 3;
BA_ "GenSigSendType" SG_ 1588 DiagRespFromPTG 3;
BA_ "GenSigInvalidValue" SG_ 854 DSEAT_Slid_Pos 255;
BA_ "GenSigStartValue" SG_ 854 DSEAT_Slid_Pos 255;
BA_ "GenSigRoutingTimeoutValue_String" SG_ 854 DSEAT_Slid_Pos "0xFF";
BA_ "GenSigInactiveValue" SG_ 854 DSEAT_Slid_Pos 255;
BA_ "GenSigRoutingTimeoutValue" SG_ 854 DSEAT_Slid_Pos 255;
BA_ "GenSigInvalidValue" SG_ 854 DSEAT_RL_Pos 255;
BA_ "GenSigStartValue" SG_ 854 DSEAT_RL_Pos 255;
BA_ "GenSigRoutingTimeoutValue_String" SG_ 854 DSEAT_RL_Pos "0xFF";
BA_ "GenSigInactiveValue" SG_ 854 DSEAT_RL_Pos 255;
BA_ "GenSigRoutingTimeoutValue" SG_ 854 DSEAT_RL_Pos 255;
BA_ "GenSigInvalidValue" SG_ 854 DSEAT_Rec_Pos 255;
BA_ "GenSigStartValue" SG_ 854 DSEAT_Rec_Pos 255;
BA_ "GenSigRoutingTimeoutValue_String" SG_ 854 DSEAT_Rec_Pos "0xFF";
BA_ "GenSigInactiveValue" SG_ 854 DSEAT_Rec_Pos 255;
BA_ "GenSigRoutingTimeoutValue" SG_ 854 DSEAT_Rec_Pos 255;
BA_ "GenSigInvalidValue" SG_ 854 DSEAT_FL_Pos 255;
BA_ "GenSigStartValue" SG_ 854 DSEAT_FL_Pos 255;
BA_ "GenSigRoutingTimeoutValue_String" SG_ 854 DSEAT_FL_Pos "0xFF";
BA_ "GenSigInactiveValue" SG_ 854 DSEAT_FL_Pos 255;
BA_ "GenSigRoutingTimeoutValue" SG_ 854 DSEAT_FL_Pos 255;
BA_ "GenSigSendType" SG_ 854 DSEAT_heater_sta 3;
BA_ "GenSigSendType" SG_ 854 DSEAT_Mode 3;
BA_ "GenSigSendType" SG_ 854 DSEAT_Vent_Sta 3;
BA_ "GenSigSendType" SG_ 854 PSEAT_heater_sta 3;
BA_ "GenSigSendType" SG_ 854 PSEAT_Mode 3;
BA_ "GenSigSendType" SG_ 854 PSEAT_Vent_Sta 3;
BA_ "GenSigSendType" SG_ 854 DSEAT_AntiAct_Sta 3;
BA_ "GenSigSendType" SG_ 854 DSEAT_Anti_Sta 3;
BA_ "GenSigSendType" SG_ 854 DSEAT_EntryAct_Sta 3;
BA_ "GenSigSendType" SG_ 854 DSEAT_EntryFun_Sta 3;
BA_ "GenSigSendType" SG_ 854 DSEAT_Error_Sta 3;
BA_ "DataCenterDataType" SG_ 854 DSEAT_Error_Sta "Varchar(30)";
BA_ "GenSigSendType" SG_ 854 PSEAT_Error_Sta 3;
BA_ "GenSigInvalidValue" SG_ 630 DCPortNeg_Temp 255;
BA_ "GenSigStartValue" SG_ 630 DCPortNeg_Temp 255;
BA_ "GenSigInvalidValue" SG_ 630 DCPortPos_Temp 255;
BA_ "GenSigStartValue" SG_ 630 DCPortPos_Temp 255;
BA_ "GenSigInvalidValue" SG_ 630 OBCACCSLimit 255;
BA_ "GenSigStartValue" SG_ 630 OBCACCSLimit 255;
BA_ "GenSigRoutingTimeoutValue_String" SG_ 630 OBCACCSLimit "0xFF";
BA_ "GenSigInactiveValue" SG_ 630 OBCACCSLimit 255;
BA_ "GenSigRoutingTimeoutValue" SG_ 630 OBCACCSLimit 255;
BA_ "GenSigSendType" SG_ 630 OBCACCSLimit 3;
BA_ "GenSigStartValue" SG_ 630 OBCDCCurLm 255;
BA_ "GenSigSendType" SG_ 630 ReChargerStaFromEvcc 3;
BA_ "DataCenterDataType" SG_ 630 ReChargerStaFromEvcc "Varchar(10)";
BA_ "GenSigSendType" SG_ 630 OBCEna 3;
BA_ "DataCenterDataType" SG_ 630 LVBattDet12V "Decimal";
BA_ "GenSigInvalidValue" SG_ 1006 BD_SEAT_VentCurrent_Sta 255;
BA_ "GenSigRoutingTimeoutValue_String" SG_ 1006 BD_SEAT_VentCurrent_Sta "0xFF";
BA_ "GenSigInactiveValue" SG_ 1006 BD_SEAT_VentCurrent_Sta 255;
BA_ "GenSigRoutingTimeoutValue" SG_ 1006 BD_SEAT_VentCurrent_Sta 255;
BA_ "GenSigInvalidValue" SG_ 1006 BD_SEAT_HeatCurrent_Sta 255;
BA_ "GenSigRoutingTimeoutValue_String" SG_ 1006 BD_SEAT_HeatCurrent_Sta "0xFF";
BA_ "GenSigInactiveValue" SG_ 1006 BD_SEAT_HeatCurrent_Sta 255;
BA_ "GenSigRoutingTimeoutValue" SG_ 1006 BD_SEAT_HeatCurrent_Sta 255;
BA_ "GenSigInvalidValue" SG_ 1006 BD_SEAT_FrontLiftCurrent_Sta 255;
BA_ "GenSigRoutingTimeoutValue_String" SG_ 1006 BD_SEAT_FrontLiftCurrent_Sta "0xFF";
BA_ "GenSigInactiveValue" SG_ 1006 BD_SEAT_FrontLiftCurrent_Sta 255;
BA_ "GenSigRoutingTimeoutValue" SG_ 1006 BD_SEAT_FrontLiftCurrent_Sta 255;
BA_ "GenSigInvalidValue" SG_ 1006 BD_SEAT_RearLiftCurrent_Sta 255;
BA_ "GenSigRoutingTimeoutValue_String" SG_ 1006 BD_SEAT_RearLiftCurrent_Sta "0xFF";
BA_ "GenSigInactiveValue" SG_ 1006 BD_SEAT_RearLiftCurrent_Sta 255;
BA_ "GenSigRoutingTimeoutValue" SG_ 1006 BD_SEAT_RearLiftCurrent_Sta 255;
BA_ "GenSigInvalidValue" SG_ 1006 BD_SEAT_ReclineCurrent_Sta 255;
BA_ "GenSigRoutingTimeoutValue_String" SG_ 1006 BD_SEAT_ReclineCurrent_Sta "0xFF";
BA_ "GenSigInactiveValue" SG_ 1006 BD_SEAT_ReclineCurrent_Sta 255;
BA_ "GenSigRoutingTimeoutValue" SG_ 1006 BD_SEAT_ReclineCurrent_Sta 255;
BA_ "GenSigInvalidValue" SG_ 1006 BD_SEAT_SlideCurrent_Sta 255;
BA_ "GenSigRoutingTimeoutValue_String" SG_ 1006 BD_SEAT_SlideCurrent_Sta "0xFF";
BA_ "GenSigInactiveValue" SG_ 1006 BD_SEAT_SlideCurrent_Sta 255;
BA_ "GenSigRoutingTimeoutValue" SG_ 1006 BD_SEAT_SlideCurrent_Sta 255;
BA_ "GenSigInvalidValue" SG_ 1006 BD_Door_RCurrent_Sta 255;
BA_ "GenSigRoutingTimeoutValue_String" SG_ 1006 BD_Door_RCurrent_Sta "0xFF";
BA_ "GenSigInactiveValue" SG_ 1006 BD_Door_RCurrent_Sta 255;
BA_ "GenSigRoutingTimeoutValue" SG_ 1006 BD_Door_RCurrent_Sta 255;
BA_ "GenSigInvalidValue" SG_ 1006 BD_Door_FCurrent_Sta 255;
BA_ "GenSigRoutingTimeoutValue_String" SG_ 1006 BD_Door_FCurrent_Sta "0xFF";
BA_ "GenSigInactiveValue" SG_ 1006 BD_Door_FCurrent_Sta 255;
BA_ "GenSigRoutingTimeoutValue" SG_ 1006 BD_Door_FCurrent_Sta 255;
BA_ "GenSigInvalidValue" SG_ 1006 BD_DSEAT_HeaterTemp_Sta 255;
BA_ "GenSigStartValue" SG_ 1006 BD_DSEAT_HeaterTemp_Sta 60;
BA_ "GenSigRoutingTimeoutValue_String" SG_ 1006 BD_DSEAT_HeaterTemp_Sta "0xFF";
BA_ "GenSigInactiveValue" SG_ 1006 BD_DSEAT_HeaterTemp_Sta 255;
BA_ "GenSigRoutingTimeoutValue" SG_ 1006 BD_DSEAT_HeaterTemp_Sta 255;
BA_ "GenSigSendType" SG_ 928 FDC_VCU_ReqHWReset_Cmd 3;
BA_ "GenSigSendType" SG_ 928 FD4_CE100_2_CS 3;
BA_ "GenSigSendType" SG_ 928 FD4_CE100_2_RC 3;
BA_ "GenSigSendType" SG_ 1345 NM_ZONE_ML_Node_ID 7;
BA_ "GenSigSendType" SG_ 1345 NM_ZONE_ML_ERROR_State 7;
BA_ "GenSigSendType" SG_ 1345 NM_ZONE_ML_Active_WU 7;
BA_ "GenSigSendType" SG_ 1345 NM_ZONE_ML_CSB 7;
BA_ "GenSigSendType" SG_ 1345 NM_ZONE_ML_PNI 7;
BA_ "GenSigSendType" SG_ 1345 NM_ZONE_ML_Rpt_Msg_Req 7;
BA_ "GenSigSendType" SG_ 1346 NM_ZONE_MR_Node_ID 7;
BA_ "GenSigSendType" SG_ 1346 NM_ZONE_MR_ERROR_State 7;
BA_ "GenSigSendType" SG_ 1346 NM_ZONE_MR_Active_WU 7;
BA_ "GenSigSendType" SG_ 1346 NM_ZONE_MR_CSB 7;
BA_ "GenSigSendType" SG_ 1346 NM_ZONE_MR_PNI 7;
BA_ "GenSigSendType" SG_ 1346 NM_ZONE_MR_Rpt_Msg_Req 7;
BA_ "GenSigSendType" SG_ 1729 DiagPhysReqToZONE_ML 3;
BA_ "GenSigSendType" SG_ 1730 DiagPhysReqToZONE_MR 3;
BA_ "GenSigSendType" SG_ 1601 DiagRespFromZONE_ML 3;
BA_ "GenSigSendType" SG_ 1602 DiagRespFromZONE_MR 3;
BA_ "GenSigSendType" SG_ 597 IVI_MLSEATvent_Cmd 3;
BA_ "GenSigSendType" SG_ 597 IVI_MRSEATvent_Cmd 3;
BA_ "GenSigSendType" SG_ 597 IVI_MLFootLift_Cmd 3;
BA_ "GenSigSendType" SG_ 597 IVI_MLRecliner_Cmd 3;
BA_ "GenSigSendType" SG_ 597 IVI_MLSeatLift_Cmd 3;
BA_ "GenSigSendType" SG_ 597 IVI_MLSlider_Cmd 3;
BA_ "GenSigSendType" SG_ 597 IVI_MRFootLift_Cmd 3;
BA_ "GenSigSendType" SG_ 597 IVI_MRRecliner_Cmd 3;
BA_ "GenSigSendType" SG_ 597 IVI_MRSeatLift_Cmd 3;
BA_ "GenSigSendType" SG_ 597 IVI_MRSlider_Cmd 3;
BA_ "GenSigSendType" SG_ 597 IVI_MLFMost_Cmd 3;
BA_ "GenSigSendType" SG_ 597 IVI_MLNapMode_Cmd 3;
BA_ "GenSigSendType" SG_ 597 IVI_MLRestore_Cmd 3;
BA_ "GenSigSendType" SG_ 597 IVI_MLSldRestore_Cmd 3;
BA_ "GenSigSendType" SG_ 597 IVI_MLZeroGravity_Cmd 3;
BA_ "GenSigSendType" SG_ 597 IVI_MRFMost_Cmd 3;
BA_ "GenSigSendType" SG_ 597 IVI_MRNapMode_Cmd 3;
BA_ "GenSigSendType" SG_ 597 IVI_MRRestore_Cmd 3;
BA_ "GenSigSendType" SG_ 597 IVI_MRSldRestore_Cmd 3;
BA_ "GenSigSendType" SG_ 597 IVI_MRZeroGravity_Cmd 3;
BA_ "GenSigSendType" SG_ 597 IVI_LSEATvent_Cmd 3;
BA_ "GenSigSendType" SG_ 597 IVI_RSEATvent_Cmd 3;
BA_ "GenSigRoutingTimeoutValue_String" SG_ 953 ZFR_SYS_V2LRelayCurr_Sta "0x0";
BA_ "GenSigRoutingTimeoutValue_String" SG_ 953 ZFR_SYS_TrailerBPlusCurr_Sta "0x0";
BA_ "GenSigRoutingTimeoutValue_String" SG_ 953 ZFR_SYS_Trailer4Curr_Sta "0x0";
BA_ "GenSigRoutingTimeoutValue_String" SG_ 953 ZFR_SYS_Trailer3Curr_Sta "0x0";
BA_ "GenSigRoutingTimeoutValue_String" SG_ 953 ZFR_SYS_Trailer2Curr_Sta "0x0";
BA_ "GenSigRoutingTimeoutValue_String" SG_ 953 ZFR_SYS_Trailer1Curr_Sta "0x0";
BA_ "GenSigRoutingTimeoutValue_String" SG_ 953 ZFR_SYS_SOTXVCurr_Sta "0x0";
BA_ "GenSigRoutingTimeoutValue_String" SG_ 953 ZFR_SYS_SideMarkerCurr_Sta "0x0";
BA_ "GenSigRoutingTimeoutValue_String" SG_ 953 ZFR_SYS_Ref5VCurr_Sta "0x0";
BA_ "GenSigRoutingTimeoutValue_String" SG_ 953 ZFR_SYS_RearWasherCurr_Sta "0x0";
BA_ "GenSigRoutingTimeoutValue_String" SG_ 953 ZFR_SYS_RearDefogCurr_Sta "0x0";
BA_ "GenSigRoutingTimeoutValue_String" SG_ 953 ZFR_SYS_RadFanCurr_Sta "0x0";
BA_ "DataCenterDataType" SG_ 953 ZFR_SYS_RadFanCurr_Sta "Varchar(10)";
BA_ "GenSigRoutingTimeoutValue_String" SG_ 953 ZFR_SYS_LowBeamCurr_Sta "0x0";
BA_ "GenSigRoutingTimeoutValue_String" SG_ 953 ZFR_SYS_HornCurr_Sta "0x0";
BA_ "GenSigRoutingTimeoutValue_String" SG_ 953 ZFR_SYS_HighBeamCurr_Sta "0x0";
BA_ "GenSigRoutingTimeoutValue_String" SG_ 953 ZFR_SYS_FWiperLCurr_Sta "0x0";
BA_ "GenSigRoutingTimeoutValue_String" SG_ 953 ZFR_SYS_FWiperHCurr_Sta "0x0";
BA_ "GenSigRoutingTimeoutValue_String" SG_ 953 ZFR_SYS_FrontWasherCurr_Sta "0x0";
BA_ "GenSigRoutingTimeoutValue_String" SG_ 953 ZFR_SYS_FrontPosLampCurr_Sta "0x0";
BA_ "GenSigRoutingTimeoutValue_String" SG_ 953 ZFR_SYS_FrontFogLampCurr_Sta "0x0";
BA_ "GenSigRoutingTimeoutValue_String" SG_ 953 ZFR_SYS_EPBRelayCurr_Sta "0x0";
BA_ "GenSigRoutingTimeoutValue_String" SG_ 953 ZFR_SYS_DRLRCurr_Sta "0x0";
BA_ "GenSigRoutingTimeoutValue_String" SG_ 953 ZFR_SYS_DRLLCurr_Sta "0x0";
BA_ "GenSigRoutingTimeoutValue_String" SG_ 953 ZFR_SYS_ChgInletLockCurr_Sta "0x0";
BA_ "GenSigRoutingTimeoutValue_String" SG_ 953 ZFR_SYS_ChgDoorLockCurr_Sta "0x0";
BA_ "GenSigInvalidValue" SG_ 953 ZFR_SYS_BoardBatVolt_Sta 4095;
BA_ "GenSigRoutingTimeoutValue_String" SG_ 953 ZFR_SYS_BoardBatVolt_Sta "0xFFF";
BA_ "GenSigRoutingTimeoutValue" SG_ 953 ZFR_SYS_BoardBatVolt_Sta 4095;
BA_ "GenSigInvalidValue" SG_ 953 ZFR_SYS_U155Temp_Sta 4095;
BA_ "GenSigStartValue" SG_ 953 ZFR_SYS_U155Temp_Sta 400;
BA_ "GenSigRoutingTimeoutValue_String" SG_ 953 ZFR_SYS_U155Temp_Sta "0xFFF";
BA_ "GenSigInactiveValue" SG_ 953 ZFR_SYS_U155Temp_Sta 4095;
BA_ "GenSigRoutingTimeoutValue" SG_ 953 ZFR_SYS_U155Temp_Sta 4095;
BA_ "GenSigInvalidValue" SG_ 953 ZFR_SYS_U156Temp_Sta 4095;
BA_ "GenSigStartValue" SG_ 953 ZFR_SYS_U156Temp_Sta 400;
BA_ "GenSigRoutingTimeoutValue_String" SG_ 953 ZFR_SYS_U156Temp_Sta "0xFFF";
BA_ "GenSigInactiveValue" SG_ 953 ZFR_SYS_U156Temp_Sta 4095;
BA_ "GenSigRoutingTimeoutValue" SG_ 953 ZFR_SYS_U156Temp_Sta 4095;
BA_ "GenSigInvalidValue" SG_ 953 ZFR_SYS_U5Temp_Sta 4095;
BA_ "GenSigStartValue" SG_ 953 ZFR_SYS_U5Temp_Sta 400;
BA_ "GenSigRoutingTimeoutValue_String" SG_ 953 ZFR_SYS_U5Temp_Sta "0xFFF";
BA_ "GenSigInactiveValue" SG_ 953 ZFR_SYS_U5Temp_Sta 4095;
BA_ "GenSigRoutingTimeoutValue" SG_ 953 ZFR_SYS_U5Temp_Sta 4095;
BA_ "GenSigRoutingTimeoutValue_String" SG_ 949 ZDR_SYS_VentPwrCurr_Sta "0x0";
BA_ "GenSigRoutingTimeoutValue_String" SG_ 949 ZDR_SYS_TrunkReleaseCurr_Sta "0x0";
BA_ "GenSigRoutingTimeoutValue_String" SG_ 949 ZDR_SYS_RoomLampPwrCurr_Sta "0x0";
BA_ "GenSigRoutingTimeoutValue_String" SG_ 949 ZDR_SYS_ReverseLampCurr_Sta "0x0";
BA_ "GenSigRoutingTimeoutValue_String" SG_ 949 ZDR_SYS_Ref5VCurr_Sta "0x0";
BA_ "GenSigRoutingTimeoutValue_String" SG_ 949 ZDR_SYS_RearWiperCurr_Sta "0x0";
BA_ "GenSigRoutingTimeoutValue_String" SG_ 949 ZDR_SYS_RearPosLampCurr_Sta "0x0";
BA_ "GenSigRoutingTimeoutValue_String" SG_ 949 ZDR_SYS_RearFogLampCurr_Sta "0x0";
BA_ "GenSigRoutingTimeoutValue_String" SG_ 949 ZDR_SYS_OTDoorUnlockCurr_Sta "0x0";
BA_ "GenSigRoutingTimeoutValue_String" SG_ 949 ZDR_SYS_OMirrorDefogCurr_Sta "0x0";
BA_ "GenSigRoutingTimeoutValue_String" SG_ 949 ZDR_SYS_ModeDriveCurr_Sta "0x0";
BA_ "GenSigRoutingTimeoutValue_String" SG_ 949 ZDR_SYS_MirrorFoldCurr_Sta "0x0";
BA_ "GenSigRoutingTimeoutValue_String" SG_ 949 ZDR_SYS_LINStepPwrCurr_Sta "0x0";
BA_ "GenSigRoutingTimeoutValue_String" SG_ 949 ZDR_SYS_IntakeDriveCurr_Sta "0x0";
BA_ "GenSigRoutingTimeoutValue_String" SG_ 949 ZDR_SYS_HSWTempPwrCurr_Sta "0x0";
BA_ "GenSigRoutingTimeoutValue_String" SG_ 949 ZDR_SYS_HSWHeaterPwrCurr_Sta "0x0";
BA_ "GenSigRoutingTimeoutValue_String" SG_ 949 ZDR_SYS_HSWHeaterIndCurr_Sta "0x0";
BA_ "GenSigRoutingTimeoutValue_String" SG_ 949 ZDR_SYS_HazardLEDCurr_Sta "0x0";
BA_ "GenSigRoutingTimeoutValue_String" SG_ 949 ZDR_SYS_FragrancePwrCurr_Sta "0x0";
BA_ "GenSigRoutingTimeoutValue_String" SG_ 949 ZDR_SYS_DRDoorUnlockCurr_Sta "0x0";
BA_ "GenSigRoutingTimeoutValue_String" SG_ 949 ZDR_SYS_DMSPwrCurr_Sta "0x0";
BA_ "GenSigRoutingTimeoutValue_String" SG_ 949 ZDR_SYS_ColumnSWCurr_Sta "0x0";
BA_ "GenSigRoutingTimeoutValue_String" SG_ 949 ZDR_SYS_CHMSLCurr_Sta "0x0";
BA_ "GenSigRoutingTimeoutValue_String" SG_ 949 ZDR_SYS_BrakeLampLRCurr_Sta "0x0";
BA_ "GenSigRoutingTimeoutValue_String" SG_ 949 ZDR_SYS_AtmosLampCurr_Sta "0x0";
BA_ "GenSigRoutingTimeoutValue_String" SG_ 949 ZDR_SYS_AntiGlareCurr_Sta "0x0";
BA_ "GenSigRoutingTimeoutValue_String" SG_ 949 ZDR_SYS_AllDoorLockCurr_Sta "0x0";
BA_ "GenSigRoutingTimeoutValue_String" SG_ 949 ZDR_SYS_CTDINDCurr_Sta "0x0";
BA_ "GenSigRoutingTimeoutValue_String" SG_ 949 ZDR_SYS_BSDLCurr_Sta "0x0";
BA_ "GenSigRoutingTimeoutValue_String" SG_ 949 ZDR_SYS_BSDRCurr_Sta "0x0";
BA_ "GenSigRoutingTimeoutValue_String" SG_ 949 ZDR_SYS_DrPwrStdbyA2Curr_Sta "0x0";
BA_ "GenSigRoutingTimeoutValue_String" SG_ 949 ZDR_SYS_AuBoxPwrN4Curr_Sta "0x0";
BA_ "GenSigRoutingTimeoutValue_String" SG_ 949 ZDR_SYS_AuBoxPwrN3Curr_Sta "0x0";
BA_ "GenSigInvalidValue" SG_ 949 ZDR_SYS_BoardBatVolt_Sta 4095;
BA_ "GenSigRoutingTimeoutValue_String" SG_ 949 ZDR_SYS_BoardBatVolt_Sta "0xFFF";
BA_ "GenSigRoutingTimeoutValue" SG_ 949 ZDR_SYS_BoardBatVolt_Sta 4095;
BA_ "GenSigInvalidValue" SG_ 949 ZDR_SYS_U155Temp_Sta 4095;
BA_ "GenSigStartValue" SG_ 949 ZDR_SYS_U155Temp_Sta 400;
BA_ "GenSigRoutingTimeoutValue_String" SG_ 949 ZDR_SYS_U155Temp_Sta "0xFFF";
BA_ "GenSigInactiveValue" SG_ 949 ZDR_SYS_U155Temp_Sta 4095;
BA_ "GenSigRoutingTimeoutValue" SG_ 949 ZDR_SYS_U155Temp_Sta 4095;
BA_ "GenSigInvalidValue" SG_ 949 ZDR_SYS_U156Temp_Sta 4095;
BA_ "GenSigStartValue" SG_ 949 ZDR_SYS_U156Temp_Sta 400;
BA_ "GenSigRoutingTimeoutValue_String" SG_ 949 ZDR_SYS_U156Temp_Sta "0xFFF";
BA_ "GenSigInactiveValue" SG_ 949 ZDR_SYS_U156Temp_Sta 4095;
BA_ "GenSigRoutingTimeoutValue" SG_ 949 ZDR_SYS_U156Temp_Sta 4095;
BA_ "GenSigInvalidValue" SG_ 949 ZDR_SYS_U5Temp_Sta 4095;
BA_ "GenSigStartValue" SG_ 949 ZDR_SYS_U5Temp_Sta 400;
BA_ "GenSigRoutingTimeoutValue_String" SG_ 949 ZDR_SYS_U5Temp_Sta "0xFFF";
BA_ "GenSigInactiveValue" SG_ 949 ZDR_SYS_U5Temp_Sta 4095;
BA_ "GenSigRoutingTimeoutValue" SG_ 949 ZDR_SYS_U5Temp_Sta 4095;
BA_ "GenSigSendType" SG_ 2015 DiagFuncReqOBD 3;
BA_ "GenSigSendType" SG_ 1703 DiagPhysReqToPSD_L 3;
BA_ "GenSigSendType" SG_ 1704 DiagPhysReqToPSD_R 3;
BA_ "GenSigSendType" SG_ 1575 DiagRespFromPSD_L 3;
BA_ "GenSigSendType" SG_ 1576 DiagRespFromPSD_R 3;
VAL_ 778 EAC_Temp 255 "Invalid" 1 "Fault" 0 "Normal";
VAL_ 778 EAC_DrvVoltFalt 1 "Fault" 0 "Normal";
VAL_ 778 EAC_MotorLackFalt 1 "Fault" 0 "Normal";
VAL_ 778 EAC_OvLoadFalt 1 "Fault" 0 "Normal";
VAL_ 778 EAC_TempSnsrFalt 1 "Fault" 0 "Normal";
VAL_ 778 COMP_ComLost 1 "Fault" 0 "Normal";
VAL_ 778 COMP_IPM_HWFLt 1 "Fault" 0 "Normal";
VAL_ 778 COMP_IPM_TempOverFlt 1 "Fault" 0 "Normal";
VAL_ 778 COMP_CurOverProtect 1 "Fault" 0 "Normal";
VAL_ 778 COMP_VoltOverErr 1 "Fault" 0 "Normal";
VAL_ 778 COMP_VoltLessErr 1 "Fault" 0 "Normal";
VAL_ 778 COMP_CtrlCircFlt 1 "Fault" 0 "Normal";
VAL_ 778 COMP_Sta 3 "Limit state" 2 "Fault" 1 "Working" 0 "Standby";
VAL_ 778 COMP_Init 1 "Init Complete" 0 "Initializing";
VAL_ 778 COMP_SpdVaild 1 "invaild" 0 "valid";
VAL_ 778 COMP_CurVaild 1 "invaild" 0 "valid";
VAL_ 778 COMP_VoltVaild 1 "invaild" 0 "valid";
VAL_ 778 COMP_StatorSpd 16383 "Invalid";
VAL_ 778 COMP_ActualPwr 8191 "Invalid";
VAL_ 778 PTC1_PowerConsumption 255 "Invalid";
VAL_ 778 PTC1_IGBTTem 255 "Invalid";
VAL_ 778 PTC1_ClntTempOtlt 255 "Invalid";
VAL_ 778 PTC1_ClntTempInlt 255 "Invalid";
VAL_ 778 PTC1_ActuHiCrnt 255 "Invalid";
VAL_ 778 PTC1_WrkngSts 3 "Operation" 2 "Sleep Fault" 1 "Wait Fault" 0 "Off";
VAL_ 778 PTC1_ClntInltOverTemProtn 1 "True" 0 "False";
VAL_ 778 PTC1_ClntInltTemSnsrFlt 1 "True" 0 "False";
VAL_ 778 PTC1_ClntOtltOverTemProtn 1 "True" 0 "False";
VAL_ 778 PTC1_ClntOtltTemSnsrFlt 1 "True" 0 "False";
VAL_ 778 PTC1_CommError 1 "True" 0 "False";
VAL_ 778 PTC1_CoreOrIGBTOpenErr 1 "True" 0 "False";
VAL_ 778 PTC1_HiCrntSnsrFlt 1 "True" 0 "False";
VAL_ 778 PTC1_HVDisconnectProtn 1 "True" 0 "False";
VAL_ 778 PTC1_HVOverCrntProtn 1 "True" 0 "False";
VAL_ 778 PTC1_IGBTOverTemProtn 1 "True" 0 "False";
VAL_ 778 PTC1_IGBTShrtErr 1 "True" 0 "False";
VAL_ 778 PTC1_IGBTTemSnsrFlt 1 "True" 0 "False";
VAL_ 778 PTC1_MmryFlt 1 "True" 0 "False";
VAL_ 778 PTC1_PCBOverTempProtn 1 "True" 0 "False";
VAL_ 778 PTC1_PCBTempSnsrFlt 1 "True" 0 "False";
VAL_ 778 PTC1_VbatVtgProtn 1 "True" 0 "False";
VAL_ 778 PTC1_VbatVtgSnsrFlt 1 "True" 0 "False";
VAL_ 778 PTC1_VbatVtgUnstable 1 "True" 0 "False";
VAL_ 1284 NM_ZONE_FR_PNI 1 "NM PDU contains Partial Network request information" 0 "NM PDU contains no Partial Network request information";
VAL_ 1284 NM_ZONE_FR_Active_WU 1 "Node has woken up the network (active Wakeup)" 0 "Node has not woken up the network (passive wakeup)";
VAL_ 1284 NM_ZONE_FR_CSB 1 "Start of synchronized shutdown is requested by main coordinator" 0 "Start of synchronized shutdown is not requested by main coordinator";
VAL_ 1284 NM_ZONE_FR_Rpt_Msg_Req 1 "Repeat Message State requested" 0 "Repeat Message State not requested";
VAL_ 1284 NM_ZONE_FR_ERROR_State 8 "BUS OFF_L2" 4 "BUS OFF_L1" 2 "ERROR PASSIVE" 1 "ERROR ACTIVE" 0 "Inactive";
VAL_ 1285 NM_DKC_PNI 1 "NM PDU contains Partial Network request information" 0 "NM PDU contains no Partial Network request information";
VAL_ 1285 NM_DKC_Active_WU 1 "Node has woken up the network (active Wakeup)" 0 "Node has not woken up the network (passive wakeup)";
VAL_ 1285 NM_DKC_CSB 1 "Start of synchronized shutdown is requested by main coordinator" 0 "Start of synchronized shutdown is not requested by main coordinator";
VAL_ 1285 NM_DKC_Rpt_Msg_Req 1 "Repeat Message State requested" 0 "Repeat Message State not requested";
VAL_ 1285 NM_DKC_ERROR_State 8 "BUS OFF_L2" 4 "BUS OFF_L1" 2 "ERROR PASSIVE" 1 "ERROR ACTIVE" 0 "Inactive";
VAL_ 1344 NM_ZONE_DR_PNI 1 "NM PDU contains Partial Network request information" 0 "NM PDU contains no Partial Network request information";
VAL_ 1344 NM_ZONE_DR_Active_WU 1 "Node has woken up the network (active Wakeup)" 0 "Node has not woken up the network (passive wakeup)";
VAL_ 1344 NM_ZONE_DR_CSB 1 "Start of synchronized shutdown is requested by main coordinator" 0 "Start of synchronized shutdown is not requested by main coordinator";
VAL_ 1344 NM_ZONE_DR_Rpt_Msg_Req 1 "Repeat Message State requested" 0 "Repeat Message State not requested";
VAL_ 1344 NM_ZONE_DR_ERROR_State 8 "BUS OFF_L2" 4 "BUS OFF_L1" 2 "ERROR PASSIVE" 1 "ERROR ACTIVE" 0 "Inactive";
VAL_ 794 BD_APM_WinFOpened_Sta 127 "Invalid" 102 "~0x7E undefined";
VAL_ 794 BD_APM_WinROpened_Sta 127 "Invalid" 102 "~0x7E undefined";
VAL_ 794 BD_Door_FHandleClose_Sta 1 "Close" 0 "Not Close";
VAL_ 794 BD_Door_FHandleHalf_Sta 1 "Open" 0 "Not Open";
VAL_ 794 BD_Door_RHandleClose_Sta 1 "Close" 0 "Not Close";
VAL_ 794 BD_Door_RHandleHalf_Sta 1 "Open" 0 "Not Open";
VAL_ 858 BD_DSEAT_SlidPos_Sta 1023 "Invaild" 524 "~0x3FE Undefined";
VAL_ 858 BD_DSEAT_RecPos_Sta 2047 "Invaild" 1119 "~0x7FE Undefined";
VAL_ 858 BD_DSEAT_FLPos_Sta 511 "Invaild" 296 "~0x1FE Undefined";
VAL_ 858 BD_DSEAT_RLPos_Sta 511 "Invaild" 392 "~0x1FE Undefined";
VAL_ 858 BD_DSEAT_Mode_Sta 7 "manual & heater & ventilate" 6 "manual & ventilate" 5 "manual & heater" 4 "power & heater & ventilate" 3 "power & ventilate" 2 "power & heater" 1 "power" 0 "manual";
VAL_ 858 BD_DSEAT_AntiAct_Sta 1 "Antitheft is activate" 0 "Antitheft is deactivate";
VAL_ 858 BD_DSEAT_Anti_Sta 1 "on" 0 "off";
VAL_ 858 BD_DSEAT_EntryAct_Sta 1 "Entry Function is activate" 0 "Entry Function is deactivate";
VAL_ 858 BD_DSEAT_EntryFun_Sta 1 "on" 0 "off";
VAL_ 858 BD_DSEAT_Error_Sta 1 "Warning Request(IVI POP UP)" 0 "Normal";
VAL_ 858 BD_DSEAT_Vent_Sta 3 "3(High)" 2 "2(Middle)" 1 "1(Low)" 0 "OFF";
VAL_ 858 BD_DSEAT_heater_Sta 3 "3(High)" 2 "2(Middle)" 1 "1(Low)" 0 "OFF";
VAL_ 858 BD_DSEAT_MemSet_Sta 3 "Wait For Set" 2 "Mem2 Set" 1 "Mem1 Set" 0 "Stand By";
VAL_ 858 BD_DSEAT_StopKeepMove_Sta 3 "No Request" 2 "Stop" 1 "Moving" 0 "In position";
VAL_ 1287 NM_BodyZone_DR_Rpt_Msg_Req 1 "Repeat Message State requested" 0 "Repeat Message State not requested";
VAL_ 1287 NM_BodyZone_DR_CSB 1 "Start of synchronized shutdown is requested by main coordinator" 0 "Start of synchronized shutdown is not requested by main coordinator";
VAL_ 1287 NM_BodyZone_DR_Active_WU 1 "Node has woken up the network (active Wakeup)" 0 "Node has not woken up the network (passive wakeup)";
VAL_ 1287 NM_BodyZone_DR_PNI 1 "NM PDU contains Partial Network request information" 0 "NM PDU contains no Partial Network request information";
VAL_ 1287 NM_BodyZone_DR_ERROR_State 8 "BUS OFF_L2" 4 "BUS OFF_L1" 2 "ERROR PASSIVE" 1 "ERROR ACTIVE" 0 "Inactive";
VAL_ 859 BP_PTG_PowerLatch_Sta 7 "Signal Not Available" 6 "Invalid" 5 "Release reset" 4 "Release" 3 "Cinching reset" 2 "Cinching" 1 "Stoped" 0 "Uninitialized";
VAL_ 859 BP_PTG_DebugMode_Sta 1 "1" 0 "0";
VAL_ 859 BP_PTG_LatchSeg_Sta 3 "Signal Not Available" 2 "Open Latch" 1 "Half Latch" 0 "Full Latch";
VAL_ 859 BP_PTG_InsideSW2_Sta 3 "Stuck" 2 "Long Press" 1 "Press" 0 "Release";
VAL_ 859 BP_PTG_InsideSW1_Sta 3 "Stuck" 2 "Long Press" 1 "Press" 0 "Release";
VAL_ 859 BP_PTG_HalfSW_Sta 1 "GND" 0 "Open";
VAL_ 859 BP_PTG_LeftDuty_Sta 127 "127%(Uninitialized)" 100 "100%(Max)" 0 "0%(Min)";
VAL_ 859 BP_PTG_FullSW_Sta 1 "GND" 0 "Open";
VAL_ 859 BP_PTG_RightDuty_Sta 127 "127%(Uninitialized)" 100 "100%(Max)" 0 "0%(Min)";
VAL_ 859 BP_PTG_NtlSW_Sta 1 "GND" 0 "Open";
VAL_ 859 BP_PTG_CinchDuty_Sta 127 "127%(Uninitialized)" 100 "100%(Max)" 0 "0%(Min)";
VAL_ 859 BP_PTG_StrutThermal_Sta 1 "Active" 0 "Not active";
VAL_ 859 BP_PTG_LeftCur_Sta 32767 "Invalid";
VAL_ 859 BP_PTG_StrutAntiPinch_Sta 1 "Active" 0 "Not active";
VAL_ 859 BP_PTG_RightCur_Sta 32767 "Invalid";
VAL_ 859 BP_PTG_StrutStall_Sta 1 "Active" 0 "Not active";
VAL_ 859 BP_PTG_CinchCur_Sta 32767 "Invalid";
VAL_ 859 BP_PTG_AbuseProtection_Sta 1 "Active" 0 "Not active";
VAL_ 859 BP_PTG_ReleaseCur_Sta 32767 "Invalid";
VAL_ 859 BP_PTG_LatchThermal_Sta 1 "Active" 0 "Not active";
VAL_ 859 BP_PTG_LeftHallPosn_Sta 1023 "Invalid";
VAL_ 859 BP_PTG_ErrLeftStrut_Sta 2 "Short circuit" 1 "Open circuit" 0 "Normal";
VAL_ 859 BP_PTG_ErrVoltage_Sta 2 "Over voltage" 1 "Uuder voltage" 0 "Normal";
VAL_ 859 BP_PTG_ErrRightStrut_Sta 2 "Short circuit" 1 "Open circuit" 0 "Normal";
VAL_ 859 BP_PTG_RightHallPosn_Sta 1023 "Invalid";
VAL_ 859 BP_PTG_ErrHall_Sta 3 "Hall signal out of sync" 2 "Hall position out of range" 1 "Hall power short circuit" 0 "Normal";
VAL_ 859 BP_PTG_ErrLatch_Sta 2 "Short circuit" 1 "Open circuit" 0 "Normal";
VAL_ 859 BP_PTG_OpenRatio_Sta 127 "127% (Invalid)" 100 "100% (Max)" 0 "0% (Min)";
VAL_ 859 BP_PTG_Active_Sta 7 "Pinch Reverse" 6 "Stoped Halfway" 5 "Ready to Act" 4 "Power Closing" 3 "Power Opening" 2 "Fully Opened" 1 "Fully Closed" 0 "Signal Not Available";
VAL_ 859 BP_PTG_Sys_Sta 3 "Signal Not Available" 2 "Abnormal" 1 "Normal" 0 "Uninitialized";
VAL_ 859 BP_PTG_RDIL_Cmd 3 "Invalid" 2 "Flash 3 times" 1 "Flash twice" 0 "No request";
VAL_ 859 BP_PTG_IsSetHeight_Sta 1 "On" 0 "Off";
VAL_ 859 BP_PTG_Exist_Sta 1 "Exist" 0 "Not Exist";
VAL_ 859 BP_PSEAT_Vent_Sta 3 "3(High)" 2 "2(Middle)" 1 "1(Low)" 0 "OFF";
VAL_ 859 BP_PSEAT_Mode_Sta 7 "manual & heater & ventilate" 6 "manual & ventilate" 5 "manual & heater" 4 "power & heater & ventilate" 3 "power & ventilate" 2 "power & heater" 1 "power" 0 "manual";
VAL_ 859 BP_PSEAT_Error_Sta 1 "Warning Request (IVI POP UP)" 0 "Normal";
VAL_ 859 BP_PSEAT_heater_Sta 3 "3(High)" 2 "2(Middle)" 1 "1(Low)" 0 "OFF";
VAL_ 1007 BP_SEAT_HeatCurrent_Sta 255 "Invalid";
VAL_ 1007 BP_SEAT_VentCurrent_Sta 255 "Invalid";
VAL_ 1007 BP_Door_RCurrent_Sta 255 "Invalid";
VAL_ 1007 BP_Door_FCurrent_Sta 255 "Invalid";
VAL_ 1007 BP_SEAT_ReclineCurrent_Sta 255 "Invalid";
VAL_ 1007 BP_SEAT_SlideCurrent_Sta 255 "Invalid";
VAL_ 1007 BP_PSEAT_HeaterTemp_Sta 255 "Invalid";
VAL_ 1007 BP_PTG_ACTRLatchCur_Sta 255 "Invalid";
VAL_ 795 BP_APM_WinFOpened_Sta 127 "Invalid" 102 "-0x7E undefined";
VAL_ 795 BP_APM_WinROpened_Sta 127 "Invalid" 102 "-0x7E undefined";
VAL_ 795 BP_Door_FHandleClose_Sta 1 "Close" 0 "Not Close";
VAL_ 795 BP_Door_FHandleHalf_Sta 1 "Open" 0 "Not Open";
VAL_ 795 BP_Door_RHandleClose_Sta 1 "Close" 0 "Not Close";
VAL_ 795 BP_Door_RHandleHalf_Sta 1 "Open" 0 "Not Open";
VAL_ 795 BP_SEAT_MLVent_Sta 4 "OFF" 3 "3(High)" 2 "2(Middle)" 1 "1(Low)" 0 "NoRequest";
VAL_ 795 BP_SEAT_MRVent_Sta 4 "OFF" 3 "3(High)" 2 "2(Middle)" 1 "1(Low)" 0 "NoRequest";
VAL_ 795 BP_SEAT_LVent_Sta 4 "OFF" 3 "3(High)" 2 "2(Middle)" 1 "1(Low)" 0 "NoRequest";
VAL_ 795 BP_SEAT_RVent_Sta 4 "OFF" 3 "3(High)" 2 "2(Middle)" 1 "1(Low)" 0 "NoRequest";
VAL_ 1286 NM_BodyZone_PS_Rpt_Msg_Req 1 "Repeat Message State requested" 0 "Repeat Message State not requested";
VAL_ 1286 NM_BodyZone_PS_CSB 1 "Start of synchronized shutdown is requested by main coordinator" 0 "Start of synchronized shutdown is not requested by main coordinator";
VAL_ 1286 NM_BodyZone_PS_Active_WU 1 "Node has woken up the network (active Wakeup)" 0 "Node has not woken up the network (passive wakeup)";
VAL_ 1286 NM_BodyZone_PS_PNI 1 "NM PDU contains Partial Network request information" 0 "NM PDU contains no Partial Network request information";
VAL_ 1286 NM_BodyZone_PS_ERROR_State 8 "BUS OFF_L2" 4 "BUS OFF_L1" 2 "ERROR PASSIVE" 1 "ERROR ACTIVE" 0 "Inactive";
VAL_ 376 ADB_ILLAmbtSta 3 "Error indicator" 2 "Not used" 1 "Dark" 0 "Bright";
VAL_ 376 ADB_VehNumVal 15 "Error indicator" 14 "Default" 13 "Reserved" 12 "Reserved" 11 "Over than 10 vehicles" 0 "No vehicle";
VAL_ 376 ADB_FR_CMR_Sta 3 "Error Indicator" 2 "Blockage Status" 1 "Normal" 0 "None Option (Default)";
VAL_ 376 ADB_VehLtAngl1Val 511 "Error indicator" 510 "Default" 509 "Not used" 508 "Not used" 507 "Not used" 506 "Not used" 505 "Not used" 504 "Not used" 503 "Not used" 502 "Not used" 501 "Not used" 500 "-25.0~+25.0" 0 "-25.0~+25.0";
VAL_ 376 ADB_VehRtAngl1Val 511 "Error indicator" 510 "Default" 509 "Not used" 508 "Not used" 507 "Not used" 506 "Not used" 505 "Not used" 504 "Not used" 503 "Not used" 502 "Not used" 501 "Not used" 500 "-25.0~+25.0" 0 "-25.0~+25.0";
VAL_ 376 ADB_VehLtAngl2Val 511 "Error indicator" 510 "Default" 509 "Not used" 508 "Not used" 507 "Not used" 506 "Not used" 505 "Not used" 504 "Not used" 503 "Not used" 502 "Not used" 501 "Not used" 500 "-25.0~+25.0" 0 "-25.0~+25.0";
VAL_ 376 ADB_VehRtAngl2Val 511 "Error indicator" 510 "Default" 509 "Not used" 508 "Not used" 507 "Not used" 506 "Not used" 505 "Not used" 504 "Not used" 503 "Not used" 502 "Not used" 501 "Not used" 500 "-25.0~+25.0" 0 "-25.0~+25.0";
VAL_ 376 ADB_VehLtAngl3Val 511 "Error indicator" 510 "Default" 509 "Not used" 508 "Not used" 507 "Not used" 506 "Not used" 505 "Not used" 504 "Not used" 503 "Not used" 502 "Not used" 501 "Not used" 500 "-25.0~+25.0" 0 "-25.0~+25.0";
VAL_ 376 ADB_VehRtAngl3Val 511 "Error indicator" 510 "Default" 509 "Not used" 508 "Not used" 507 "Not used" 506 "Not used" 505 "Not used" 504 "Not used" 503 "Not used" 502 "Not used" 501 "Not used" 500 "-25.0~+25.0" 0 "-25.0~+25.0";
VAL_ 376 ADB_VehLtAngl4Val 511 "Error indicator" 510 "Default" 509 "Not used" 508 "Not used" 507 "Not used" 506 "Not used" 505 "Not used" 504 "Not used" 503 "Not used" 502 "Not used" 501 "Not used" 500 "-25.0~+25.0" 0 "-25.0~+25.0";
VAL_ 376 ADB_VehRtAngl4Val 511 "Error indicator" 510 "Default" 509 "Not used" 508 "Not used" 507 "Not used" 506 "Not used" 505 "Not used" 504 "Not used" 503 "Not used" 502 "Not used" 501 "Not used" 500 "-25.0~+25.0" 0 "-25.0~+25.0";
VAL_ 376 ADB_VehLtAngl5Val 511 "Error indicator" 510 "Default" 509 "Not used" 508 "Not used" 507 "Not used" 506 "Not used" 505 "Not used" 504 "Not used" 503 "Not used" 502 "Not used" 501 "Not used" 500 "-25.0~+25.0" 0 "-25.0~+25.0";
VAL_ 376 ADB_VehRtAngl5Val 511 "Error indicator" 510 "Default" 509 "Not used" 508 "Not used" 507 "Not used" 506 "Not used" 505 "Not used" 504 "Not used" 503 "Not used" 502 "Not used" 501 "Not used" 500 "-25.0~+25.0" 0 "-25.0~+25.0";
VAL_ 376 ADB_VehLtAngl6Val 511 "Error indicator" 510 "Default" 509 "Not used" 508 "Not used" 507 "Not used" 506 "Not used" 505 "Not used" 504 "Not used" 503 "Not used" 502 "Not used" 501 "Not used" 500 "-25.0~+25.0" 0 "-25.0~+25.0";
VAL_ 376 ADB_VehRtAngl6Val 511 "Error indicator" 510 "Default" 509 "Not used" 508 "Not used" 507 "Not used" 506 "Not used" 505 "Not used" 504 "Not used" 503 "Not used" 502 "Not used" 501 "Not used" 500 "-25.0~+25.0" 0 "-25.0~+25.0";
VAL_ 376 ADB_VehLtAngl7Val 511 "Error indicator" 510 "Default" 509 "Not used" 508 "Not used" 507 "Not used" 506 "Not used" 505 "Not used" 504 "Not used" 503 "Not used" 502 "Not used" 501 "Not used" 500 "-25.0~+25.0" 0 "-25.0~+25.0";
VAL_ 376 ADB_VehRtAngl7Val 511 "Error indicator" 510 "Default" 509 "Not used" 508 "Not used" 507 "Not used" 506 "Not used" 505 "Not used" 504 "Not used" 503 "Not used" 502 "Not used" 501 "Not used" 500 "-25.0~+25.0" 0 "-25.0~+25.0";
VAL_ 376 ADB_VehLtAngl8Val 511 "Error indicator" 510 "Default" 509 "Not used" 508 "Not used" 507 "Not used" 506 "Not used" 505 "Not used" 504 "Not used" 503 "Not used" 502 "Not used" 501 "Not used" 500 "-25.0~+25.0" 0 "-25.0~+25.0";
VAL_ 376 ADB_VehRtAngl8Val 511 "Error indicator" 510 "Default" 509 "Not used" 508 "Not used" 507 "Not used" 506 "Not used" 505 "Not used" 504 "Not used" 503 "Not used" 502 "Not used" 501 "Not used" 500 "-25.0~+25.0" 0 "-25.0~+25.0";
VAL_ 376 ADB_VehLtAngl9Val 511 "Error indicator" 510 "Default" 509 "Not used" 508 "Not used" 507 "Not used" 506 "Not used" 505 "Not used" 504 "Not used" 503 "Not used" 502 "Not used" 501 "Not used" 500 "-25.0~+25.0" 0 "-25.0~+25.0";
VAL_ 376 ADB_VehRtAngl9Val 511 "Error indicator" 510 "Default" 509 "Not used" 508 "Not used" 507 "Not used" 506 "Not used" 505 "Not used" 504 "Not used" 503 "Not used" 502 "Not used" 501 "Not used" 500 "-25.0~+25.0" 0 "-25.0~+25.0";
VAL_ 376 ADB_VehLtAngl10Val 511 "Error indicator" 510 "Default" 509 "Not used" 508 "Not used" 507 "Not used" 506 "Not used" 505 "Not used" 504 "Not used" 503 "Not used" 502 "Not used" 501 "Not used" 500 "-25.0~+25.0" 0 "-25.0~+25.0";
VAL_ 376 ADB_VehRtAngl10Val 511 "Error indicator" 510 "Default" 509 "Not used" 508 "Not used" 507 "Not used" 506 "Not used" 505 "Not used" 504 "Not used" 503 "Not used" 502 "Not used" 501 "Not used" 500 "-25.0~+25.0" 0 "-25.0~+25.0";
VAL_ 376 ADB_VehDst1Val 15 "Error indicator" 14 "401m~" 13 "301~400m" 12 "201~300m" 11 "101~200m" 10 "91~100m" 9 "81~90m" 8 "71~80m" 7 "61~70m" 6 "51~60m" 5 "41~50m" 4 "31~40m" 3 "21~30m" 2 "11~20m" 1 "1~10m" 0 "No Value";
VAL_ 376 ADB_VehDst3Val 15 "Error indicator" 14 "401m~" 13 "301~400m" 12 "201~300m" 11 "101~200m" 10 "91~100m" 9 "81~90m" 8 "71~80m" 7 "61~70m" 6 "51~60m" 5 "41~50m" 4 "31~40m" 3 "21~30m" 2 "11~20m" 1 "1~10m" 0 "No Value";
VAL_ 376 ADB_VehDst2Val 15 "Error indicator" 14 "401m~" 13 "301~400m" 12 "201~300m" 11 "101~200m" 10 "91~100m" 9 "81~90m" 8 "71~80m" 7 "61~70m" 6 "51~60m" 5 "41~50m" 4 "31~40m" 3 "21~30m" 2 "11~20m" 1 "1~10m" 0 "No Value";
VAL_ 376 ADB_VehDst5Val 15 "Error indicator" 14 "401m~" 13 "301~400m" 12 "201~300m" 11 "101~200m" 10 "91~100m" 9 "81~90m" 8 "71~80m" 7 "61~70m" 6 "51~60m" 5 "41~50m" 4 "31~40m" 3 "21~30m" 2 "11~20m" 1 "1~10m" 0 "No Value";
VAL_ 376 ADB_VehDst4Val 15 "Error indicator" 14 "401m~" 13 "301~400m" 12 "201~300m" 11 "101~200m" 10 "91~100m" 9 "81~90m" 8 "71~80m" 7 "61~70m" 6 "51~60m" 5 "41~50m" 4 "31~40m" 3 "21~30m" 2 "11~20m" 1 "1~10m" 0 "No Value";
VAL_ 376 ADB_VehDst7Val 15 "Error indicator" 14 "401m~" 13 "301~400m" 12 "201~300m" 11 "101~200m" 10 "91~100m" 9 "81~90m" 8 "71~80m" 7 "61~70m" 6 "51~60m" 5 "41~50m" 4 "31~40m" 3 "21~30m" 2 "11~20m" 1 "1~10m" 0 "No Value";
VAL_ 376 ADB_VehDst6Val 15 "Error indicator" 14 "401m~" 13 "301~400m" 12 "201~300m" 11 "101~200m" 10 "91~100m" 9 "81~90m" 8 "71~80m" 7 "61~70m" 6 "51~60m" 5 "41~50m" 4 "31~40m" 3 "21~30m" 2 "11~20m" 1 "1~10m" 0 "No Value";
VAL_ 376 ADB_VehDst9Val 15 "Error indicator" 14 "401m~" 13 "301~400m" 12 "201~300m" 11 "101~200m" 10 "91~100m" 9 "81~90m" 8 "71~80m" 7 "61~70m" 6 "51~60m" 5 "41~50m" 4 "31~40m" 3 "21~30m" 2 "11~20m" 1 "1~10m" 0 "No Value";
VAL_ 376 ADB_VehDst8Val 15 "Error indicator" 14 "401m~" 13 "301~400m" 12 "201~300m" 11 "101~200m" 10 "91~100m" 9 "81~90m" 8 "71~80m" 7 "61~70m" 6 "51~60m" 5 "41~50m" 4 "31~40m" 3 "21~30m" 2 "11~20m" 1 "1~10m" 0 "No Value";
VAL_ 376 ADB_VehDst10Val 15 "Error indicator" 14 "401m~" 13 "301~400m" 12 "201~300m" 11 "101~200m" 10 "91~100m" 9 "81~90m" 8 "71~80m" 7 "61~70m" 6 "51~60m" 5 "41~50m" 4 "31~40m" 3 "21~30m" 2 "11~20m" 1 "1~10m" 0 "No Value";
VAL_ 881 PTG_Half_Lock 1 "On" 0 "Off";
VAL_ 881 PTG_Open_Ratio 127 "127% (Invalid)" 100 "100% (Max)" 0 "0% (Min)";
VAL_ 881 PTG_Full_Lock 1 "On" 0 "Off";
VAL_ 881 PTG_Active_Sta 7 "Pinch Reverse" 6 "Stoped Halfway" 5 "Ready to Act" 4 "Power Closing" 3 "Power Opening" 2 "Fully Opened" 1 "Fully Closed" 0 "Signal Not Available";
VAL_ 881 PTG_Warning_Sta 7 "Reserved" 6 "User Operation Denied" 5 "User Operation Accepted" 4 "Memory position" 3 "Warning" 2 "Forced stop" 1 "Antipinch reverse" 0 "Off";
VAL_ 881 PTG_RDIL_Sta 3 "Invalid" 2 "Flash 3 times" 1 "Flash twice" 0 "No request";
VAL_ 881 PTG_Inner_SW_2 3 "Stuck" 2 "Press&Hold" 1 "Push" 0 "Off";
VAL_ 881 PTG_Inner_SW_1 3 "Stuck" 2 "Press&Hold" 1 "Push" 0 "Off";
VAL_ 881 PTG_Sys_Sta 3 "Signal Not Available" 2 "Abnormal" 1 "Normal" 0 "Uninitialized";
VAL_ 881 PTG_Is_Set_Height 1 "On" 0 "Off";
VAL_ 881 PTG_AutoStaus 1 "Auto mode" 0 "Manual mode";
VAL_ 881 PTG_Exist 1 "Exist" 0 "Not Exist";
VAL_ 881 PTG_SW_Ver 31 "V31" 1 "V1" 0 "Invalid";
VAL_ 881 PTG_HW_Ver 31 "V31" 1 "V1" 0 "Invalid";
VAL_ 854 DSEAT_Slid_Pos 255 "Invalid";
VAL_ 854 DSEAT_RL_Pos 255 "Invalid";
VAL_ 854 DSEAT_Rec_Pos 255 "Invalid";
VAL_ 854 DSEAT_FL_Pos 255 "Invaild";
VAL_ 854 DSEAT_heater_sta 4 "OFF" 3 "High" 2 "Middle" 1 "Low" 0 "No request";
VAL_ 854 DSEAT_Mode 7 "manual & heater & ventilate" 6 "manual & ventilate" 5 "manual & heater" 4 "power & heater & ventilate" 3 "power & ventilate" 2 "power & heater" 1 "power" 0 "manual";
VAL_ 854 DSEAT_Vent_Sta 4 "OFF" 3 "3(High)" 2 "2(Middle)" 1 "1(Low)" 0 "No Request";
VAL_ 854 PSEAT_heater_sta 4 "OFF" 3 "High" 2 "Middle" 1 "Low" 0 "No request";
VAL_ 854 PSEAT_Mode 7 "manual & heater & ventilate" 6 "manual & ventilate" 5 "manual & heater" 4 "power & heater & ventilate" 3 "power & ventilate" 2 "power & heater" 1 "power" 0 "manual";
VAL_ 854 PSEAT_Vent_Sta 4 "OFF" 3 "3(High)" 2 "2(Middle)" 1 "1(Low)" 0 "No Request";
VAL_ 854 DSEAT_AntiAct_Sta 1 "Antitheft is activate" 0 "Antitheft is deactivate";
VAL_ 854 DSEAT_Anti_Sta 1 "on" 0 "off";
VAL_ 854 DSEAT_EntryAct_Sta 1 "Entry Function is activate" 0 "Entry Function is deactivate";
VAL_ 854 DSEAT_EntryFun_Sta 1 "on" 0 "off";
VAL_ 854 DSEAT_Error_Sta 1 "Warning Request(IVI POP UP)" 0 "Normal";
VAL_ 854 PSEAT_Error_Sta 1 "Warning Request (IVI POP UP)" 0 "Normal";
VAL_ 630 OBCACCSLimit 255 "Invalid";
VAL_ 630 ReChargerStaFromEvcc 3 "Invalid" 2 "Untrusted" 1 "On" 0 "Off";
VAL_ 630 OBCEna 1 "Start charging" 0 "Stop charging";
VAL_ 1006 BD_SEAT_VentCurrent_Sta 255 "Invalid";
VAL_ 1006 BD_SEAT_HeatCurrent_Sta 255 "Invalid";
VAL_ 1006 BD_SEAT_FrontLiftCurrent_Sta 255 "Invalid";
VAL_ 1006 BD_SEAT_RearLiftCurrent_Sta 255 "Invalid";
VAL_ 1006 BD_SEAT_ReclineCurrent_Sta 255 "Invalid";
VAL_ 1006 BD_SEAT_SlideCurrent_Sta 255 "Invalid";
VAL_ 1006 BD_Door_RCurrent_Sta 255 "Invalid";
VAL_ 1006 BD_Door_FCurrent_Sta 255 "Invalid";
VAL_ 1006 BD_DSEAT_HeaterTemp_Sta 255 "Invalid";
VAL_ 928 FDC_VCU_ReqHWReset_Cmd 25 "EBM power off" 24 "ECompressor power off" 23 "WPTC power off" 22 "HMI power off" 21 "TBox power off" 20 "IVI power off" 19 "AirPTC power off" 18 "PSEAT power off" 17 "DSEAT power off" 16 "ABM power off" 15 "EPS power off" 14 "BMS power off" 13 "EOP_F power off" 12 "EOP_R power off" 11 "CCU power off" 10 "DKC power off" 9 "MRR power off" 8 "SRR_M power off" 7 "FCM power off" 6 "MCU_F power off" 5 "MCU_R power off" 4 "Shifter power off" 3 "Telltale power off" 2 "EBST power off" 1 "ESC power off" 0 "No request";
VAL_ 1345 NM_ZONE_ML_ERROR_State 8 "BUS OFF_L2" 4 "BUS OFF_L1" 2 "ERROR PASSIVE" 1 "ERROR ACTIVE" 0 "Inactive";
VAL_ 1345 NM_ZONE_ML_Active_WU 1 "Node has woken up the network (active Wakeup)" 0 "Node has not woken up the network (passive wakeup)";
VAL_ 1345 NM_ZONE_ML_CSB 1 "Start of synchronized shutdown is requested by main coordinator" 0 "Start of synchronized shutdown is not requested by main coordinator";
VAL_ 1345 NM_ZONE_ML_PNI 1 "NM PDU contains Partial Network request information" 0 "NM PDU contains no Partial Network request information";
VAL_ 1345 NM_ZONE_ML_Rpt_Msg_Req 1 "Repeat Message State requested" 0 "Repeat Message State not requested";
VAL_ 1346 NM_ZONE_MR_ERROR_State 8 "BUS OFF_L2" 4 "BUS OFF_L1" 2 "ERROR PASSIVE" 1 "ERROR ACTIVE" 0 "Inactive";
VAL_ 1346 NM_ZONE_MR_Active_WU 1 "Node has woken up the network (active Wakeup)" 0 "Node has not woken up the network (passive wakeup)";
VAL_ 1346 NM_ZONE_MR_CSB 1 "Start of synchronized shutdown is requested by main coordinator" 0 "Start of synchronized shutdown is not requested by main coordinator";
VAL_ 1346 NM_ZONE_MR_PNI 1 "NM PDU contains Partial Network request information" 0 "NM PDU contains no Partial Network request information";
VAL_ 1346 NM_ZONE_MR_Rpt_Msg_Req 1 "Repeat Message State requested" 0 "Repeat Message State not requested";
VAL_ 597 IVI_MLSEATvent_Cmd 4 "OFF" 3 "3(High)" 2 "2(Middle)" 1 "1(Low)" 0 "NoRequest";
VAL_ 597 IVI_MRSEATvent_Cmd 4 "OFF" 3 "3(High)" 2 "2(Middle)" 1 "1(Low)" 0 "NoRequest";
VAL_ 597 IVI_MLFootLift_Cmd 2 "Down" 1 "Up" 0 "StandBy";
VAL_ 597 IVI_MLRecliner_Cmd 2 "Backward" 1 "Forward" 0 "StandBy";
VAL_ 597 IVI_MLSeatLift_Cmd 2 "Down" 1 "Up" 0 "StandBy";
VAL_ 597 IVI_MLSlider_Cmd 2 "Backward" 1 "Forward" 0 "StandBy";
VAL_ 597 IVI_MRFootLift_Cmd 2 "Down" 1 "Up" 0 "StandBy";
VAL_ 597 IVI_MRRecliner_Cmd 2 "Backward" 1 "Forward" 0 "StandBy";
VAL_ 597 IVI_MRSeatLift_Cmd 2 "Down" 1 "Up" 0 "StandBy";
VAL_ 597 IVI_MRSlider_Cmd 2 "Backward" 1 "Forward" 0 "StandBy";
VAL_ 597 IVI_MLFMost_Cmd 1 "Press" 0 "Release";
VAL_ 597 IVI_MLNapMode_Cmd 1 "Press" 0 "Release";
VAL_ 597 IVI_MLRestore_Cmd 1 "Press" 0 "Release";
VAL_ 597 IVI_MLSldRestore_Cmd 1 "Press" 0 "Release";
VAL_ 597 IVI_MLZeroGravity_Cmd 1 "Press" 0 "Release";
VAL_ 597 IVI_MRFMost_Cmd 1 "Press" 0 "Release";
VAL_ 597 IVI_MRNapMode_Cmd 1 "Press" 0 "Release";
VAL_ 597 IVI_MRRestore_Cmd 1 "Press" 0 "Release";
VAL_ 597 IVI_MRSldRestore_Cmd 1 "Press" 0 "Release";
VAL_ 597 IVI_MRZeroGravity_Cmd 1 "Press" 0 "Release";
VAL_ 597 IVI_LSEATvent_Cmd 4 "OFF" 3 "3(High)" 2 "2(Middle)" 1 "1(Low)" 0 "NoRequest";
VAL_ 597 IVI_RSEATvent_Cmd 4 "OFF" 3 "3(High)" 2 "2(Middle)" 1 "1(Low)" 0 "NoRequest";
VAL_ 953 ZFR_SYS_BoardBatVolt_Sta 4095 "Invalid";
VAL_ 953 ZFR_SYS_U155Temp_Sta 4095 "Invalid";
VAL_ 953 ZFR_SYS_U156Temp_Sta 4095 "Invalid";
VAL_ 953 ZFR_SYS_U5Temp_Sta 4095 "Invalid";
VAL_ 949 ZDR_SYS_BoardBatVolt_Sta 4095 "Invalid";
VAL_ 949 ZDR_SYS_U155Temp_Sta 4095 "Invalid";
VAL_ 949 ZDR_SYS_U156Temp_Sta 4095 "Invalid";
VAL_ 949 ZDR_SYS_U5Temp_Sta 4095 "Invalid";
